VERSION ""

NS_ :

BS_:

BU_: DMC

BO_ 3221225472 VECTOR__INDEPENDENT_SIG_MSG: 0 Vector__XXX
 SG_ Reserved_4 : 0|8@0+ (1,0) [0|0] "" Vector__XXX
 SG_ AdasSignType_reserve : 0|41@0+ (1,0) [0|0] "" Vector__XXX

BO_ 1441 IHU_40: 8 DMC
 SG_ IHU_40_WSOSSwtSet : 5|2@0+ (1,0) [0|3] "" Vector__XXX
 SG_ IHU_40_IDSSwtSet : 7|2@0+ (1,0) [0|3] "" Vector__XXX

BO_ 636 EMS_CGW_1: 8 Vector__XXX
 SG_ EMS_EngineSpeed_Actual : 7|16@0+ (0.25,0) [0|16383] "rpm"  DMC

BO_ 2015 DMC_REQ1_Broadcast: 8 DMC
 SG_ DMC_REQ1_Broadcast : 7|64@0+ (1,0) [0|0] "" Vector__XXX

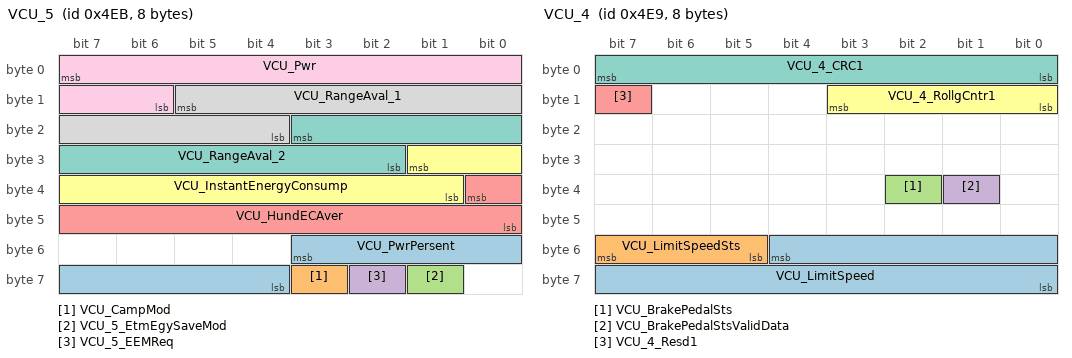
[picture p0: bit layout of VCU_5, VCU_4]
BO_ 1259 VCU_5: 8 Vector__XXX
 SG_ VCU_PwrPersent : 51|8@0+ (1,-100) [-100|100] "%"  DMC
 SG_ VCU_CampMod : 59|1@0+ (1,0) [0|1] ""  DMC
 SG_ VCU_5_EtmEgySaveMod : 57|1@0+ (1,0) [0|1] ""  DMC
 SG_ VCU_5_EEMReq : 58|1@0+ (1,0) [0|1] ""  DMC
 SG_ VCU_HundECAver : 32|9@0+ (0.1,0) [0|51] "kwh"  DMC
 SG_ VCU_InstantEnergyConsump : 25|9@0+ (0.1,0) [0|51] "kwh"  DMC
 SG_ VCU_RangeAval_2 : 19|10@0+ (1,0) [0|1022] "KM"  DMC
 SG_ VCU_RangeAval_1 : 13|10@0+ (1,0) [0|1022] "KM"  DMC
 SG_ VCU_Pwr : 7|10@0+ (1,-500) [-500|500] ""  DMC

BO_ 1257 VCU_4: 8 Vector__XXX
 SG_ VCU_LimitSpeed : 52|13@0+ (0.0625,0) [0|511.875] "km/h"  DMC
 SG_ VCU_LimitSpeedSts : 55|3@0+ (1,0) [0|7] ""  DMC
 SG_ VCU_BrakePedalSts : 34|1@0+ (1,0) [0|1] ""  DMC
 SG_ VCU_BrakePedalStsValidData : 33|1@0+ (1,0) [0|1] ""  DMC
 SG_ VCU_4_Resd1 : 15|1@0+ (1,0) [0|0] ""  DMC
 SG_ VCU_4_RollgCntr1 : 11|4@0+ (1,0) [0|15] ""  DMC
 SG_ VCU_4_CRC1 : 7|8@0+ (1,0) [0|255] ""  DMC

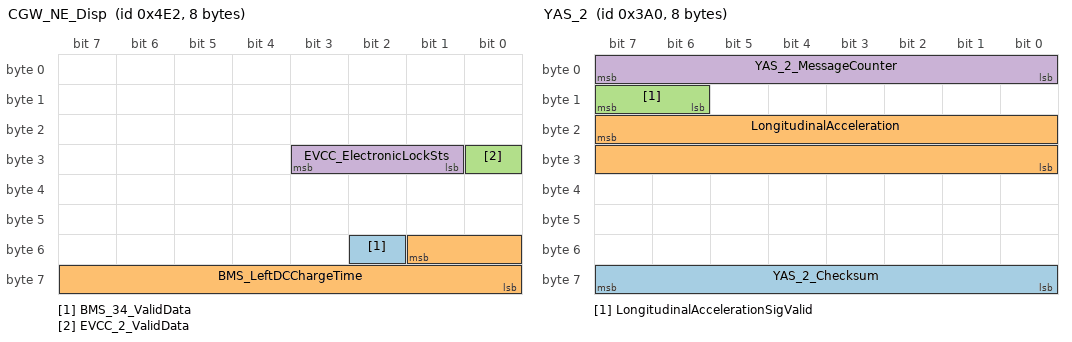
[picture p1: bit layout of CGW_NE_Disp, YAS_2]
BO_ 1250 CGW_NE_Disp: 8 Vector__XXX
 SG_ BMS_34_ValidData : 50|1@0+ (1,0) [0|1] ""  DMC
 SG_ BMS_LeftDCChargeTime : 49|10@0+ (1,0) [0|1022] "min"  DMC
 SG_ EVCC_2_ValidData : 24|1@0+ (1,0) [0|1] ""  DMC
 SG_ EVCC_ElectronicLockSts : 27|3@0+ (1,0) [0|4] ""  DMC

BO_ 928 YAS_2: 8 Vector__XXX
 SG_ YAS_2_Checksum : 63|8@0+ (1,0) [0|255] ""  DMC
 SG_ LongitudinalAcceleration : 23|16@0+ (0.001,-2) [-2|2] "g"  DMC
 SG_ LongitudinalAccelerationSigValid : 15|2@0+ (1,0) [0|3] ""  DMC
 SG_ YAS_2_MessageCounter : 7|8@0+ (1,0) [0|255] ""  DMC

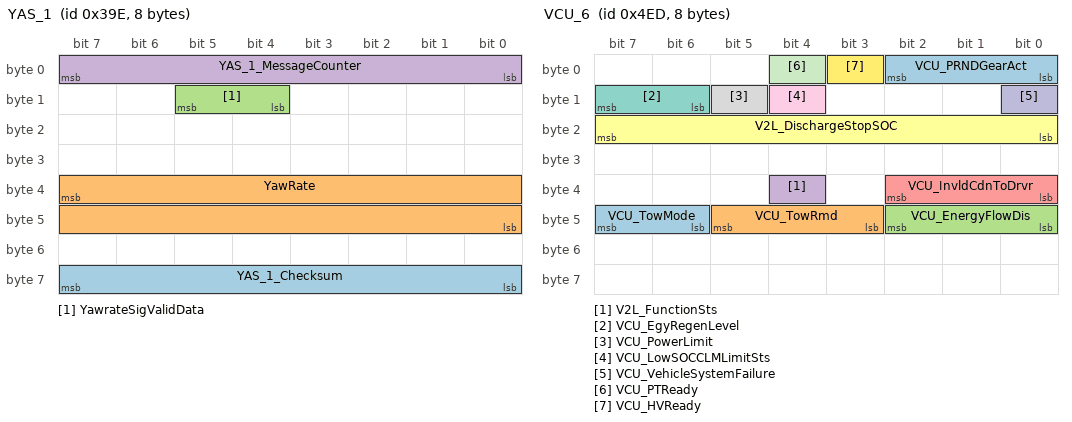
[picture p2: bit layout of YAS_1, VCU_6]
BO_ 926 YAS_1: 8 Vector__XXX
 SG_ YAS_1_Checksum : 63|8@0+ (1,0) [0|255] ""  DMC
 SG_ YawRate : 39|16@0+ (0.01,-180) [-180|180] "deg/sec"  DMC
 SG_ YawrateSigValidData : 13|2@0+ (1,0) [0|3] ""  DMC
 SG_ YAS_1_MessageCounter : 7|8@0+ (1,0) [0|255] ""  DMC

BO_ 1261 VCU_6: 8 Vector__XXX
 SG_ VCU_TowMode : 47|2@0+ (1,0) [0|3] ""  DMC
 SG_ VCU_TowRmd : 45|3@0+ (1,0) [0|7] ""  DMC
 SG_ VCU_EnergyFlowDis : 42|3@0+ (1,0) [0|7] ""  DMC
 SG_ V2L_FunctionSts : 36|1@0+ (1,0) [0|1] ""  DMC
 SG_ VCU_InvldCdnToDrvr : 34|3@0+ (1,0) [0|7] ""  DMC
 SG_ V2L_DischargeStopSOC : 23|8@0+ (1,0) [0|100] "%"  DMC
 SG_ VCU_EgyRegenLevel : 15|2@0+ (1,0) [0|3] ""  DMC
 SG_ VCU_PowerLimit : 13|1@0+ (1,0) [0|1] ""  DMC
 SG_ VCU_LowSOCCLMLimitSts : 12|1@0+ (1,0) [0|1] ""  DMC
 SG_ VCU_VehicleSystemFailure : 8|1@0+ (1,0) [0|1] ""  DMC
 SG_ VCU_PTReady : 4|1@0+ (1,0) [0|1] ""  DMC
 SG_ VCU_HVReady : 3|1@0+ (1,0) [0|1] ""  DMC
 SG_ VCU_PRNDGearAct : 2|3@0+ (1,0) [0|7] ""  DMC

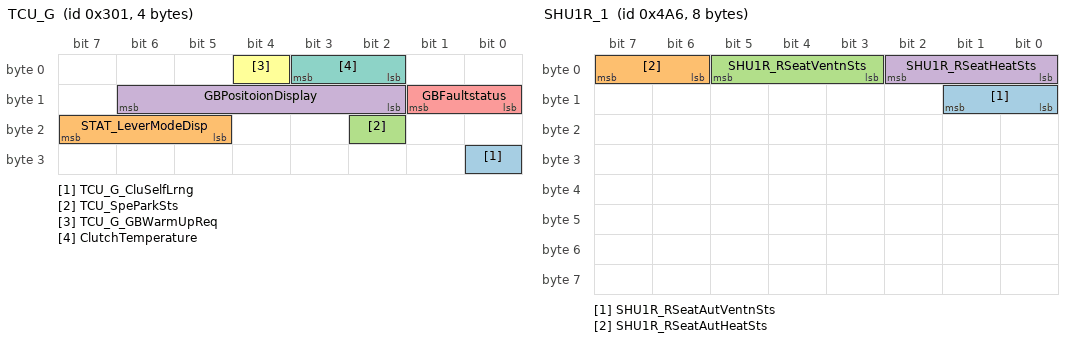
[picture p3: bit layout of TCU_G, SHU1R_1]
BO_ 769 TCU_G: 4 Vector__XXX
 SG_ TCU_G_CluSelfLrng : 24|1@0+ (1,0) [0|1] ""  DMC
 SG_ STAT_LeverModeDisp : 23|3@0+ (1,0) [0|7] ""  DMC
 SG_ TCU_SpeParkSts : 18|1@0+ (1,0) [0|1] ""  DMC
 SG_ GBPositoionDisplay : 14|5@0+ (1,0) [0|31] ""  DMC
 SG_ GBFaultstatus : 9|2@0+ (1,0) [0|3] ""  DMC
 SG_ TCU_G_GBWarmUpReq : 4|1@0+ (1,0) [0|1] ""  DMC
 SG_ ClutchTemperature : 3|2@0+ (1,0) [0|3] ""  DMC

BO_ 1206 SHU2R_1: 8 Vector__XXX
 SG_ SHU2R_RSeatVentnSts : 5|3@0+ (1,0) [0|7] ""  DMC
 SG_ SHU2R_RSeatHeatSts : 2|3@0+ (1,0) [0|7] ""  DMC

BO_ 1202 SHU2M_1: 8 Vector__XXX
 SG_ SHU2M_MSeatVentnSts : 5|3@0+ (1,0) [0|7] ""  DMC
 SG_ SHU2M_MSeatHeatSts : 2|3@0+ (1,0) [0|7] ""  DMC

BO_ 1194 SHU2L_1: 8 Vector__XXX
 SG_ SHU2L_LSeatVentnSts : 5|3@0+ (1,0) [0|7] ""  DMC
 SG_ SHU2L_LSeatHeatSts : 2|3@0+ (1,0) [0|7] ""  DMC

BO_ 1190 SHU1R_1: 8 Vector__XXX
 SG_ SHU1R_RSeatAutVentnSts : 9|2@0+ (1,0) [0|3] ""  DMC
 SG_ SHU1R_RSeatAutHeatSts : 7|2@0+ (1,0) [0|3] ""  DMC
 SG_ SHU1R_RSeatVentnSts : 5|3@0+ (1,0) [0|7] ""  DMC
 SG_ SHU1R_RSeatHeatSts : 2|3@0+ (1,0) [0|7] ""  DMC

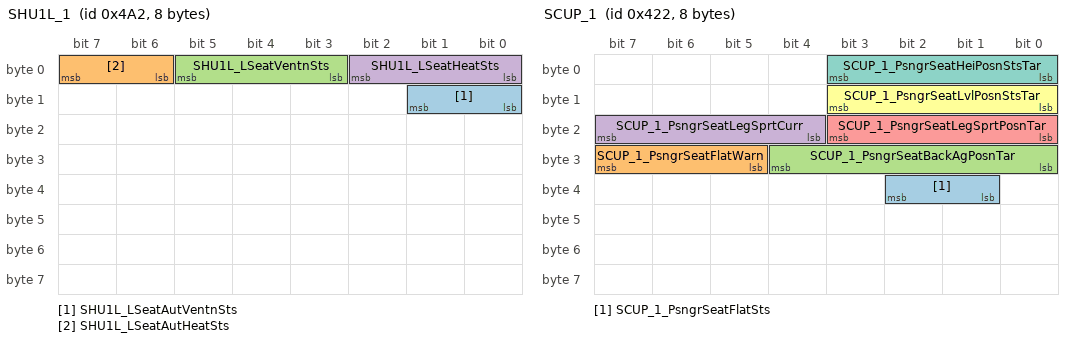
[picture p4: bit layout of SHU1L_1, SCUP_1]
BO_ 1186 SHU1L_1: 8 Vector__XXX
 SG_ SHU1L_LSeatAutVentnSts : 9|2@0+ (1,0) [0|3] ""  DMC
 SG_ SHU1L_LSeatAutHeatSts : 7|2@0+ (1,0) [0|3] ""  DMC
 SG_ SHU1L_LSeatVentnSts : 5|3@0+ (1,0) [0|7] ""  DMC
 SG_ SHU1L_LSeatHeatSts : 2|3@0+ (1,0) [0|7] ""  DMC

BO_ 1129 SCUP_2: 8 Vector__XXX
 SG_ SCUP_2_PsngrSeatMemSts : 15|2@0+ (1,0) [0|3] ""  DMC
 SG_ SCUP_2_PsngrSeatMemReq : 1|2@0+ (1,0) [0|3] ""  DMC

BO_ 1058 SCUP_1: 8 Vector__XXX
 SG_ SCUP_1_PsngrSeatFlatSts : 34|2@0+ (1,0) [0|3] ""  DMC
 SG_ SCUP_1_PsngrSeatFlatWarn : 31|3@0+ (1,0) [0|7] ""  DMC
 SG_ SCUP_1_PsngrSeatBackAgPosnTar : 28|5@0+ (1,0) [0|31] ""  DMC
 SG_ SCUP_1_PsngrSeatLegSprtCurr : 23|4@0+ (1,0) [0|15] ""  DMC
 SG_ SCUP_1_PsngrSeatLegSprtPosnTar : 19|4@0+ (1,0) [0|15] ""  DMC
 SG_ SCUP_1_PsngrSeatLvlPosnStsTar : 11|4@0+ (1,0) [0|15] ""  DMC
 SG_ SCUP_1_PsngrSeatHeiPosnStsTar : 3|4@0+ (1,0) [0|15] ""  DMC

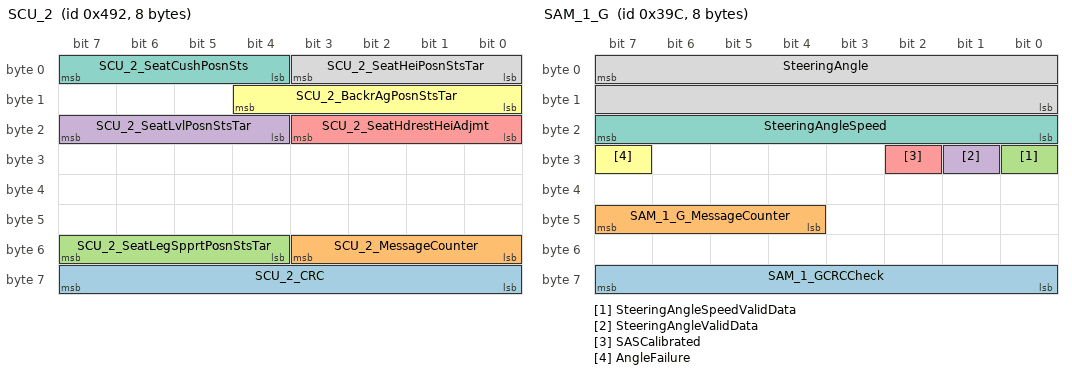
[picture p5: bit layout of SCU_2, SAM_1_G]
BO_ 1170 SCU_2: 8 Vector__XXX
 SG_ SCU_2_CRC : 63|8@0+ (1,0) [0|255] ""  DMC
 SG_ SCU_2_MessageCounter : 51|4@0+ (1,0) [0|15] ""  DMC
 SG_ SCU_2_SeatLegSpprtPosnStsTar : 55|4@0+ (1,0) [0|15] ""  DMC
 SG_ SCU_2_SeatLvlPosnStsTar : 23|4@0+ (1,0) [0|15] ""  DMC
 SG_ SCU_2_SeatHdrestHeiAdjmt : 19|4@0+ (1,0) [0|15] ""  DMC
 SG_ SCU_2_BackrAgPosnStsTar : 12|5@0+ (1,0) [0|31] ""  DMC
 SG_ SCU_2_SeatCushPosnSts : 7|4@0+ (1,0) [0|15] ""  DMC
 SG_ SCU_2_SeatHeiPosnStsTar : 3|4@0+ (1,0) [0|15] ""  DMC

BO_ 924 SAM_1_G: 8 Vector__XXX
 SG_ SAM_1_GCRCCheck : 63|8@0+ (1,0) [0|255] ""  DMC
 SG_ SAM_1_G_MessageCounter : 47|4@0+ (1,0) [0|15] ""  DMC
 SG_ SteeringAngleSpeedValidData : 24|1@0+ (1,0) [0|1] ""  DMC
 SG_ SteeringAngleValidData : 25|1@0+ (1,0) [0|1] ""  DMC
 SG_ SASCalibrated : 26|1@0+ (1,0) [0|1] ""  DMC
 SG_ AngleFailure : 31|1@0+ (1,0) [0|1] ""  DMC
 SG_ SteeringAngleSpeed : 23|8@0+ (4,0) [0|1016] "deg/Sec"  DMC
 SG_ SteeringAngle : 7|16@0+ (0.0625,-2048) [-2048|2047.875] "deg"  DMC

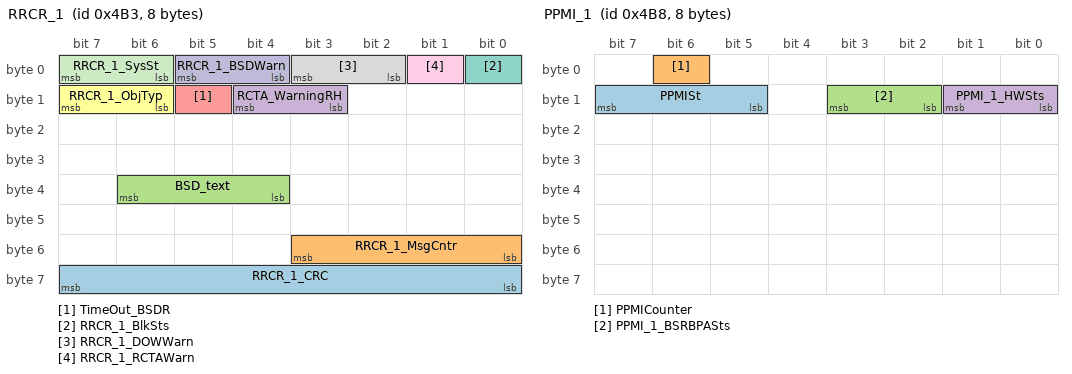
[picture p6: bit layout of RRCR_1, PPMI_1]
BO_ 1203 RRCR_1: 8 Vector__XXX
 SG_ RRCR_1_CRC : 63|8@0+ (1,0) [0|255] ""  DMC
 SG_ RRCR_1_MsgCntr : 51|4@0+ (1,0) [0|15] ""  DMC
 SG_ BSD_text : 38|3@0+ (1,0) [0|7] ""  DMC
 SG_ RCTA_WarningRH : 12|2@0+ (1,0) [0|3] ""  DMC
 SG_ TimeOut_BSDR : 13|1@0+ (1,0) [0|1] ""  DMC
 SG_ RRCR_1_ObjTyp : 15|2@0+ (1,0) [0|3] ""  DMC
 SG_ RRCR_1_BlkSts : 0|1@0+ (1,0) [0|1] ""  DMC
 SG_ RRCR_1_DOWWarn : 3|2@0+ (1,0) [0|3] ""  DMC
 SG_ RRCR_1_RCTAWarn : 1|1@0+ (1,0) [0|1] ""  DMC
 SG_ RRCR_1_BSDWarn : 5|2@0+ (1,0) [0|3] ""  DMC
 SG_ RRCR_1_SysSt : 7|2@0+ (1,0) [0|3] ""  DMC

BO_ 1075 RLCR_2_G: 8 Vector__XXX
 SG_ RLCR_2_RCTBONOFFSts : 5|2@0+ (1,0) [0|3] ""  DMC
 SG_ RLCR_2_RAEBONOFFSts : 3|2@0+ (1,0) [0|3] ""  DMC

BO_ 1201 RLCR_1: 8 Vector__XXX
 SG_ RLCR_1_CRC : 63|8@0+ (1,0) [0|255] ""  DMC
 SG_ RLCR_1_MsgCntr : 51|4@0+ (1,0) [0|15] ""  DMC
 SG_ STAT_RCTBEnable : 47|2@0+ (1,0) [0|3] ""  DMC
 SG_ DOW_Status : 45|3@0+ (1,0) [0|7] ""  DMC
 SG_ RCW_Status : 55|3@0+ (1,0) [0|7] ""  DMC
 SG_ STAT_DOWWarningMode : 35|2@0+ (1,0) [0|3] ""  DMC
 SG_ STAT_CVWWarningMode : 37|2@0+ (1,0) [0|3] ""  DMC
 SG_ RCTA_WarningLH : 39|2@0+ (1,0) [0|3] ""  DMC
 SG_ CVW_Warning : 33|2@0+ (1,0) [0|3] ""  DMC
 SG_ CVW_Status : 42|3@0+ (1,0) [0|7] ""  DMC
 SG_ BSD_Status : 31|3@0+ (1,0) [0|7] ""  DMC
 SG_ RCTA_Status : 26|3@0+ (1,0) [0|7] ""  DMC
 SG_ STAT_RCWWarningMode : 28|2@0+ (1,0) [0|3] ""  DMC
 SG_ STAT_BSDWarningMode : 17|2@0+ (1,0) [0|3] ""  DMC
 SG_ RLCR_1_ObjTyp : 9|2@0+ (1,0) [0|3] ""  DMC
 SG_ RLCR_1_RCWWarn : 11|2@0+ (1,0) [0|3] ""  DMC
 SG_ RLCR_1_DOWWarn : 13|2@0+ (1,0) [0|3] ""  DMC
 SG_ RLCR_1_RCWONOFFSts : 19|2@0+ (1,0) [0|3] ""  DMC
 SG_ RLCR_1_DOWONOFFSts : 21|2@0+ (1,0) [0|3] ""  DMC
 SG_ RLCR_1_BSDLCARCTAONOFFSts : 23|2@0+ (1,0) [0|3] ""  DMC
 SG_ RLCR_1_RCTAWarn : 0|1@0+ (1,0) [0|1] ""  DMC
 SG_ RLCR_1_BlkSts : 1|1@0+ (1,0) [0|1] ""  DMC
 SG_ RLCR_1_RAEBWarn : 4|1@0+ (1,0) [0|1] ""  DMC
 SG_ RLCR_1_RCTBWarn : 5|1@0+ (1,0) [0|1] ""  DMC
 SG_ RLCR_1_BSDWarn : 15|2@0+ (1,0) [0|3] ""  DMC
 SG_ RLCR_1_SysSt : 7|2@0+ (1,0) [0|3] ""  DMC

BO_ 1032 RCCP_1: 8 Vector__XXX
 SG_ RCCP_1_InhbSts : 7|1@0+ (1,0) [0|1] ""  DMC

BO_ 1208 PPMI_1: 8 Vector__XXX
 SG_ PPMISt : 15|3@0+ (1,0) [0|7] ""  DMC
 SG_ PPMICounter : 6|1@0+ (1,0) [0|1] ""  DMC
 SG_ PPMI_1_BSRBPASts : 11|2@0+ (1,0) [0|3] ""  DMC
 SG_ PPMI_1_HWSts : 9|2@0+ (1,0) [0|3] ""  DMC

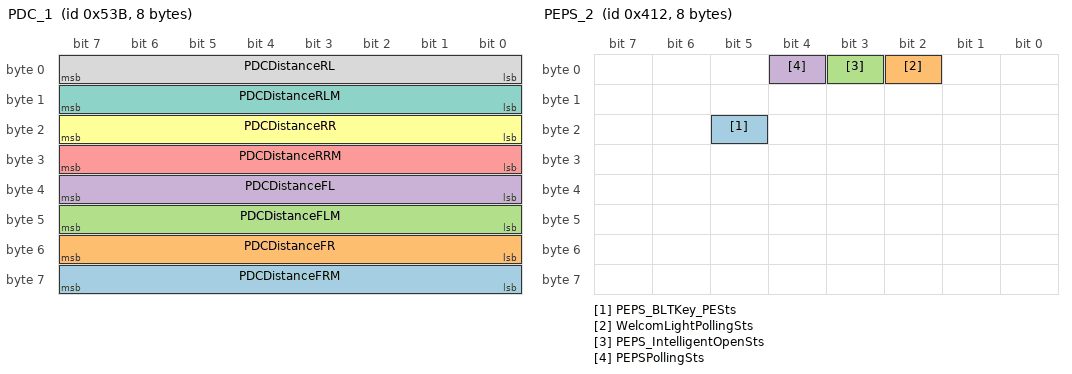
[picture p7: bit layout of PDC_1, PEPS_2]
BO_ 1339 PDC_1: 8 Vector__XXX
 SG_ PDCDistanceFRM : 63|8@0+ (1,0) [0|255] "cm"  DMC
 SG_ PDCDistanceFR : 55|8@0+ (1,0) [0|255] "cm"  DMC
 SG_ PDCDistanceFLM : 47|8@0+ (1,0) [0|255] "cm"  DMC
 SG_ PDCDistanceFL : 39|8@0+ (1,0) [0|255] "cm"  DMC
 SG_ PDCDistanceRRM : 31|8@0+ (1,0) [0|255] "cm"  DMC
 SG_ PDCDistanceRR : 23|8@0+ (1,0) [0|255] "cm"  DMC
 SG_ PDCDistanceRLM : 15|8@0+ (1,0) [0|255] "cm"  DMC
 SG_ PDCDistanceRL : 7|8@0+ (1,0) [0|255] "cm"  DMC

BO_ 1042 PEPS_2: 8 Vector__XXX
 SG_ PEPS_BLTKey_PESts : 21|1@0+ (1,0) [0|1] ""  DMC
 SG_ WelcomLightPollingSts : 2|1@0+ (1,0) [0|1] ""  DMC
 SG_ PEPS_IntelligentOpenSts : 3|1@0+ (1,0) [0|1] ""  DMC
 SG_ PEPSPollingSts : 4|1@0+ (1,0) [0|1] ""  DMC

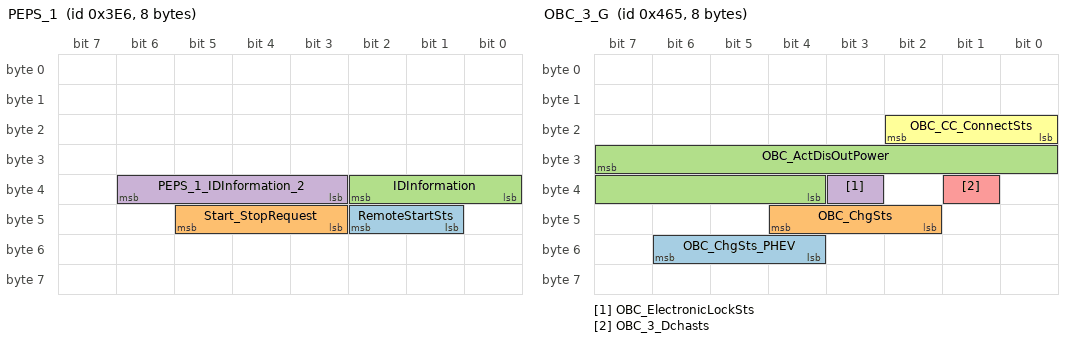
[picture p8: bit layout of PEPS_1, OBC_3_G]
BO_ 998 PEPS_1: 8 Vector__XXX
 SG_ RemoteStartSts : 42|2@0+ (1,0) [0|3] ""  DMC
 SG_ Start_StopRequest : 45|3@0+ (1,0) [0|7] ""  DMC
 SG_ IDInformation : 34|3@0+ (1,0) [0|7] ""  DMC
 SG_ PEPS_1_IDInformation_2 : 38|4@0+ (1,0) [0|10] ""  DMC

BO_ 1125 OBC_3_G: 8 Vector__XXX
 SG_ OBC_ChgSts_PHEV : 54|3@0+ (1,0) [0|7] ""  DMC
 SG_ OBC_ChgSts : 44|3@0+ (1,0) [0|7] ""  DMC
 SG_ OBC_ActDisOutPower : 31|12@0+ (0.1,0) [0|400] "KW"  DMC
 SG_ OBC_ElectronicLockSts : 35|1@0+ (1,0) [0|1] ""  DMC
 SG_ OBC_3_Dchasts : 33|1@0+ (1,0) [0|1] ""  DMC
 SG_ OBC_CC_ConnectSts : 18|3@0+ (1,0) [0|7] ""  DMC

BO_ 1124 NFC_1: 8 Vector__XXX
 SG_ NFC_1_DispCardPosn : 15|1@0+ (1,0) [0|1] ""  DMC
 SG_ NFC_1_IDList : 7|3@0+ (1,0) [0|7] ""  DMC
 SG_ NFC_1_ID : 4|3@0+ (1,0) [0|7] ""  DMC

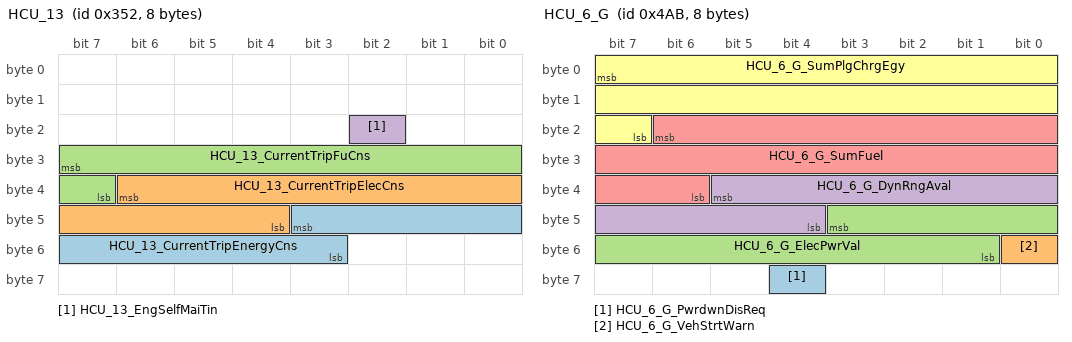
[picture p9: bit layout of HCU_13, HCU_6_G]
BO_ 850 HCU_13: 8 Vector__XXX
 SG_ HCU_13_CurrentTripEnergyCns : 43|9@0+ (0.1,-25) [-25|25] "L/100km"  DMC
 SG_ HCU_13_CurrentTripElecCns : 38|11@0+ (0.1,-100) [-100|100] "kW.h/100km"  DMC
 SG_ HCU_13_CurrentTripFuCns : 31|9@0+ (0.1,0) [0|50] "L/100km"  DMC
 SG_ HCU_13_EngSelfMaiTin : 18|1@0+ (1,0) [0|1] ""  DMC

BO_ 1195 HCU_6_G: 8 Vector__XXX
 SG_ HCU_6_G_PwrdwnDisReq : 60|1@0+ (1,0) [0|1] ""  DMC
 SG_ HCU_6_G_VehStrtWarn : 48|1@0+ (1,0) [0|1] ""  DMC
 SG_ HCU_6_G_ElecPwrVal : 43|11@0+ (1,-1000) [-1000|1000] "Kw"  DMC
 SG_ HCU_6_G_DynRngAval : 37|10@0+ (1,0) [0|1022] "KM"  DMC
 SG_ HCU_6_G_SumFuel : 22|17@0+ (0.1,0) [0|9999.9] "L"  DMC
 SG_ HCU_6_G_SumPlgChrgEgy : 7|17@0+ (0.1,0) [0|9999.9] "Kwh"  DMC

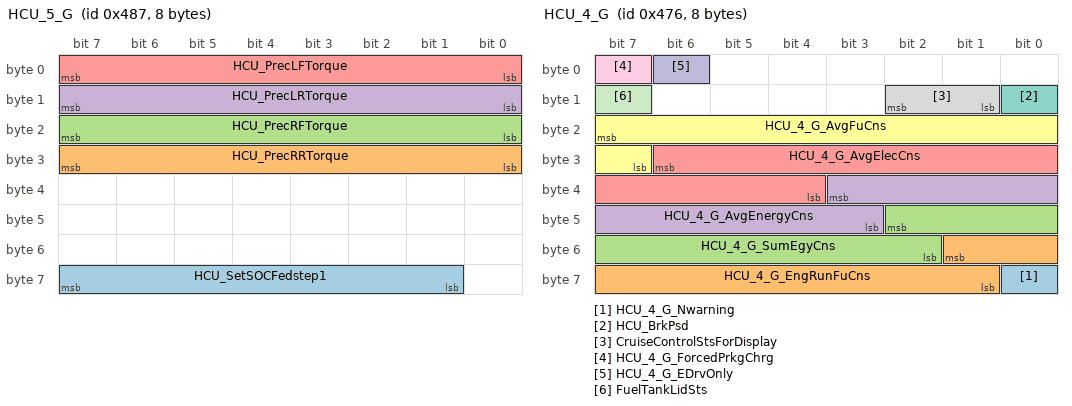
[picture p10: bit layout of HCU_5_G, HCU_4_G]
BO_ 1159 HCU_5_G: 8 Vector__XXX
 SG_ HCU_SetSOCFedstep1 : 63|7@0+ (1,0) [0|100] "%"  DMC
 SG_ HCU_PrecRRTorque : 31|8@0+ (1,-100) [-100|100] "%"  DMC
 SG_ HCU_PrecRFTorque : 23|8@0+ (1,-100) [-100|100] "%"  DMC
 SG_ HCU_PrecLRTorque : 15|8@0+ (1,-100) [-100|100] "%"  DMC
 SG_ HCU_PrecLFTorque : 7|8@0+ (1,-100) [-100|100] "%"  DMC

BO_ 1142 HCU_4_G: 8 Vector__XXX
 SG_ HCU_4_G_Nwarning : 56|1@0+ (1,0) [0|1] ""  DMC
 SG_ HCU_4_G_EngRunFuCns : 49|9@0+ (0.1,0) [0|50] "L/km"  DMC
 SG_ HCU_4_G_SumEgyCns : 42|9@0+ (0.1,-25) [-25|25] "L/km"  DMC
 SG_ HCU_4_G_AvgEnergyCns : 35|9@0+ (0.1,-25) [-25|25] "L/km"  DMC
 SG_ HCU_4_G_AvgElecCns : 30|11@0+ (0.1,-100) [-100|100] "kW.h/km"  DMC
 SG_ HCU_4_G_AvgFuCns : 23|9@0+ (0.1,0) [0|50] "L/km"  DMC
 SG_ HCU_BrkPsd : 8|1@0+ (1,0) [0|1] ""  DMC
 SG_ CruiseControlStsForDisplay : 10|2@0+ (1,0) [0|3] ""  DMC
 SG_ HCU_4_G_ForcedPrkgChrg : 7|1@0+ (1,0) [0|1] ""  DMC
 SG_ HCU_4_G_EDrvOnly : 6|1@0+ (1,0) [0|1] ""  DMC
 SG_ FuelTankLidSts : 15|1@0+ (1,0) [0|1] ""  DMC

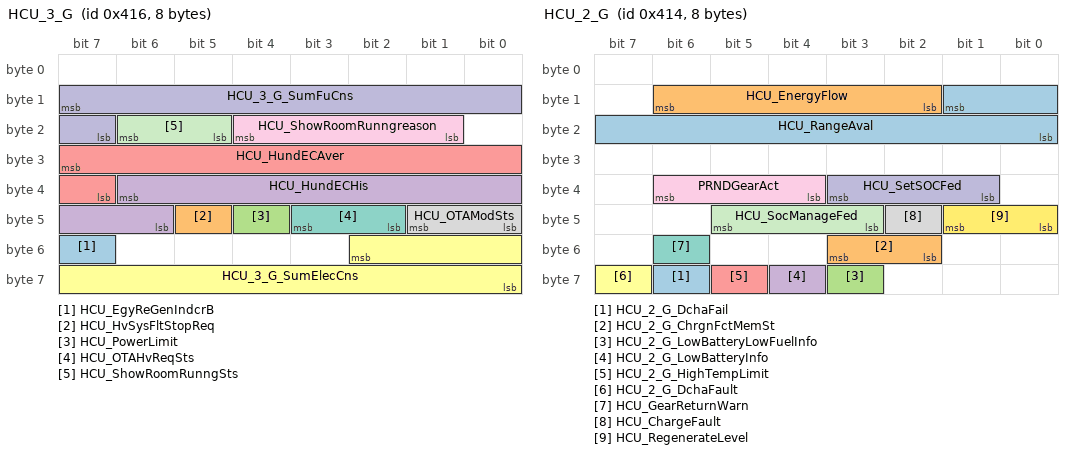
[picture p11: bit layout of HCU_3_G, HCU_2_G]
BO_ 1046 HCU_3_G: 8 Vector__XXX
 SG_ HCU_EgyReGenIndcrB : 55|1@0+ (1,0) [0|1] ""  DMC
 SG_ HCU_HvSysFltStopReq : 45|1@0+ (1,0) [0|1] ""  DMC
 SG_ HCU_PowerLimit : 44|1@0+ (1,0) [0|1] ""  DMC
 SG_ HCU_HundECHis : 38|9@0+ (0.1,0) [0|51] "kwh"  DMC
 SG_ HCU_HundECAver : 31|9@0+ (0.1,0) [0|51] "kwh"  DMC
 SG_ HCU_3_G_SumElecCns : 50|11@0+ (0.1,-100) [-100|100] "kW.h/100km"  DMC
 SG_ HCU_OTAHvReqSts : 43|2@0+ (1,0) [0|3] ""  DMC
 SG_ HCU_OTAModSts : 41|2@0+ (1,0) [0|2] ""  DMC
 SG_ HCU_ShowRoomRunngreason : 20|4@0+ (1,0) [0|2] ""  DMC
 SG_ HCU_3_G_SumFuCns : 15|9@0+ (0.1,0) [0|50] "L/100km"  DMC
 SG_ HCU_ShowRoomRunngSts : 22|2@0+ (1,0) [0|3] ""  DMC

BO_ 1044 HCU_2_G: 8 Vector__XXX
 SG_ HCU_2_G_DchaFail : 62|1@0+ (1,0) [0|1] ""  DMC
 SG_ HCU_2_G_ChrgnFctMemSt : 51|2@0+ (1,0) [0|3] ""  DMC
 SG_ HCU_2_G_LowBatteryLowFuelInfo : 59|1@0+ (1,0) [0|1] ""  DMC
 SG_ HCU_2_G_LowBatteryInfo : 60|1@0+ (1,0) [0|1] ""  DMC
 SG_ HCU_2_G_HighTempLimit : 61|1@0+ (1,0) [0|1] ""  DMC
 SG_ HCU_2_G_DchaFault : 63|1@0+ (1,0) [0|1] ""  DMC
 SG_ HCU_GearReturnWarn : 54|1@0+ (1,0) [0|1] ""  DMC
 SG_ HCU_ChargeFault : 42|1@0+ (1,0) [0|1] ""  DMC
 SG_ PRNDGearAct : 38|3@0+ (1,0) [0|7] ""  DMC
 SG_ HCU_SetSOCFed : 35|3@0+ (1,0) [0|7] ""  DMC
 SG_ HCU_SocManageFed : 45|3@0+ (1,0) [0|7] ""  DMC
 SG_ HCU_RegenerateLevel : 41|2@0+ (1,0) [0|3] ""  DMC
 SG_ HCU_RangeAval : 9|10@0+ (1,0) [0|1022] "KM"  DMC
 SG_ HCU_EnergyFlow : 14|5@0+ (1,0) [0|31] ""  DMC

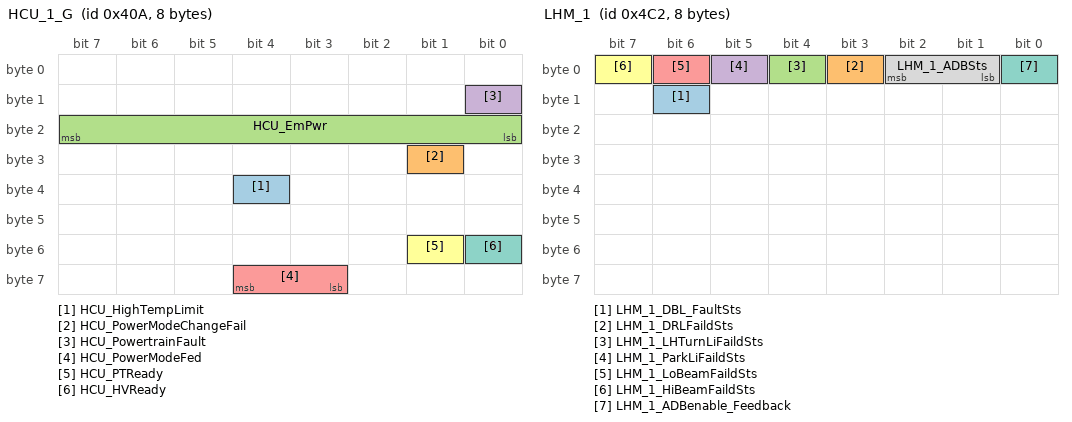
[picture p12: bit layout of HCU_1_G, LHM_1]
BO_ 1034 HCU_1_G: 8 Vector__XXX
 SG_ HCU_HighTempLimit : 36|1@0+ (1,0) [0|1] ""  DMC
 SG_ HCU_PowerModeChangeFail : 25|1@0+ (1,0) [0|1] ""  DMC
 SG_ HCU_EmPwr : 23|8@0+ (1,-128) [-100|100] "%"  DMC
 SG_ HCU_PowertrainFault : 8|1@0+ (1,0) [0|1] ""  DMC
 SG_ HCU_PowerModeFed : 60|2@0+ (1,0) [0|3] ""  DMC
 SG_ HCU_PTReady : 49|1@0+ (1,0) [0|1] ""  DMC
 SG_ HCU_HVReady : 48|1@0+ (1,0) [0|1] ""  DMC

BO_ 1218 LHM_1: 8 Vector__XXX
 SG_ LHM_1_DBL_FaultSts : 14|1@0+ (1,0) [0|1] ""  DMC
 SG_ LHM_1_DRLFaildSts : 3|1@0+ (1,0) [0|1] ""  DMC
 SG_ LHM_1_LHTurnLiFaildSts : 4|1@0+ (1,0) [0|1] ""  DMC
 SG_ LHM_1_ParkLiFaildSts : 5|1@0+ (1,0) [0|1] ""  DMC
 SG_ LHM_1_LoBeamFaildSts : 6|1@0+ (1,0) [0|1] ""  DMC
 SG_ LHM_1_HiBeamFaildSts : 7|1@0+ (1,0) [0|1] ""  DMC
 SG_ LHM_1_ADBenable_Feedback : 0|1@0+ (1,0) [0|1] ""  DMC
 SG_ LHM_1_ADBSts : 2|2@0+ (1,0) [0|3] ""  DMC

BO_ 1175 IPB_ESP_15: 8 Vector__XXX
 SG_ IPB_ESP_15_CRC : 63|8@0+ (1,0) [0|255] ""  DMC
 SG_ IPB_ESP_15_MessageCounter : 51|4@0+ (1,0) [0|15] ""  DMC
 SG_ Reserved_Fill7 : 55|4@0+ (1,0) [0|0] ""  DMC
 SG_ BrakesystemFailSts : 2|1@0+ (1,0) [0|1] ""  DMC
 SG_ TwofeetBrakeSts : 3|1@0+ (1,0) [0|1] ""  DMC
 SG_ BrakeFluidSts : 5|2@0+ (1,0) [0|3] ""  DMC
 SG_ FWAWarningSts : 7|2@0+ (1,0) [0|3] ""  DMC
 SG_ Reserved_Fill2 : 9|2@0+ (1,0) [0|0] ""  DMC
 SG_ CST_SensitivitySts : 11|2@0+ (1,0) [0|3] ""  DMC
 SG_ BrakepedalFeelSts : 13|2@0+ (1,0) [0|3] ""  DMC
 SG_ CST_Status : 15|2@0+ (1,0) [0|3] ""  DMC
 SG_ Reserved_Fill6 : 47|8@0+ (1,0) [0|0] ""  DMC
 SG_ Reserved_Fill5 : 39|8@0+ (1,0) [0|0] ""  DMC
 SG_ Reserved_Fill4 : 31|8@0+ (1,0) [0|0] ""  DMC
 SG_ Reserved_Fill3 : 23|8@0+ (1,0) [0|0] ""  DMC
 SG_ IPB_AssociWithDriverModeSts : 1|1@0+ (1,0) [0|1] ""  DMC
 SG_ Reserved_Fill1 : 0|1@0+ (1,0) [0|0] ""  DMC

BO_ 1149 IMMO_12: 8 Vector__XXX
 SG_ IMMO_Teach : 7|64@0+ (1,0) [0|0] ""  DMC

BO_ 1110 IMMO_11: 8 Vector__XXX
 SG_ IMMO_Chall : 7|64@0+ (1,0) [0|0] ""  DMC

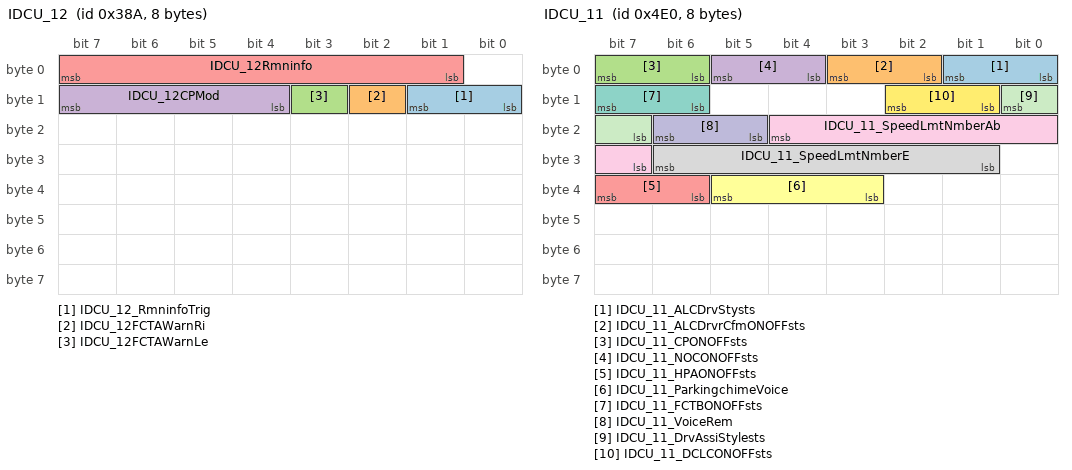
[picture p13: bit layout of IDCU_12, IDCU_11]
BO_ 906 IDCU_12: 8 Vector__XXX
 SG_ IDCU_12_RmninfoTrig : 9|2@0+ (1,0) [0|3] ""  DMC
 SG_ IDCU_12FCTAWarnRi : 10|1@0+ (1,0) [0|1] ""  DMC
 SG_ IDCU_12FCTAWarnLe : 11|1@0+ (1,0) [0|1] ""  DMC
 SG_ IDCU_12CPMod : 15|4@0+ (1,0) [0|15] ""  DMC
 SG_ IDCU_12Rmninfo : 7|7@0+ (1,0) [0|127] ""  DMC

BO_ 1248 IDCU_11: 8 Vector__XXX
 SG_ IDCU_11_ALCDrvStysts : 1|2@0+ (1,0) [0|3] ""  DMC
 SG_ IDCU_11_ALCDrvrCfmONOFFsts : 3|2@0+ (1,0) [0|3] ""  DMC
 SG_ IDCU_11_CPONOFFsts : 7|2@0+ (1,0) [0|3] ""  DMC
 SG_ IDCU_11_NOCONOFFsts : 5|2@0+ (1,0) [0|3] ""  DMC
 SG_ IDCU_11_HPAONOFFsts : 39|2@0+ (1,0) [0|3] ""  DMC
 SG_ IDCU_11_ParkingchimeVoice : 37|3@0+ (1,0) [0|7] ""  DMC
 SG_ IDCU_11_FCTBONOFFsts : 15|2@0+ (1,0) [0|3] ""  DMC
 SG_ IDCU_11_SpeedLmtNmberE : 30|6@0+ (1,0) [0|63] ""  DMC
 SG_ IDCU_11_SpeedLmtNmberAb : 20|6@0+ (1,0) [0|63] ""  DMC
 SG_ IDCU_11_VoiceRem : 22|2@0+ (1,0) [0|3] ""  DMC
 SG_ IDCU_11_DrvAssiStylests : 8|2@0+ (1,0) [0|3] ""  DMC
 SG_ IDCU_11_DCLCONOFFsts : 10|2@0+ (1,0) [0|3] ""  DMC

BO_ 903 FCM_FRM_6: 8 Vector__XXX
 SG_ FCM_FRM_6_SCF_Indicator : 33|2@0+ (1,0) [0|3] ""  DMC
 SG_ FCM_FRM_6_Textinfo_Info_2 : 15|4@0+ (1,0) [0|15] ""  DMC
 SG_ FCM_FRM_6_VSetDis : 44|9@0+ (0.5,0) [0|255.5] "KPH"  DMC
 SG_ FCM_FRM_6_AEBMode : 27|3@0+ (1,0) [0|4] ""  DMC
 SG_ FCM_FRM_6_FCWMode : 30|3@0+ (1,0) [0|4] ""  DMC
 SG_ FCM_FRM_6_HMI_Indicator : 39|2@0+ (1,0) [0|3] ""  DMC
 SG_ FCM_FRM_6_TakeOverReq : 31|1@0+ (1,0) [0|1] ""  DMC
 SG_ FCM_FRM_6_FCW_preWarning : 16|1@0+ (1,0) [0|1] ""  DMC
 SG_ FCM_FRM_6_DistanceWarning : 17|1@0+ (1,0) [0|1] ""  DMC
 SG_ FCM_FRM_6_TimeGapSetICM : 11|3@0+ (1,0) [0|7] ""  DMC
 SG_ FCM_FRM_6_DrvrCfmSCFDispFb : 18|1@0+ (1,0) [0|1] ""  DMC
 SG_ FCM_FRM_6_SCF_SpdLimUnit : 20|2@0+ (1,0) [0|3] ""  DMC
 SG_ FCM_FRM_6_SCF_SpdLimSts : 23|3@0+ (1,0) [0|7] ""  DMC
 SG_ FCM_FRM_6_SCF_PopoverReq : 8|1@0+ (1,0) [0|1] ""  DMC
 SG_ FCM_FRM_6_ACCMode : 37|4@0+ (1,0) [0|15] ""  DMC
 SG_ FCM_FRM_6_Textinfo_Info : 7|4@0+ (1,0) [0|15] ""  DMC
 SG_ FCM_FRM_6_TextinfoWarn : 3|4@0+ (1,0) [0|15] ""  DMC

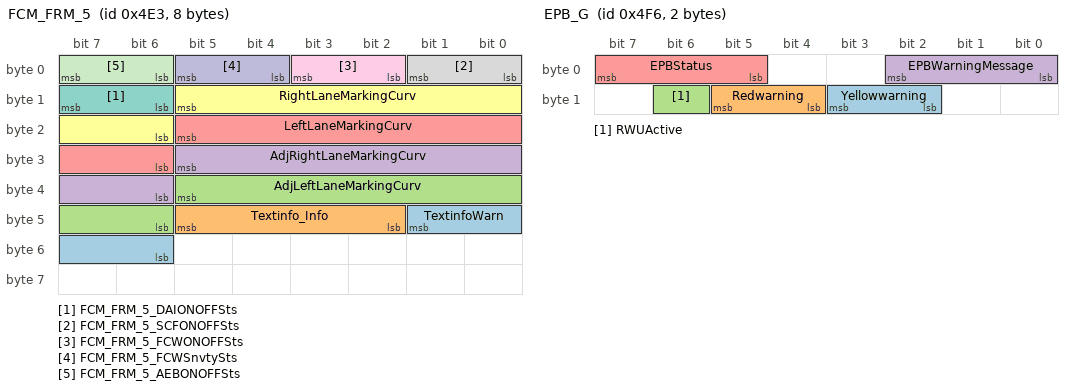
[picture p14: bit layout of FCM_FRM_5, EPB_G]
BO_ 1251 FCM_FRM_5: 8 Vector__XXX
 SG_ TextinfoWarn : 41|4@0+ (1,0) [0|15] ""  DMC
 SG_ Textinfo_Info : 45|4@0+ (1,0) [0|15] ""  DMC
 SG_ AdjLeftLaneMarkingCurv : 37|8@0+ (0.001,-0.125) [-0.125|0.125] "1/m"  DMC
 SG_ AdjRightLaneMarkingCurv : 29|8@0+ (0.001,-0.125) [-0.125|0.125] "1/m"  DMC
 SG_ LeftLaneMarkingCurv : 21|8@0+ (0.001,-0.125) [-0.125|0.125] "1/m"  DMC
 SG_ RightLaneMarkingCurv : 13|8@0+ (0.001,-0.125) [-0.125|0.125] "1/m"  DMC
 SG_ FCM_FRM_5_DAIONOFFSts : 15|2@0+ (1,0) [0|3] ""  DMC
 SG_ FCM_FRM_5_SCFONOFFSts : 1|2@0+ (1,0) [0|3] ""  DMC
 SG_ FCM_FRM_5_FCWONOFFSts : 3|2@0+ (1,0) [0|3] ""  DMC
 SG_ FCM_FRM_5_FCWSnvtySts : 5|2@0+ (1,0) [0|3] ""  DMC
 SG_ FCM_FRM_5_AEBONOFFSts : 7|2@0+ (1,0) [0|3] ""  DMC

BO_ 1020 FCM_10: 8 Vector__XXX
 SG_ FCM_10_EgoLeftLineHeatgAg : 44|9@0+ (0.004,-1.02) [-1.02|1.02] "Rad"  DMC
 SG_ FCM_10_ELKIntvMod : 47|3@0+ (1,0) [0|7] ""  DMC
 SG_ FCM_10_WarnModSts : 33|2@0+ (1,0) [0|3] ""  DMC
 SG_ FCM_10_SLAONOFFSts : 35|2@0+ (1,0) [0|3] ""  DMC
 SG_ FCM_10_TJAICAExitTextInfoSts : 37|2@0+ (1,0) [0|3] ""  DMC
 SG_ FCM_10_LDPTJAELKTakeoverReq : 39|2@0+ (1,0) [0|3] ""  DMC
 SG_ FCM_10_TSINoParkWarn : 28|1@0+ (1,0) [0|1] ""  DMC
 SG_ FCM_10_ELKSysSts : 31|3@0+ (1,0) [0|7] ""  DMC
 SG_ FCM_10_TJAICAEnaRcmend : 24|1@0+ (1,0) [0|1] ""  DMC
 SG_ FCM_10_TJAICATextinfo : 27|3@0+ (1,0) [0|7] ""  DMC
 SG_ FCM_10_LDWSysSts : 18|3@0+ (1,0) [0|7] ""  DMC
 SG_ FCM_10_LDPSysSts : 21|3@0+ (1,0) [0|7] ""  DMC
 SG_ FCM_10_TLITrfcLi : 23|2@0+ (1,0) [0|3] ""  DMC
 SG_ FCM_10_TSISgnLongStayDisp : 11|4@0+ (1,0) [0|15] ""  DMC
 SG_ FCM_10_TLISysSts : 5|2@0+ (1,0) [0|3] ""  DMC
 SG_ FCM_10_TSISysSts : 7|2@0+ (1,0) [0|3] ""  DMC
 SG_ FCM_10_TSISgnForb : 15|4@0+ (1,0) [0|15] ""  DMC
 SG_ FCM_10_TSISgnGiWay : 3|4@0+ (1,0) [0|15] ""  DMC

BO_ 1245 FCM_5: 8 Vector__XXX
 SG_ FCM_5_SLAmodeSWSet : 47|2@0+ (1,0) [0|3] ""  DMC
 SG_ FCM_5_SpeedLmtNmberE : 37|6@0+ (1,0) [0|63] ""  DMC
 SG_ FCM_5_SpeedLmtNmberAb : 27|6@0+ (1,0) [0|63] ""  DMC
 SG_ SLASpdlimitWarningAudSWSts : 31|2@0+ (1,0) [0|3] ""  DMC
 SG_ SLASpdLimChgAudSwSts : 29|2@0+ (1,0) [0|3] ""  DMC
 SG_ SLWFONOFFSts : 17|2@0+ (1,0) [0|3] ""  DMC
 SG_ FCM_5_ELKONOFFSts : 19|2@0+ (1,0) [0|3] ""  DMC
 SG_ FCM_5_LDWLDPSnvtySts : 21|2@0+ (1,0) [0|3] ""  DMC
 SG_ FCM_5_LDPONOFFSts : 23|2@0+ (1,0) [0|3] ""  DMC
 SG_ FCM_5_WarnModSts : 9|2@0+ (1,0) [0|3] ""  DMC
 SG_ FCM_5_LDWONOFFSts : 11|2@0+ (1,0) [0|3] ""  DMC
 SG_ FCM_5_TLIONOFFSts : 13|2@0+ (1,0) [0|3] ""  DMC
 SG_ FCM_5_TSIONOFFSts : 15|2@0+ (1,0) [0|3] ""  DMC
 SG_ FCM_5_HMAONOFFSts : 1|2@0+ (1,0) [0|3] ""  DMC
 SG_ FCM_5_IESONOFFSts : 3|2@0+ (1,0) [0|3] ""  DMC
 SG_ FCM_5_SLAONOFFSts : 5|2@0+ (1,0) [0|3] ""  DMC
 SG_ FCM_5_TJAICAExitTextInfoSts : 7|2@0+ (1,0) [0|3] ""  DMC

BO_ 775 FCM_2: 8 Vector__XXX
 SG_ FCM_2_TJATakeoverReq : 43|2@0+ (1,0) [0|3] ""  DMC
 SG_ SLASpdlimitWarningAud : 55|1@0+ (1,0) [0|1] ""  DMC
 SG_ SLASpdlimitWarningVis : 54|1@0+ (1,0) [0|1] ""  DMC
 SG_ SLASpdlimitUnknownWarning : 53|2@0+ (1,0) [0|3] ""  DMC
 SG_ FCM_2_SLASpdlimitUnits : 41|2@0+ (1,0) [0|3] ""  DMC
 SG_ TJA_ICA_ON_OFF_sts : 44|1@0+ (1,0) [0|1] ""  DMC
 SG_ TJA_ICA_mode : 47|3@0+ (1,0) [0|4] ""  DMC
 SG_ Camera_textinfo : 39|2@0+ (1,0) [0|3] ""  DMC
 SG_ FCM_2_SpdLimtyp : 36|2@0+ (1,0) [0|3] ""  DMC
 SG_ SLASpdlimit : 18|8@0+ (1,0) [0|255] ""  DMC
 SG_ FCM_2_SLAmodeSWSet : 26|2@0+ (1,0) [0|3] ""  DMC
 SG_ SLASpdlimitWarning : 24|1@0+ (1,0) [0|1] ""  DMC
 SG_ FCM_2_SCFSpdlimWarn : 22|1@0+ (1,0) [0|1] ""  DMC
 SG_ SLAState : 21|3@0+ (1,0) [0|7] ""  DMC
 SG_ LDW_ELK_TJA_LDPRightVisuali : 15|2@0+ (1,0) [0|3] ""  DMC
 SG_ FCM_2_ISAState : 13|3@0+ (1,0) [0|7] ""  DMC
 SG_ LDW_ELK_TJA_LDPLeftVisuali : 7|2@0+ (1,0) [0|3] ""  DMC
 SG_ HMA_HighbeamReq : 3|1@0+ (1,0) [0|1] ""  DMC
 SG_ HMA_Status : 2|3@0+ (1,0) [0|7] ""  DMC

BO_ 1270 EPB_G: 2 Vector__XXX
 SG_ Yellowwarning : 11|2@0+ (1,0) [0|3] ""  DMC
 SG_ Redwarning : 13|2@0+ (1,0) [0|3] ""  DMC
 SG_ RWUActive : 14|1@0+ (1,0) [0|1] ""  DMC
 SG_ EPBWarningMessage : 2|3@0+ (1,0) [0|7] ""  DMC
 SG_ EPBStatus : 7|3@0+ (1,0) [0|7] ""  DMC

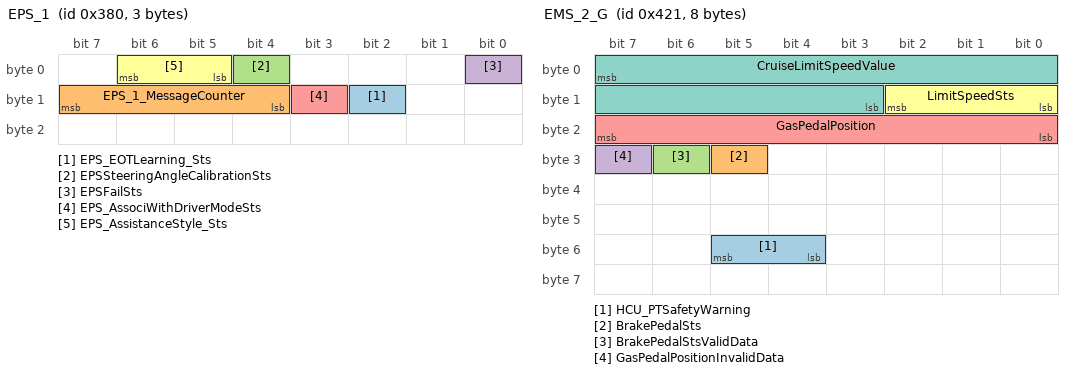
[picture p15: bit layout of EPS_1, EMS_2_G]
BO_ 896 EPS_1: 3 Vector__XXX
 SG_ EPS_EOTLearning_Sts : 10|1@0+ (1,0) [0|1] ""  DMC
 SG_ EPS_1_MessageCounter : 15|4@0+ (1,0) [0|15] ""  DMC
 SG_ EPSSteeringAngleCalibrationSts : 4|1@0+ (1,0) [0|1] ""  DMC
 SG_ EPSFailSts : 0|1@0+ (1,0) [0|1] ""  DMC
 SG_ EPS_AssociWithDriverModeSts : 11|1@0+ (1,0) [0|1] ""  DMC
 SG_ EPS_AssistanceStyle_Sts : 6|2@0+ (1,0) [0|3] ""  DMC

BO_ 1240 EMS_3_G: 8 Vector__XXX
 SG_ EMS_BoostP : 39|16@0+ (0.078125,0) [0|5119] "hPa"  DMC

BO_ 1057 EMS_2_G: 8 Vector__XXX
 SG_ HCU_PTSafetyWarning : 53|2@0+ (1,0) [0|3] ""  DMC
 SG_ BrakePedalSts : 29|1@0+ (1,0) [0|1] ""  DMC
 SG_ BrakePedalStsValidData : 30|1@0+ (1,0) [0|1] ""  DMC
 SG_ GasPedalPositionInvalidData : 31|1@0+ (1,0) [0|1] ""  DMC
 SG_ GasPedalPosition : 23|8@0+ (0.392,0) [0|99.568] "%"  DMC
 SG_ LimitSpeedSts : 10|3@0+ (1,0) [0|7] ""  DMC
 SG_ CruiseLimitSpeedValue : 7|13@0+ (0.0625,0) [0|511.875] "km/h"  DMC

BO_ 640 EMS_1_G: 8 Vector__XXX
 SG_ OilPressureWarningLamp : 60|1@0+ (1,0) [0|1] ""  DMC
 SG_ EMS_EngineSts_Actual : 59|1@0+ (1,0) [0|1] ""  DMC
 SG_ GearReduceIndication : 57|1@0+ (1,0) [0|1] ""  DMC
 SG_ GearRaiseIndication : 56|1@0+ (1,0) [0|1] ""  DMC
 SG_ TargetGearPosition : 49|3@0+ (1,0) [0|7] ""  DMC
 SG_ EPCSts : 53|1@0+ (1,0) [0|1] ""  DMC
 SG_ EngineSpeedValidData : 54|1@0+ (1,0) [0|1] ""  DMC
 SG_ FuelRollingCounterValidData : 55|1@0+ (1,0) [0|1] ""  DMC
 SG_ ISS_Sts_GS : 44|5@0+ (1,0) [0|31] ""  DMC
 SG_ FuelRollingCounter : 31|8@0+ (7.88519E-005,0) [0|0.020028382] "ltr"  DMC
 SG_ EngineCoolantTemperture : 23|8@0+ (0.75,-48) [-48|142.5] "°Ê"  DMC
 SG_ CruiseControlStsForDisplay : 9|2@0+ (1,0) [0|3] ""  DMC
 SG_ ECSControlSts : 10|1@0+ (1,0) [0|1] ""  DMC
 SG_ EngineCoolantTempertureFailSts : 11|1@0+ (1,0) [0|1] ""  DMC
 SG_ MILSts : 13|2@0+ (1,0) [0|3] ""  DMC
 SG_ IEMSts : 1|1@0+ (1,0) [0|1] ""  DMC
 SG_ GPFWarning : 3|2@0+ (1,0) [0|3] ""  DMC
 SG_ EngineSts : 58|1@0+ (1,0) [0|1] ""  DMC
 SG_ SSMStatus : 52|3@0+ (1,0) [0|7] ""  DMC
 SG_ EngineSpeed : 39|11@0+ (4,0) [0|8000] "rpm"  DMC

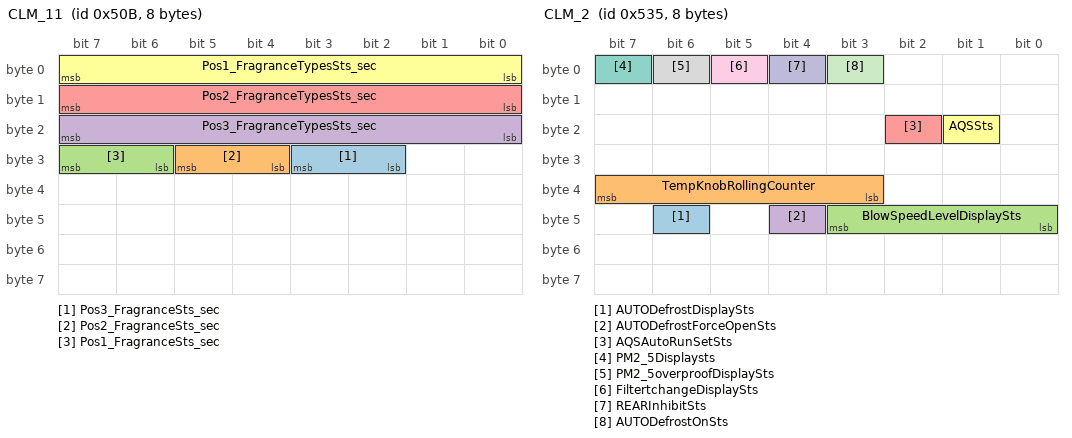
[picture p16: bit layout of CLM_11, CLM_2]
BO_ 1291 CLM_11: 8 Vector__XXX
 SG_ Pos3_FragranceSts_sec : 27|2@0+ (1,0) [0|3] ""  DMC
 SG_ Pos2_FragranceSts_sec : 29|2@0+ (1,0) [0|3] ""  DMC
 SG_ Pos1_FragranceSts_sec : 31|2@0+ (1,0) [0|3] ""  DMC
 SG_ Pos3_FragranceTypesSts_sec : 23|8@0+ (1,0) [0|255] ""  DMC
 SG_ Pos2_FragranceTypesSts_sec : 15|8@0+ (1,0) [0|255] ""  DMC
 SG_ Pos1_FragranceTypesSts_sec : 7|8@0+ (1,0) [0|255] ""  DMC

BO_ 1277 CLM_10: 8 Vector__XXX
 SG_ CLM_10_SteerWhlHeatgSwt : 61|1@0+ (1,0) [0|1] ""  DMC
 SG_ CLM_WindowCmd : 60|5@0+ (1,0) [0|31] ""  DMC
 SG_ AUTODefrostlevelSts : 55|2@0+ (1,0) [0|3] ""  DMC
 SG_ CLM_10_FRSeatVentilationCmd : 53|3@0+ (1,0) [0|7] ""  DMC
 SG_ CLM_10_FLSeatVentilationCmd : 50|3@0+ (1,0) [0|7] ""  DMC
 SG_ CLM_10_FRSeatHeatLevelCmd : 45|3@0+ (1,0) [0|7] ""  DMC
 SG_ CLM_10_FLSeatHeatLevelCmd : 42|3@0+ (1,0) [0|7] ""  DMC
 SG_ CLM_10_CLMIntlgDeodnSts : 63|1@0+ (1,0) [0|1] ""  DMC
 SG_ CLM_10_CLMSupHeatgSts : 62|1@0+ (1,0) [0|1] ""  DMC
 SG_ CLM_10_CLMSupCoolgSts : 7|1@0+ (1,0) [0|1] ""  DMC
 SG_ CLM_10_SeRowDispSts : 47|1@0+ (1,0) [0|1] ""  DMC
 SG_ CLM_10_RfgtLkDispSts : 46|1@0+ (1,0) [0|1] ""  DMC
 SG_ CLM_10_ReRowDispSts : 32|1@0+ (1,0) [0|1] ""  DMC
 SG_ CLM_10_ReRowBlowSpdLvlSts : 35|3@0+ (1,0) [0|7] ""  DMC
 SG_ CLM_10_ReRowWorkSts : 36|1@0+ (1,0) [0|1] ""  DMC
 SG_ CLM_10_RmnDispSts : 31|3@0+ (1,0) [0|7] ""  DMC
 SG_ IncarTemperature_C : 22|7@0+ (1,-40) [-40|85] "°„C"  DMC
 SG_ CLM_10_AQSDispSts : 23|1@0+ (1,0) [0|1] ""  DMC
 SG_ SelfTestResult2 : 15|8@0+ (1,0) [0|255] ""  DMC
 SG_ IntelligentCustomSts : 6|1@0+ (1,0) [0|1] ""  DMC
 SG_ CLM_10_SeRowWorkSts : 5|1@0+ (1,0) [0|1] ""  DMC
 SG_ CLM_10_SeRowBlowSpdLvlDispSts : 4|3@0+ (1,0) [0|7] ""  DMC
 SG_ PtcHeatgSts : 1|1@0+ (1,0) [0|1] ""  DMC

BO_ 1171 CLM_6: 8 Vector__XXX
 SG_ CLM_6_CbnAntiOverHeatSts : 48|2@0+ (1,0) [0|3] ""  DMC
 SG_ CLM_6_warn_sts : 51|1@0+ (1,0) [0|1] ""  DMC
 SG_ AQSAutoRunSts : 52|1@0+ (1,0) [0|1] ""  DMC

BO_ 1334 CLM_3: 8 Vector__XXX
 SG_ CLM_3_Exhaust_Sts : 32|1@0+ (1,0) [0|1] ""  DMC
 SG_ FragranCeconsistenceLevelSts : 58|3@0+ (1,0) [0|7] ""  DMC
 SG_ Pos3_FragranceTypesSts : 49|3@0+ (1,0) [0|7] ""  DMC
 SG_ Pos2_FragranceTypesSts : 62|3@0+ (1,0) [0|7] ""  DMC
 SG_ PM2_5AutoRunSetSts : 59|1@0+ (1,0) [0|1] ""  DMC
 SG_ PM2_5_Incar_Level : 52|3@0+ (1,0) [0|7] ""  DMC
 SG_ PM2_5_Outcar_Level : 55|3@0+ (1,0) [0|7] ""  DMC
 SG_ FragranceDisplaysts : 40|1@0+ (1,0) [0|1] ""  DMC
 SG_ FragrancePositionSwt : 24|2@0+ (1,0) [0|3] ""  DMC
 SG_ ACModeCustomSts : 42|2@0+ (1,0) [0|3] ""  DMC
 SG_ FragranceWelcomeModeSts : 44|1@0+ (1,0) [0|1] ""  DMC
 SG_ RefreshFunctionSts : 43|1@0+ (1,0) [0|1] ""  DMC
 SG_ Pos1_FragranceTypesSts : 47|3@0+ (1,0) [0|7] ""  DMC
 SG_ PM2_5AutoRunSts : 33|1@0+ (1,0) [0|1] ""  DMC
 SG_ FragranceSWSts : 36|2@0+ (1,0) [0|3] ""  DMC
 SG_ AutoBltCalllowBlowSpeedSts : 37|1@0+ (1,0) [0|1] ""  DMC
 SG_ AutoParkInnerCirculationSts : 38|1@0+ (1,0) [0|1] ""  DMC
 SG_ PM2_5_IncarSts : 26|1@0+ (1,0) [0|1] ""  DMC
 SG_ PM2_5_ExtSts : 27|1@0+ (1,0) [0|1] ""  DMC
 SG_ PM2_5_ext : 23|10@0+ (1,0) [0|1000] "ug/m3"  DMC
 SG_ FragranceShortageWarning : 6|3@0+ (1,0) [0|7] ""  DMC
 SG_ ION_Function_Sts : 3|2@0+ (1,0) [0|3] ""  DMC
 SG_ PM2_5_incar : 1|10@0+ (1,0) [0|1000] "ug/m3"  DMC

BO_ 1333 CLM_2: 8 Vector__XXX
 SG_ AUTODefrostDisplaySts : 46|1@0+ (1,0) [0|1] ""  DMC
 SG_ TempKnobRollingCounter : 39|5@0+ (1,0) [0|31] ""  DMC
 SG_ BlowSpeedLevelDisplaySts : 43|4@0+ (1,0) [0|15] ""  DMC
 SG_ AUTODefrostForceOpenSts : 44|1@0+ (1,0) [0|1] ""  DMC
 SG_ AQSAutoRunSetSts : 18|1@0+ (1,0) [0|1] ""  DMC
 SG_ AQSSts : 17|1@0+ (1,0) [0|1] ""  DMC
 SG_ PM2_5Displaysts : 7|1@0+ (1,0) [0|1] ""  DMC
 SG_ PM2_5overproofDisplaySts : 6|1@0+ (1,0) [0|1] ""  DMC
 SG_ FiltertchangeDisplaySts : 5|1@0+ (1,0) [0|1] ""  DMC
 SG_ REARInhibitSts : 4|1@0+ (1,0) [0|1] ""  DMC
 SG_ AUTODefrostOnSts : 3|1@0+ (1,0) [0|1] ""  DMC

BO_ 1104 CGW_1: 8 Vector__XXX
 SG_ OBDDiagnosisReqInd : 7|1@0+ (1,0) [0|1] ""  DMC

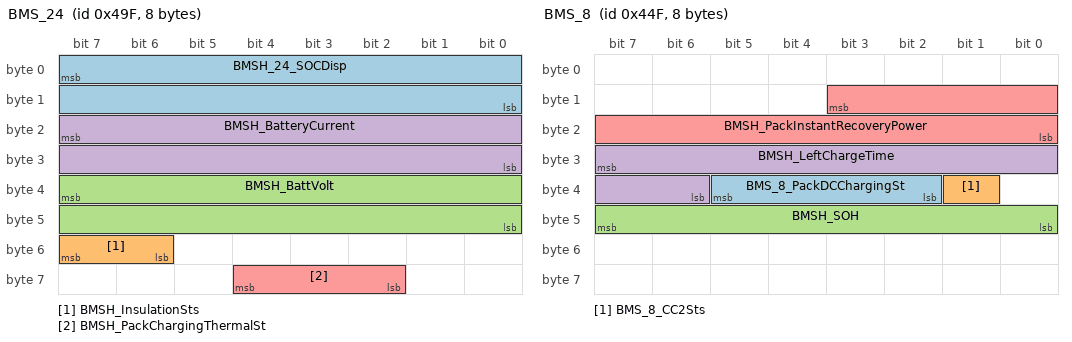
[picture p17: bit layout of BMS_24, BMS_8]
BO_ 1183 BMS_24: 8 Vector__XXX
 SG_ BMSH_24_SOCDisp : 7|16@0+ (0.01,0) [0|100] "%"  DMC
 SG_ BMSH_InsulationSts : 55|2@0+ (1,0) [0|3] ""  DMC
 SG_ BMSH_BattVolt : 39|16@0+ (0.05,0) [0|1000] "V"  DMC
 SG_ BMSH_BatteryCurrent : 23|16@0+ (0.05,-1600) [-600|600] "A"  DMC
 SG_ BMSH_PackChargingThermalSt : 60|3@0+ (1,0) [0|7] ""  DMC

BO_ 1103 BMS_8: 8 Vector__XXX
 SG_ BMS_8_PackDCChargingSt : 37|4@0+ (1,0) [0|15] ""  DMC
 SG_ BMS_8_CC2Sts : 33|1@0+ (1,0) [0|1] ""  DMC
 SG_ BMSH_SOH : 47|8@0+ (1,0) [0|100] "%"  DMC
 SG_ BMSH_LeftChargeTime : 31|10@0+ (1,0) [0|1022] "Minute"  DMC
 SG_ BMSH_PackInstantRecoveryPower : 11|12@0+ (0.1,0) [0|320] "KW"  DMC

BO_ 1083 BMS_5: 8 Vector__XXX
 SG_ BMSH_BattFaultLampSts : 27|1@0+ (1,0) [0|1] ""  DMC
 SG_ BMSH_PackThermalRunawayLight : 26|1@0+ (1,0) [0|1] ""  DMC
 SG_ BMSH_SOCDisp : 7|16@0+ (0.01,0) [0|100] "%"  DMC

BO_ 1379 BMS_37: 8 Vector__XXX
 SG_ BMSH_KeepWarmTimeSum : 55|16@0+ (1,0) [0|65535] "S"  DMC
 SG_ BMSH_KeepWarmSelfWakeupTimes : 47|8@0+ (1,0) [0|255] "Time"  DMC
 SG_ BMSH_keepWarmNextTimeRSet : 31|12@0+ (1,0) [0|4095] "S"  DMC

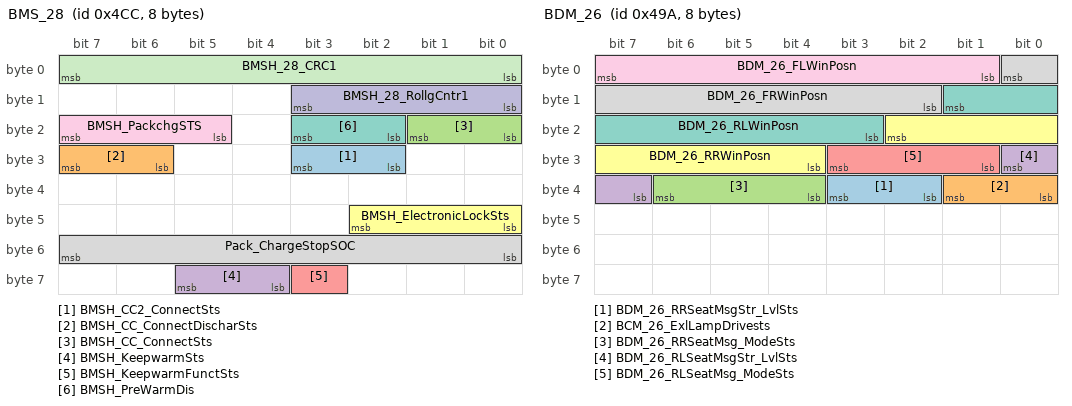
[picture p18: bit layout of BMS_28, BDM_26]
BO_ 1228 BMS_28: 8 Vector__XXX
 SG_ BMSH_CC2_ConnectSts : 27|2@0+ (1,0) [0|1] ""  DMC
 SG_ BMSH_CC_ConnectDischarSts : 31|2@0+ (1,0) [0|3] ""  DMC
 SG_ BMSH_CC_ConnectSts : 17|2@0+ (1,0) [0|3] ""  DMC
 SG_ BMSH_KeepwarmSts : 61|2@0+ (1,0) [0|3] ""  DMC
 SG_ BMSH_KeepwarmFunctSts : 59|1@0+ (1,0) [0|1] ""  DMC
 SG_ BMSH_ElectronicLockSts : 42|3@0+ (1,0) [0|7] ""  DMC
 SG_ BMSH_PreWarmDis : 19|2@0+ (1,0) [0|2] ""  DMC
 SG_ Pack_ChargeStopSOC : 55|8@0+ (1,0) [0|100] "%"  DMC
 SG_ BMSH_PackchgSTS : 23|3@0+ (1,0) [0|7] ""  DMC
 SG_ BMSH_28_RollgCntr1 : 11|4@0+ (1,0) [0|15] ""  DMC
 SG_ BMSH_28_CRC1 : 7|8@0+ (1,0) [0|255] ""  DMC

BO_ 1178 BDM_26: 8 Vector__XXX
 SG_ BDM_26_RRSeatMsgStr_LvlSts : 35|2@0+ (1,0) [0|3] ""  DMC
 SG_ BCM_26_ExlLampDrivests : 33|2@0+ (1,0) [0|1] ""  DMC
 SG_ BDM_26_RRSeatMsg_ModeSts : 38|3@0+ (1,0) [0|7] ""  DMC
 SG_ BDM_26_RLSeatMsgStr_LvlSts : 24|2@0+ (1,0) [0|3] ""  DMC
 SG_ BDM_26_RLSeatMsg_ModeSts : 27|3@0+ (1,0) [0|7] ""  DMC
 SG_ BDM_26_RRWinPosn : 18|7@0+ (1,0) [0|100] "%"  DMC
 SG_ BDM_26_RLWinPosn : 9|7@0+ (1,0) [0|100] "%"  DMC
 SG_ BDM_26_FRWinPosn : 0|7@0+ (1,0) [0|100] "%"  DMC
 SG_ BDM_26_FLWinPosn : 7|7@0+ (1,0) [0|100] "%"  DMC

BO_ 1007 BDM_25: 8 Vector__XXX
 SG_ BDM_25_AmbBrightness : 23|12@0+ (20,0) [0|81880] "Lux"  DMC
 SG_ BDM_25_FWBrightness : 1|10@0+ (6,0) [0|6126] "Lux"  DMC

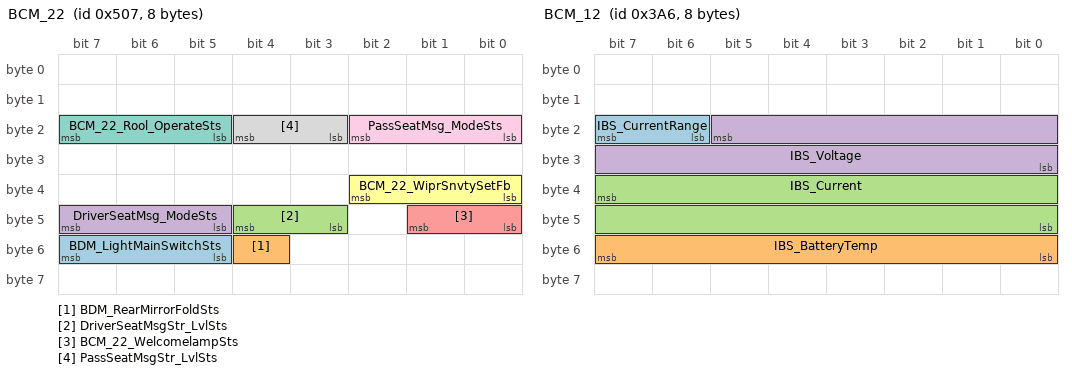
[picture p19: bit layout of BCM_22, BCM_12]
BO_ 1287 BCM_22: 8 Vector__XXX
 SG_ BDM_LightMainSwitchSts : 55|3@0+ (1,0) [0|7] ""  DMC
 SG_ BDM_RearMirrorFoldSts : 52|1@0+ (1,0) [0|1] ""  DMC
 SG_ DriverSeatMsgStr_LvlSts : 44|2@0+ (1,0) [0|3] ""  DMC
 SG_ DriverSeatMsg_ModeSts : 47|3@0+ (1,0) [0|7] ""  DMC
 SG_ BCM_22_WelcomelampSts : 41|2@0+ (1,0) [0|3] ""  DMC
 SG_ BCM_22_WiprSnvtySetFb : 34|3@0+ (1,0) [0|7] ""  DMC
 SG_ BCM_22_Rool_OperateSts : 23|3@0+ (1,0) [0|7] ""  DMC
 SG_ PassSeatMsgStr_LvlSts : 20|2@0+ (1,0) [0|3] ""  DMC
 SG_ PassSeatMsg_ModeSts : 18|3@0+ (1,0) [0|7] ""  DMC

BO_ 939 BCM_14: 8 Vector__XXX
 SG_ IBS_QuiescentCurrent : 31|8@0+ (0.00390625,0) [0|0.99609375] "A"  DMC

BO_ 936 BCM_13: 8 Vector__XXX
 SG_ IBS_SOF_V1 : 39|8@0+ (0.0625,0) [0|15.9375] "V"  DMC
 SG_ IBS_STAT_SOC : 9|2@0+ (1,0) [0|3] ""  DMC
 SG_ IBS_SOH : 55|8@0+ (1,0) [0|255] "%"  DMC
 SG_ IBS_SOC : 23|8@0+ (1,0) [0|255] "%"  DMC

BO_ 934 BCM_12: 8 Vector__XXX
 SG_ IBS_CurrentRange : 23|2@0+ (1,0) [0|3] ""  DMC
 SG_ IBS_BatteryTemp : 55|8@0+ (1,-40) [-40|215] "degC"  DMC
 SG_ IBS_Current : 39|16@0+ (1,0) [0|0] "A"  DMC
 SG_ IBS_Voltage : 21|14@0+ (0.000976563,3) [3|18] "V"  DMC

CM_ BO_ 3221225472 "This is a message for not used signals, created by Vector CANdb++ DBC OLE DB Provider.";
CM_ SG_ 3221225472 AdasSignType_reserve "????????_???";
CM_ SG_ 1259 VCU_PwrPersent "???????????";
CM_ SG_ 1259 VCU_CampMod "??????????";
CM_ SG_ 1259 VCU_5_EtmEgySaveMod "VCU??????????????";
CM_ SG_ 1259 VCU_5_EEMReq "?????????????";
CM_ SG_ 1259 VCU_HundECAver "average consumption per hundred KM";
CM_ SG_ 1259 VCU_InstantEnergyConsump "Instant Energy Consump";
CM_ SG_ 1259 VCU_RangeAval_2 "Remain available range";
CM_ SG_ 1259 VCU_RangeAval_1 "Remain available range";
CM_ SG_ 1259 VCU_Pwr "instant power";
CM_ SG_ 1257 VCU_LimitSpeed "?????????";
CM_ SG_ 1257 VCU_LimitSpeedSts "??????????£¨?????ACC???????";
CM_ SG_ 1257 VCU_4_Resd1 "Reserved";
CM_ SG_ 1257 VCU_4_RollgCntr1 "Rolling message counter(the maximum value of Alive counter is 15) Note: Details Please refer to specification??EE Standard Specification for CAN FD Network Implementation??section 2.3.1";
CM_ SG_ 1257 VCU_4_CRC1 "CRC (SAE J1850 CRC-8) Note: Details Please refer to specification??EE Standard Specification for CAN FD Network Implementation??section 2.3.2";
CM_ SG_ 1250 BMS_LeftDCChargeTime "?????????
????PHEV?????????????   BMS_34????!dou!???°§??????????";
CM_ SG_ 1250 EVCC_ElectronicLockSts "???????????£¨EVCC_2?????IF????IHU????£¨???°§?????????PHEV????";
CM_ BO_ 928 "Source network message is \"Cyclic, 20ms\".
If no messages are received on source network, no messages are sent on the destination network.";
CM_ SG_ 928 YAS_2_Checksum "0x01 XOR 0x28 XOR Byte0 XOR Byte1 XOR Byte2 XOR Byte3 XOR Byte4 XOR Byte5 XOR Byte6";
CM_ SG_ 928 LongitudinalAcceleration "???????????
??????????!mao!0.0027680342857143 g";
CM_ SG_ 928 LongitudinalAccelerationSigValid "If hasn??t been calibrated, after initialization, this signal ??s value is always10(invalid)";
CM_ BO_ 926 "Source network message is \"Cyclic, 20ms\".
If no messages are received on source network, no messages are sent on the destination network.";
CM_ SG_ 926 YAS_1_Checksum "0x01 XOR 0x27 XOR Byte0 XOR Byte1 XOR Byte2 XOR Byte3 XOR Byte4 XOR Byte5 XOR Byte6";
CM_ SG_ 926 YawRate "???????????                ??????????£∫0.122189236 deg/s";
CM_ SG_ 926 YawrateSigValidData "Signal state for yawrate";
CM_ BO_ 1261 "Source network message is \"Cyclic, 100ms\".
If no messages are received on source network, no messages are sent on the destination network.";
CM_ SG_ 1261 VCU_TowMode "???????";
CM_ SG_ 1261 V2L_FunctionSts "indication Discharging state";
CM_ SG_ 1261 V2L_DischargeStopSOC "Discharge Stop SOC";
CM_ SG_ 1261 VCU_EgyRegenLevel "power regeneration level";
CM_ SG_ 1261 VCU_PowerLimit "power limitation indication";
CM_ SG_ 1261 VCU_LowSOCCLMLimitSts "power limitation CLM";
CM_ SG_ 1261 VCU_VehicleSystemFailure "vehicle system failure";
CM_ SG_ 1261 VCU_PTReady "PT Ready indication";
CM_ SG_ 1261 VCU_HVReady "HV Ready";
CM_ SG_ 1261 VCU_PRNDGearAct "Gear indication";
CM_ BO_ 769 "Source network message is \"Cyclic, 100ms\".
If no messages are received on source network, no messages are sent on the destination network.";
CM_ SG_ 769 TCU_G_CluSelfLrng "ClutchSelfLearning
???????????
0x0 ???????!dou!0x1 ?????????????????";
CM_ SG_ 769 STAT_LeverModeDisp "Shows the physical position of the gearbox - the drive mode that is active in the MAM (TCU). This value is different from the physical lever position, if the gearbox has failures or engine is off. 
????EGS?????¶À???";
CM_ SG_ 769 TCU_SpeParkSts "?????????????????";
CM_ SG_ 769 GBPositoionDisplay "?????M1??£¨????5£¨???????????£¨??01101??????????????????
Low???CVT?ß≥?for PHEV!mao!TCU only has 0x0!dun!0x1!dun!0x2!dun!0x3!dun!0x4";
CM_ SG_ 769 GBFaultstatus "Activation gearbox error Lamp, only for ICM including LCD to light LED and LCD. This signal should be sent with ??AGErrorLamp?? simultaneously
For 6DCT,only has 00/01.
For CVT/AMT/AT, only has 00/01/10.";
CM_ BO_ 1206 "Source network message is \"Cyclic, 100ms\".
If no messages are received on source network, no messages are sent on the destination network.";
CM_ SG_ 1206 SHU2R_RSeatVentnSts "Seat Ventilation Status
????????????????";
CM_ SG_ 1206 SHU2R_RSeatHeatSts "Seat Heat Status
??????????¶Ã?????";
CM_ BO_ 1202 "Source network message is \"Cyclic, 100ms\".
If no messages are received on source network, no messages are sent on the destination network.";
CM_ SG_ 1202 SHU2M_MSeatVentnSts "Seat Ventilation Status
?????ßﬁ??????????";
CM_ SG_ 1202 SHU2M_MSeatHeatSts "Seat Heat Status
?????ßﬁ????¶Ã?????";
CM_ BO_ 1194 "Source network message is \"Cyclic, 100ms\".
If no messages are received on source network, no messages are sent on the destination network.";
CM_ SG_ 1194 SHU2L_LSeatVentnSts "Seat Ventilation Status
????????????????";
CM_ SG_ 1194 SHU2L_LSeatHeatSts "Seat Heat Status
??????????¶Ã?????";
CM_ BO_ 1190 "Source network message is \"Cyclic, 100ms\".
If no messages are received on source network, no messages are sent on the destination network.";
CM_ SG_ 1190 SHU1R_RSeatAutVentnSts "Passenger Seat Automatic Ventilation Status";
CM_ SG_ 1190 SHU1R_RSeatAutHeatSts "Passenger Seat Automatic Heat Status";
CM_ SG_ 1190 SHU1R_RSeatVentnSts "Passenger Seat Ventilation Status
???????????????";
CM_ SG_ 1190 SHU1R_RSeatHeatSts "Passenger Seat Heat Status
?????????¶Ã?????";
CM_ BO_ 1186 "Source network message is \"Cyclic, 100ms\".
If no messages are received on source network, no messages are sent on the destination network.";
CM_ SG_ 1186 SHU1L_LSeatAutVentnSts "Driver Seat Automatic Ventilation Status";
CM_ SG_ 1186 SHU1L_LSeatAutHeatSts "Driver Seat Automatic Heat Status";
CM_ SG_ 1186 SHU1L_LSeatVentnSts "Driver Seat Ventilation Status
????????????????";
CM_ SG_ 1186 SHU1L_LSeatHeatSts "Driver Seat Heat Status
??????????¶Ã?????";
CM_ SG_ 1129 SCUP_2_PsngrSeatMemSts "SCUP????¶À?®π?????";
CM_ SG_ 1129 SCUP_2_PsngrSeatMemReq "SCUP????????";
CM_ SG_ 1058 SCUP_1_PsngrSeatFlatSts "SCUP?????????";
CM_ SG_ 1058 SCUP_1_PsngrSeatFlatWarn "SCUP??????-??????/????/?????";
CM_ SG_ 1058 SCUP_1_PsngrSeatBackAgPosnTar "???????¶«???????????¶À??";
CM_ SG_ 1058 SCUP_1_PsngrSeatLegSprtCurr "????????????????";
CM_ SG_ 1058 SCUP_1_PsngrSeatLegSprtPosnTar "???????¶«????????????¶À??";
CM_ SG_ 1058 SCUP_1_PsngrSeatLvlPosnStsTar "???????¶«???????????¶À??";
CM_ SG_ 1058 SCUP_1_PsngrSeatHeiPosnStsTar "???????¶«????????¶À??";
CM_ SG_ 1170 SCU_2_CRC "CRC (SAE J1850 CRC-8)
Note: Details Please refer to specification??Standard Specification for CAN Data Link Layer_v1.1??section 2.3.2";
CM_ SG_ 1170 SCU_2_MessageCounter "Rolling message counter(the maximum value of Alive counter is 15)
Note: Details Please refer to specification??Standard Specification for CAN Data Link Layer_v1.1??section 2.3.1";
CM_ SG_ 1170 SCU_2_SeatLegSpprtPosnStsTar "Seat leg support position status";
CM_ SG_ 1170 SCU_2_SeatLvlPosnStsTar "Seat level position status";
CM_ SG_ 1170 SCU_2_SeatHdrestHeiAdjmt "Seat headrest height adjustment";
CM_ SG_ 1170 SCU_2_BackrAgPosnStsTar "Seat back angle position status";
CM_ SG_ 1170 SCU_2_SeatCushPosnSts "Seat cushion position status";
CM_ SG_ 1170 SCU_2_SeatHeiPosnStsTar "Seat height position status";
CM_ BO_ 924 "Source network message is \"Cyclic, 10ms\".
If no messages are received on source network, no messages are sent on the destination network.";
CM_ SG_ 924 SAM_1_GCRCCheck "CRC (SAE J1850 CRC-8)
Note: Details Please refer to specification??Standard Specification for CAN Data Link Layer_v1.1??section 2.3.2";
CM_ SG_ 924 SAM_1_G_MessageCounter "Rolling message counter(the maximum value of Alive counter is 15)
Note: Details Please refer to specification??Standard Specification for CAN Data Link Layer_v1.1??section 2.3.1";
CM_ SG_ 924 AngleFailure "????????????????SAS????????????
SAS¶ƒ????ß“?????????????¶∂???1-failure";
CM_ SG_ 924 SteeringAngle "The actual range is from -720 deg to +720 deg.";
CM_ BO_ 1203 "Source network message is \"Cyclic, 100ms\".
If no messages are received on source network, no messages are sent on the destination network.";
CM_ SG_ 1203 RRCR_1_CRC "CRC (SAE J1850 CRC-8)
Note: Details Please refer to specification??EE Standard Specification for CAN FD Network Implementation??section 2.3.2";
CM_ SG_ 1203 RRCR_1_MsgCntr "Rolling message counter(the maximum value of Alive counter is 15)
Note: Details Please refer to specification??EE Standard Specification for CAN FD Network Implementation??section 2.3.1";
CM_ SG_ 1203 RCTA_WarningRH "RCTA System Right Side Warning Status signal(Chime and Visual)";
CM_ SG_ 1203 TimeOut_BSDR "this signal is only used for time-out detection by IPC";
CM_ SG_ 1203 RRCR_1_ObjTyp "Objective type
-00 (Ukwn)!mao! invalid??Unused objects, such as people??";
CM_ SG_ 1203 RRCR_1_BlkSts "Blockage Status(only for VEONEER)";
CM_ SG_ 1203 RRCR_1_DOWWarn "Door open warning";
CM_ SG_ 1203 RRCR_1_RCTAWarn "RCTA Warning";
CM_ SG_ 1203 RRCR_1_BSDWarn "Blind spot detection system Warning";
CM_ SG_ 1203 RRCR_1_SysSt "System State (only for VEONEER)";
CM_ BO_ 1075 "Source network message is \"Cyclic, 10ms\".
If no messages are received on source network, no messages are sent on the destination network.";
CM_ SG_ 1075 RLCR_2_RCTBONOFFSts "RCTB Switch status
For ????PHEV!dun!EV";
CM_ SG_ 1075 RLCR_2_RAEBONOFFSts "RAEB Switch status
For ????PHEV!dun!EV";
CM_ BO_ 1201 "Source network message is \"Cyclic, 100ms\".
If no messages are received on source network, no messages are sent on the destination network.";
CM_ SG_ 1201 RLCR_1_CRC "CRC (SAE J1850 CRC-8)
Note: Details Please refer to specification??EE Standard Specification for CAN FD Network Implementation??section 2.3.2";
CM_ SG_ 1201 RLCR_1_MsgCntr "Rolling message counter(the maximum value of Alive counter is 15)
Note: Details Please refer to specification??EE Standard Specification for CAN FD Network Implementation??section 2.3.1";
CM_ SG_ 1201 STAT_RCTBEnable "RCTB turn on off status from BSD";
CM_ SG_ 1201 DOW_Status "DOW status signal(include DOW status)";
CM_ SG_ 1201 RCW_Status "RCW status signal(include RCW status)";
CM_ SG_ 1201 STAT_DOWWarningMode "DOW warning mode feedback status";
CM_ SG_ 1201 STAT_CVWWarningMode "CVW warning mode feedback status";
CM_ SG_ 1201 RCTA_WarningLH "RCTA System Left Side Warning Status signal(Chime and Visual)";
CM_ SG_ 1201 CVW_Warning "CVW warning request signal when move forward";
CM_ SG_ 1201 CVW_Status "CVW status signal(include CVW status)";
CM_ SG_ 1201 BSD_Status "BSD radars status signal(include BSD/LCA and RCTA status)";
CM_ SG_ 1201 RCTA_Status "RCTA function status signal";
CM_ SG_ 1201 STAT_RCWWarningMode "RCW warning mode feedback status";
CM_ SG_ 1201 STAT_BSDWarningMode "BSDL warning mode feedback status";
CM_ SG_ 1201 RLCR_1_ObjTyp "Objective type
-00 (Ukwn)!mao! invalid??Unused objects, such as people??";
CM_ SG_ 1201 RLCR_1_RCWWarn "Rear Collision Warning Warning";
CM_ SG_ 1201 RLCR_1_DOWWarn "Door open warning Warning";
CM_ SG_ 1201 RLCR_1_RCWONOFFSts "Rear Collision Warning Switch Status";
CM_ SG_ 1201 RLCR_1_DOWONOFFSts "Door open warning Switch status";
CM_ SG_ 1201 RLCR_1_BSDLCARCTAONOFFSts "Blind spot detection system/LCA/RCTA Switch status";
CM_ SG_ 1201 RLCR_1_RCTAWarn "RCTA Warning";
CM_ SG_ 1201 RLCR_1_BlkSts "Blockage Status(only for VEONEER)";
CM_ SG_ 1201 RLCR_1_RAEBWarn "RAEB Warning";
CM_ SG_ 1201 RLCR_1_RCTBWarn "RCTA Warning";
CM_ SG_ 1201 RLCR_1_BSDWarn "Blind spot detection system Warning";
CM_ SG_ 1201 RLCR_1_SysSt "System self-test State(only for VEONEER)";
CM_ SG_ 1208 PPMICounter "????¶ƒ??
????????";
CM_ SG_ 1208 PPMI_1_BSRBPASts "Belt slack reduction(BSR) / ??????????
Belt parking assist(BPA) / ???????????";
CM_ SG_ 1208 PPMI_1_HWSts "Haptic Warning(HWA) /  ??????????";
CM_ SG_ 1339 PDCDistanceFRM "Object distance by front middle right PDC sensor. Typically maximum 120cm. 0xFF:no obstacle detected/invalid";
CM_ SG_ 1339 PDCDistanceFR "Object distance by front right PDC sensor. Typically maximum 60cm. 0xFF:no obstacle detected/invalid";
CM_ SG_ 1339 PDCDistanceFLM "Object distance by front middle left PDC sensor. Typically maximum 120cm. 0xFF:no obstacle detected/invalid";
CM_ SG_ 1339 PDCDistanceFL "Object distance by front left PDC sensor. Typically maximum 60cm. 0xFF:no obstacle detected/invalid";
CM_ SG_ 1339 PDCDistanceRRM "Object distance by rear middle right PDC sensor. Typically maximum 150cm. 0xFF:no obstacle detected/invalid";
CM_ SG_ 1339 PDCDistanceRR "Object distance by rear right PDC sensor. Typically maximum 60cm. 0xFF:no obstacle detected/invalid";
CM_ SG_ 1339 PDCDistanceRLM "Object distance by rear middle left PDC sensor. Typically maximum 150cm. 0xFF:no obstacle detected/invalid";
CM_ SG_ 1339 PDCDistanceRL "Object distance by rear left PDC sensor. Typically maximum 60cm. 0xFF:no obstacle detected/invalid";
CM_ BO_ 1042 "Source network message is \"Cyclic, 100ms\".
If no messages are received on source network, no messages are sent on the destination network.";
CM_ SG_ 1042 PEPS_BLTKey_PESts "????????PE??????????????";
CM_ BO_ 998 "Source network message is \"Cyclic, 50ms\".
If no messages are received on source network, no messages are sent on the destination network.";
CM_ SG_ 998 RemoteStartSts "????????";
CM_ SG_ 998 Start_StopRequest "???,???????";
CM_ SG_ 998 IDInformation "To show which ID is sending the signal.";
CM_ SG_ 1125 OBC_ChgSts_PHEV "OBC charge stated";
CM_ SG_ 1125 OBC_ChgSts "OBC_ChgSts_EV(only for EV)
OBC charge stated";
CM_ SG_ 1125 OBC_ActDisOutPower "Discharge Actual max Power";
CM_ SG_ 1125 OBC_ElectronicLockSts "Electronic Lock Sts                                                                ???????????????PHEV                                            Added soft switch of charging gun for PHEV";
CM_ SG_ 1125 OBC_3_Dchasts "OBC??¿H???? ???PHEV                                                                      Discharge function status for PHEV";
CM_ SG_ 1125 OBC_CC_ConnectSts "CC connect states";
CM_ BO_ 1124 "Source network message is \"Cyclic, 100ms\".
If no messages are received on source network, no messages are sent on the destination network.";
CM_ SG_ 1124 NFC_1_DispCardPosn "Display card position";
CM_ SG_ 850 HCU_13_CurrentTripEnergyCns "Sum Energy Consumption
????????????????? L/100km";
CM_ SG_ 850 HCU_13_CurrentTripElecCns "SumElectricConsumption
???????????????? kW.h/100km";
CM_ SG_ 850 HCU_13_CurrentTripFuCns "SumFuelConsumption
????????????????? L/100km";
CM_ SG_ 850 HCU_13_EngSelfMaiTin "EngineSelfMaintain??????????????????";
CM_ SG_ 1195 HCU_6_G_PwrdwnDisReq "????IHU???¶Ã??????????";
CM_ SG_ 1195 HCU_6_G_VehStrtWarn "VehicleStartWarning??????????";
CM_ SG_ 1195 HCU_6_G_ElecPwrVal "Electric power value
?????????????";
CM_ SG_ 1195 HCU_6_G_DynRngAval "DynamicRangeAval
????????????";
CM_ SG_ 1195 HCU_6_G_SumFuel "SumFuel
?????????";
CM_ SG_ 1195 HCU_6_G_SumPlgChrgEgy "SumPluginChargedEnergy
????????";
CM_ SG_ 1159 HCU_SetSOCFedstep1 "??????????";
CM_ SG_ 1159 HCU_PrecRRTorque "???????????";
CM_ SG_ 1159 HCU_PrecRFTorque "???????????";
CM_ SG_ 1159 HCU_PrecLRTorque "???????????";
CM_ SG_ 1159 HCU_PrecLFTorque "???????????";
CM_ BO_ 1142 "Source network message is \"Cyclic, 100ms\".
If no messages are received on source network, no messages are sent on the destination network.";
CM_ SG_ 1142 HCU_4_G_EngRunFuCns "Eng Run Fuel Consumption
??100km???????????? L/100km";
CM_ SG_ 1142 HCU_4_G_SumEgyCns "Sum Energy Consumption
????????????????? L/100km";
CM_ SG_ 1142 HCU_4_G_AvgEnergyCns "Avg Energy Consumption
??50km??????????? L/100km";
CM_ SG_ 1142 HCU_4_G_AvgElecCns "Avg Electric Consumption
??50km?????????? kW.h/100km";
CM_ SG_ 1142 HCU_4_G_AvgFuCns "Avg Fuel Consumption
??50km??????????? L/100km";
CM_ SG_ 1142 HCU_BrkPsd "brake Pressed(??????????????????????)";
CM_ SG_ 1142 HCU_4_G_ForcedPrkgChrg "Forced Parking Charge";
CM_ SG_ 1142 HCU_4_G_EDrvOnly "EDriveOnly";
CM_ SG_ 1142 FuelTankLidSts "????ß≥???????";
CM_ BO_ 1046 "Source network message is \"Cyclic, 100ms\".
If no messages are received on source network, no messages are sent on the destination network.";
CM_ SG_ 1046 HCU_EgyReGenIndcrB "Energy Regenerate indicator B";
CM_ SG_ 1046 HCU_HvSysFltStopReq "High voltage system fault stop request";
CM_ SG_ 1046 HCU_PowerLimit "Power Limit";
CM_ SG_ 1046 HCU_HundECHis "Hundred  kilometres Electric Consume Average history";
CM_ SG_ 1046 HCU_HundECAver "Hundred  kilometres Electric Consume Average";
CM_ SG_ 1046 HCU_3_G_SumElecCns "SumElectricConsumption
???????????????? kW.h/100km";
CM_ SG_ 1046 HCU_OTAHvReqSts "OTA high voltage request status feedback";
CM_ SG_ 1046 HCU_OTAModSts "OTA mode status";
CM_ SG_ 1046 HCU_ShowRoomRunngreason "?????£∫??????£¨HCU????IHU??";
CM_ SG_ 1046 HCU_3_G_SumFuCns "SumFuelConsumption
????????????????? L/100km";
CM_ SG_ 1046 HCU_ShowRoomRunngSts "?????£∫??????ßﬂ??HCU?????:BCM/IHU??";
CM_ SG_ 1044 HCU_2_G_DchaFail "0x0:???????????
0x1:?????????????";
CM_ SG_ 1044 HCU_2_G_LowBatteryLowFuelInfo "0x0: No Request         ???????
0x1: Request            ???????????????????????!dou!????????????≥ê";
CM_ SG_ 1044 HCU_2_G_LowBatteryInfo "0x0: No Request         ???????
0x1: Request            ???????????????????????!dou!??????????????ß›???Ready??≥ê";
CM_ SG_ 1044 HCU_2_G_HighTempLimit "0x0:¶ƒ????
0x1!mao!????????";
CM_ SG_ 1044 HCU_2_G_DchaFault "0x1£∫???????????¿H??????£¨??????????
???????????????????????????";
CM_ SG_ 1044 HCU_GearReturnWarn "Gear Return Warn";
CM_ SG_ 1044 HCU_ChargeFault "Charge Fault";
CM_ SG_ 1044 PRNDGearAct "Actual PRND gear as evaluated by HCU.";
CM_ SG_ 1044 HCU_SetSOCFed "Set SOC Feedback";
CM_ SG_ 1044 HCU_SocManageFed "Soc Manage Feedback";
CM_ SG_ 1044 HCU_RegenerateLevel "Regenerate Level";
CM_ SG_ 1044 HCU_RangeAval "Range Available";
CM_ SG_ 1044 HCU_EnergyFlow "Energy Flow";
CM_ BO_ 1034 "Source network message is \"Cyclic, 100ms\".
If no messages are received on source network, no messages are sent on the destination network.";
CM_ SG_ 1034 HCU_HighTempLimit "0x0:¶ƒ????
0x1:????????";
CM_ SG_ 1034 HCU_PowerModeChangeFail "Power Mode Change Fail
(Once triggered,send 5 frames 'Active 'immediately, then send 'No active')";
CM_ SG_ 1034 HCU_EmPwr "E-Motor power indication";
CM_ SG_ 1034 HCU_PowertrainFault "Powertrain fault";
CM_ SG_ 1034 HCU_PowerModeFed "Power mode Feedback";
CM_ SG_ 1034 HCU_PTReady "Drive Ready indication";
CM_ SG_ 1034 HCU_HVReady "HV Ready indication";
CM_ BO_ 1218 "Source network message is \"Cyclic, 100ms\".
If no messages are received on source network, no messages are sent on the destination network.";
CM_ SG_ 1218 LHM_1_DBL_FaultSts "DBL ??????";
CM_ SG_ 1218 LHM_1_DRLFaildSts "LHM  DRL Faild Status";
CM_ SG_ 1218 LHM_1_LHTurnLiFaildSts "LHM Left Hand Turn Light Faild Status";
CM_ SG_ 1218 LHM_1_ParkLiFaildSts "LHM Park Light Faild Status";
CM_ SG_ 1218 LHM_1_LoBeamFaildSts "LHM low Beam Faild Status";
CM_ SG_ 1218 LHM_1_HiBeamFaildSts "LHM High Beam Faild Status";
CM_ BO_ 1175 "Source network message is \"Cyclic, 100ms\".
If no messages are received on source network, no messages are sent on the destination network.";
CM_ SG_ 1175 IPB_ESP_15_CRC "CRC (SAE J1850 CRC-8)
Note: Details Please refer to specification??Standard Specification for CAN Data Link Layer_v1.1??section 2.3.2";
CM_ SG_ 1175 IPB_ESP_15_MessageCounter "Rolling message counter(the maximum value of Alive counter is 15)
Note: Details Please refer to specification??Standard Specification for CAN Data Link Layer_v1.1??section 2.3.1";
CM_ SG_ 1175 CST_Status "CST:Comfortable stop";
CM_ BO_ 1149 "Source network message is \"NoMsgSendType, /\".
If no messages are received on source network, no messages are sent on the destination network.";
CM_ BO_ 1110 "Source network message is \"NoMsgSendType, /\".
If no messages are received on source network, no messages are sent on the destination network.";
CM_ SG_ 906 IDCU_12_RmninfoTrig "HMI reminder information trigger";
CM_ SG_ 906 IDCU_12FCTAWarnRi "FCTA Warning Right";
CM_ SG_ 906 IDCU_12FCTAWarnLe "FCTA Warning Left";
CM_ SG_ 906 IDCU_12CPMod "Chery Pilot Mode
???????!dou!?????
???????????????
??????CP???????????????
??????CP??????????????
???????????????
??????NOC???????????????
??????NOC??????????????
CP??????????????????????!dou!?????????????????
NOC??????????????????????!dou!?????????????????
?????????????!dou!??????????????
???????????
???";
CM_ SG_ 906 IDCU_12Rmninfo "HMI reminder information";
CM_ SG_ 1248 IDCU_11_ALCDrvStysts "ALC Driver style status
?????????????DVD??????
???
????
????
???";
CM_ SG_ 1248 IDCU_11_ALCDrvrCfmONOFFsts "ALC Driver Confirmation ON/OFF key sts
?????????????????????????????????!dou!????????????????????????????????!dou!???????????
(ALC??????????)";
CM_ SG_ 1248 IDCU_11_CPONOFFsts "CheryPilot ON/OFF key status
??????????????????(CheryPilot)???????????";
CM_ SG_ 1248 IDCU_11_NOCONOFFsts "Navigation On CheryPilot ON/OFF key status
??????????????????????(Navigation On CheryPilot)???????????";
CM_ SG_ 1248 IDCU_11_HPAONOFFsts "???????????????????";
CM_ SG_ 1248 IDCU_11_ParkingchimeVoice "Chime?????";
CM_ SG_ 1248 IDCU_11_FCTBONOFFsts "FCTB ON/OFF key status
????????????";
CM_ SG_ 1248 IDCU_11_SpeedLmtNmberE "The speed limit threshold is adjusted relative to the signal, from -20% to 20%
?????????????????!dou!??-20%??20%";
CM_ SG_ 1248 IDCU_11_SpeedLmtNmberAb "Speed limit threshold adjustment signal, from -10 to 10
??????????????!dou!??-10??10";
CM_ SG_ 1248 IDCU_11_VoiceRem "IDCU_11_VoiceReminder
Sound style switch (unique to advanced ADAS)
???????ß›??????ADAS???ßµ?";
CM_ SG_ 1248 IDCU_11_DrvAssiStylests "Assist driver's default style selection Settings
???????????????????????!dou!IDCU??????";
CM_ SG_ 1248 IDCU_11_DCLCONOFFsts "Dial lever control lane change setting item switch state
???????????????????!dou!IDCU??????";
CM_ BO_ 903 "Source network message is \"Cyclic, 50ms\".
If no messages are received on source network, no messages are sent on the destination network.";
CM_ SG_ 903 FCM_FRM_6_VSetDis "setted target speed";
CM_ SG_ 903 FCM_FRM_6_AEBMode "AEB Mode";
CM_ SG_ 903 FCM_FRM_6_FCWMode "FCW Mode";
CM_ SG_ 903 FCM_FRM_6_HMI_Indicator "R152????????";
CM_ SG_ 903 FCM_FRM_6_TakeOverReq "Take Over Request";
CM_ SG_ 903 FCM_FRM_6_FCW_preWarning "FCW_preWarning";
CM_ SG_ 903 FCM_FRM_6_DistanceWarning "Distance Warning";
CM_ SG_ 903 FCM_FRM_6_TimeGapSetICM "Time Gap Set on the ICM";
CM_ SG_ 903 FCM_FRM_6_DrvrCfmSCFDispFb "Driver confirmation SCF interface displays request feedback";
CM_ SG_ 903 FCM_FRM_6_SCF_SpdLimUnit "SCF Speed limit unit";
CM_ SG_ 903 FCM_FRM_6_SCF_SpdLimSts "SCF Speed limit Status";
CM_ SG_ 903 FCM_FRM_6_SCF_PopoverReq "SCF popover request";
CM_ SG_ 903 FCM_FRM_6_ACCMode "ACC Mode
M32TFL2?????0x8??OFF mode?";
CM_ SG_ 903 FCM_FRM_6_Textinfo_Info "Text Information";
CM_ SG_ 903 FCM_FRM_6_TextinfoWarn "Text Information warning";
CM_ BO_ 1251 "Source network message is \"Cyclic, 100ms\".
If no messages are received on source network, no messages are sent on the destination network.";
CM_ SG_ 1251 TextinfoWarn "Text Information warning
M32TFL";
CM_ SG_ 1251 Textinfo_Info "Textinfo
M32TFL";
CM_ SG_ 1251 FCM_FRM_5_DAIONOFFSts "DAI status";
CM_ SG_ 1251 FCM_FRM_5_SCFONOFFSts "SCF status";
CM_ SG_ 1251 FCM_FRM_5_FCWONOFFSts "FCW status";
CM_ SG_ 1251 FCM_FRM_5_FCWSnvtySts "FCW Sensitivity status";
CM_ SG_ 1251 FCM_FRM_5_AEBONOFFSts "AEB status";
CM_ BO_ 1020 "Source network message is \"Cyclic, 50ms\".
If no messages are received on source network, no messages are sent on the destination network.";
CM_ SG_ 1020 FCM_10_EgoLeftLineHeatgAg "ICM display the Angle between vehicle and lane line";
CM_ SG_ 1020 FCM_10_ELKIntvMod "ELK Intervention Mode";
CM_ SG_ 1020 FCM_10_WarnModSts "Warning Mode status";
CM_ SG_ 1020 FCM_10_SLAONOFFSts "SLA ON/OFF status";
CM_ SG_ 1020 FCM_10_TJAICAExitTextInfoSts "TJAICA Exit Text Information status";
CM_ SG_ 1020 FCM_10_LDPTJAELKTakeoverReq "Take over request to driver";
CM_ SG_ 1020 FCM_10_TSINoParkWarn "TSI No Park Warning";
CM_ SG_ 1020 FCM_10_ELKSysSts "ELK System Status";
CM_ SG_ 1020 FCM_10_TJAICAEnaRcmend "Enable TJA/ICA is recommended";
CM_ SG_ 1020 FCM_10_TJAICATextinfo "TJA_ICA_Text information";
CM_ SG_ 1020 FCM_10_LDWSysSts "LDW System Status";
CM_ SG_ 1020 FCM_10_LDPSysSts "LDP System Status";
CM_ SG_ 1020 FCM_10_TLITrfcLi "TLI Traffic Light";
CM_ SG_ 1020 FCM_10_TSISgnLongStayDisp "TSI Sign Long Stay Display";
CM_ SG_ 1020 FCM_10_TLISysSts "TLI system Status";
CM_ SG_ 1020 FCM_10_TSISysSts "TSI System Status";
CM_ SG_ 1020 FCM_10_TSISgnForb "TSI Sign for forbid";
CM_ SG_ 1020 FCM_10_TSISgnGiWay "TSI Sign for give way";
CM_ BO_ 1245 "Source network message is \"Cyclic, 100ms\".
If no messages are received on source network, no messages are sent on the destination network.";
CM_ SG_ 1245 FCM_5_SLAmodeSWSet "Speed limit warning switch signal
?????????ß›????";
CM_ SG_ 1245 FCM_5_SpeedLmtNmberE "The speed limit threshold is adjusted relative to the signal, from -20% to 20%
?????????????????!dou!??-20%??20%";
CM_ SG_ 1245 FCM_5_SpeedLmtNmberAb "Speed limit threshold adjustment signal, from -10 to 10
??????????????!dou!??-10??10";
CM_ SG_ 1245 SLASpdLimChgAudSwSts "????ß›????????????????";
CM_ SG_ 1245 FCM_5_ELKONOFFSts "ELK status";
CM_ SG_ 1245 FCM_5_LDWLDPSnvtySts "LDW LDP Senstitivity status";
CM_ SG_ 1245 FCM_5_LDPONOFFSts "LDP status";
CM_ SG_ 1245 FCM_5_WarnModSts "Warning Mode status";
CM_ SG_ 1245 FCM_5_LDWONOFFSts "LDW status";
CM_ SG_ 1245 FCM_5_TLIONOFFSts "TLI status";
CM_ SG_ 1245 FCM_5_TSIONOFFSts "TSI status";
CM_ SG_ 1245 FCM_5_HMAONOFFSts "HMA status";
CM_ SG_ 1245 FCM_5_IESONOFFSts "IES status";
CM_ SG_ 1245 FCM_5_SLAONOFFSts "SLA ON/OFF status";
CM_ SG_ 1245 FCM_5_TJAICAExitTextInfoSts "TJAICA Exit Text Information status";
CM_ BO_ 775 "Source network message is \"Cyclic, 20ms\".
If no messages are received on source network, no messages are sent on the destination network.";
CM_ SG_ 775 FCM_2_SLASpdlimitUnits "SLA Speed limit Units";
CM_ SG_ 775 FCM_2_SpdLimtyp "speed limit type";
CM_ SG_ 775 SLASpdlimit "SLA Speed limit
Add 135-180 for European region";
CM_ SG_ 775 FCM_2_SLAmodeSWSet "Speed limit warning switch signal
?????????ß›????";
CM_ SG_ 775 FCM_2_SCFSpdlimWarn "SCF Speed limit Warning";
CM_ SG_ 775 LDW_ELK_TJA_LDPRightVisuali "LDW_ELK_TJA_LDP Right Visualization";
CM_ SG_ 775 LDW_ELK_TJA_LDPLeftVisuali "LDW_ELK_TJA_LDP Left Visualization";
CM_ SG_ 1270 Yellowwarning "??P??";
CM_ SG_ 1270 Redwarning "??P??";
CM_ SG_ 1270 RWUActive "???????£∫??????CDPActive=1_active??RWUActive=1_active£¨???????????";
CM_ SG_ 1270 EPBWarningMessage "??????????????????????°¢????????°¢??????
001!mao!????????????¶ƒ?????????
010!mao!????????¶ƒ???????????
011!mao!????????????";
CM_ SG_ 1270 EPBStatus "Current state of APB actuator connected to ECU
EPB????????";
CM_ BO_ 896 "Source network message is \"Cyclic, 100ms\".
If no messages are received on source network, no messages are sent on the destination network.";
CM_ SG_ 896 EPS_EOTLearning_Sts "Indicates the status of EPS EOT(end of travel) learning, displayed on the DMC(ICM)";
CM_ SG_ 896 EPS_1_MessageCounter "Rolling message counter(the maximum value of Alive counter is 15)
Note: Details Please refer to specification??Standard Specification for CAN Data Link Layer_v1.1??section 2.3.1";
CM_ SG_ 896 EPS_AssistanceStyle_Sts "0x0: sport
0x1: comfort
0x3: normal (reserved)
0x4: Reserved";
CM_ BO_ 1240 "Source network message is \"Cyclic, 100ms\".
If no messages are received on source network, no messages are sent on the destination network.";
CM_ SG_ 1240 EMS_BoostP "boost pressure";
CM_ BO_ 1057 "Source network message is \"Cyclic, 100ms\".
If no messages are received on source network, no messages are sent on the destination network.";
CM_ SG_ 1057 GasPedalPosition "Driver/Cruise control
This signal including compositive informations which are actual gas pedal position and dummy Cruise control gas pedal position";
CM_ SG_ 1057 LimitSpeedSts "Off£∫??????????????
Standby!mao!??????????????¶ƒ????
Overspeed!mao!????????????????????????
Limit!mao!??????????
Cancel!mao!????????????????
Kickdown!mao!????????";
CM_ SG_ 1057 CruiseLimitSpeedValue "????⁄Ö?/?????";
CM_ BO_ 640 "Source network message is \"Cyclic, 100ms\".
If no messages are received on source network, no messages are sent on the destination network.";
CM_ SG_ 640 OilPressureWarningLamp "Oil Pressure Warning Lamp
?????????????";
CM_ SG_ 640 EMS_EngineSts_Actual "PHEV??£¨????????????????????";
CM_ SG_ 640 TargetGearPosition "??????MT?£¨?????????";
CM_ SG_ 640 FuelRollingCounter "????????????";
CM_ SG_ 640 GPFWarning "This signal indicates the status of GPF warning which need ICM to  inform driver. 
0x1: Green light, may display \"GPF is full. Need  highspeed road drive to clean GPF??
0x2: Yellow light, may display\"GPF is overlimited. Need to contact 4s to check and repair GPF\"";
CM_ SG_ 640 EngineSts "PHEV??£¨???????????????????";
CM_ SG_ 640 SSMStatus "??????????????????
0-Reset Start/Stop not active(any engine condition possible)
??????
1-StandbyS/S active, engine off(waiting for initial keybutton start)
?????!dou!?????????¬C??
2- StoppedS/S active, engine standstill
3- Starter RestartSS/ active starter engine is turning 
??????????????????
4 - Engine RestartS/S active, engine runs up
?????????????????????????!dou!??????????????????!dou!??????ß÷?0!dou!???????????!dou!??????????????????????????!dou!????????????!dou!???????????????????
5 - OperationS/S active, engine is running
6 - Auto StoppingS/S active, engine is turning but no fuel injection anymore
????ISS????!dou!??????000";
CM_ SG_ 1291 Pos3_FragranceTypesSts_sec "¶À??3???????????????:
Type1~Type255?????????????????
0x0: Not active
0x1~0xFF:Type1~Type255";
CM_ SG_ 1291 Pos2_FragranceTypesSts_sec "¶À??2???????????????:
Type1~Type255?????????????????
0x0: Not active
0x1~0xFF:Type1~Type255";
CM_ SG_ 1291 Pos1_FragranceTypesSts_sec "¶À??1???????????????:
Type1~Type255?????????????????
0x0: Not active
0x1~0xFF:Type1~Type255";
CM_ SG_ 1277 CLM_10_SteerWhlHeatgSwt "Steering Wheel heating?????????";
CM_ SG_ 1277 CLM_WindowCmd "??????????£∫
1!dun!?????????????!dun!???????!dun!?????!dun!?????!dun!??????!dun!???????!dun!????????????????
2!dun!???open??????!dun!close??????!dun!comfort????¥Ñ??????????!dou!?????????????????????comfort??˛ü
3!dun!??ß’????!dou!?????????????????????!dou!????????Not active????";
CM_ SG_ 1277 AUTODefrostlevelSts "???????????????";
CM_ SG_ 1277 CLM_10_FRSeatVentilationCmd "????????????????";
CM_ SG_ 1277 CLM_10_FLSeatVentilationCmd "????????????????";
CM_ SG_ 1277 CLM_10_FRSeatHeatLevelCmd "?????????¶Ã??????";
CM_ SG_ 1277 CLM_10_FLSeatHeatLevelCmd "?????????¶Ã??????";
CM_ SG_ 1277 CLM_10_CLMIntlgDeodnSts "CLMIntelligentDeodorizationSts
????????¶∆????????";
CM_ SG_ 1277 CLM_10_CLMSupHeatgSts "CLMSuperHeatingSts
?????????????????";
CM_ SG_ 1277 CLM_10_CLMSupCoolgSts "CLMSuperCoolingSts
?????????°„???????";
CM_ SG_ 1277 CLM_10_SeRowDispSts "Second Row display Status";
CM_ SG_ 1277 CLM_10_RfgtLkDispSts "Refrigerant Leakage Display Status";
CM_ SG_ 1277 CLM_10_ReRowDispSts "Rear Row display  Status";
CM_ SG_ 1277 CLM_10_ReRowBlowSpdLvlSts "Rear Row Blow speed level Status";
CM_ SG_ 1277 CLM_10_ReRowWorkSts "Rear Row Work  Status";
CM_ SG_ 1277 CLM_10_RmnDispSts "Reminder Display Status";
CM_ SG_ 1277 IncarTemperature_C "???????";
CM_ SG_ 1277 CLM_10_AQSDispSts "AQS Display Status";
CM_ SG_ 1277 SelfTestResult2 "fault display on DVD with SelfTestActive
????????????????DVD????????!dou!DVD?????????????????SelfTestActive?????";
CM_ SG_ 1277 IntelligentCustomSts "ON:?????????????
OFF!mao!????????????";
CM_ SG_ 1277 CLM_10_SeRowWorkSts "Second Row Working status
??????????";
CM_ SG_ 1277 CLM_10_SeRowBlowSpdLvlDispSts "Second Row Blow speed level display status
??????????¶À";
CM_ SG_ 1277 PtcHeatgSts "Ptc Heating Status
ON:??????????????
OFF!mao!?????????????";
CM_ SG_ 1171 CLM_6_CbnAntiOverHeatSts "???????????????£∫??°¢??A/C°¢??";
CM_ SG_ 1171 CLM_6_warn_sts "CLM_warn_statues
T19CEV ????????????????????????";
CM_ SG_ 1171 AQSAutoRunSts "AQS??????????";
CM_ BO_ 1334 "Source network message is \"Cyclic, 500ms\".
If no messages are received on source network, no messages are sent on the destination network.";
CM_ SG_ 1334 FragranCeconsistenceLevelSts "??????????????";
CM_ SG_ 1334 Pos3_FragranceTypesSts "¶À??3???????????????:
Type1,Type2 ??Type3?????????????????
Unfilled ???¶À??¶ƒ??¶ ?????";
CM_ SG_ 1334 Pos2_FragranceTypesSts "¶À??2???????????????:
Type1,Type2 ??Type3?????????????????
Unfilled ???¶À??¶ƒ??¶ ?????";
CM_ SG_ 1334 PM2_5AutoRunSetSts "?????????????????????";
CM_ SG_ 1334 PM2_5_Incar_Level "???????PM2.5???????????????????????";
CM_ SG_ 1334 PM2_5_Outcar_Level "???????PM2.5???????????????????????";
CM_ SG_ 1334 FragranceDisplaysts "???????????????";
CM_ SG_ 1334 ACModeCustomSts "????????????????";
CM_ SG_ 1334 FragranceWelcomeModeSts "???????????";
CM_ SG_ 1334 RefreshFunctionSts "?????????????????";
CM_ SG_ 1334 Pos1_FragranceTypesSts "¶À??1???????????????:
Type1,Type2 ??Type3?????????????????
Unfilled ???¶À??¶ƒ??¶ ?????";
CM_ SG_ 1334 PM2_5AutoRunSts "?????????????£¨????????????????????????????????
???????????????????????!dou!????????";
CM_ SG_ 1334 FragranceSWSts "????????????
??????????0x0!mao!On";
CM_ SG_ 1334 AutoBltCalllowBlowSpeedSts "???????????????????????";
CM_ SG_ 1334 AutoParkInnerCirculationSts "???????????????????";
CM_ SG_ 1334 PM2_5_IncarSts "PM2.5_IncarSts????PM2.5?????????????£¨??0X1????????°§?????°§????";
CM_ SG_ 1334 PM2_5_ExtSts "PM2.5_ExtSts????PM2.5?????????????£¨??0X1????????°§?????°§????";
CM_ SG_ 1334 PM2_5_ext "????PM2.5?";
CM_ SG_ 1334 FragranceShortageWarning "?????????????
??????bit¶À???????¶À???
????!mao!111!dou!??¶À??1!dou!???¶À??3?????????ßﬁ?¶À??1!dou!???¶À??2??????????¶À??1!dou!???¶À??1??????????????1!dou!??????????!dou!??????";
CM_ SG_ 1334 ION_Function_Sts "???????????????,???????????????£∫
0x0 ??????????????
0x1 ?????????
0x2 ????????";
CM_ SG_ 1334 PM2_5_incar "????PM2.5?";
CM_ BO_ 1333 "Source network message is \"Cyclic, 100ms\".
If no messages are received on source network, no messages are sent on the destination network.";
CM_ SG_ 1333 AUTODefrostDisplaySts "????????????????£¨??????????????????(???????????????£¨??????????????£¨????????)";
CM_ SG_ 1333 TempKnobRollingCounter "?????/??????????
???!mao!????????????????16!dou!?????????????10000??

?æT????!dou!IPM????RRM???????????";
CM_ SG_ 1333 AUTODefrostForceOpenSts "???????????????????£¨??????????????????(?????????????£¨?????????????????????£¨????????)";
CM_ SG_ 1333 AQSAutoRunSetSts "CLM???????AQS????????";
CM_ SG_ 1333 PM2_5Displaysts "?????????DVD£¨?????????????????????";
CM_ SG_ 1333 PM2_5overproofDisplaySts "????????¶ƒ??????????£¨????PM2.5????????£¨DVD?????????????????????????";
CM_ SG_ 1333 FiltertchangeDisplaySts "?????ß‡????????DVD?????????????????";
CM_ SG_ 1333 REARInhibitSts "???????????????ßÿ????????";
CM_ SG_ 1333 AUTODefrostOnSts "???????????????";
CM_ SG_ 1104 OBDDiagnosisReqInd "?????????
1!mao!CGW???Diag CAN????????????1(??????CAN???Diag CAN????????????????)
0!mao!CGW 10s??????Diag CAN????????????0(??????CAN???Diag CAN????????????????)
TBOX!mao!???1???????????????????????";
CM_ SG_ 1183 BMSH_InsulationSts "HV  Insulation Status
For EV :use 0x0:Level 0;
0x1:Level 1;
0x2:Level 2;
0x3:Level 3
For PHEV:use 0x0:Insulation OK ??default??;
0x1: Insulation Warning;
0x2: Insulation Error;
0x3: Minor leakage repair request??????????????????????2???????????????!dou!3?????????????";
CM_ SG_ 1183 BMSH_BattVolt "Battery Voltage";
CM_ SG_ 1183 BMSH_BatteryCurrent "Battery Current";
CM_ SG_ 1183 BMSH_PackChargingThermalSt "Pack Charging Thermal Status";
CM_ SG_ 1103 BMS_8_PackDCChargingSt "?????";
CM_ SG_ 1103 BMS_8_CC2Sts "??????????????????";
CM_ SG_ 1103 BMSH_SOH "Battery SOH";
CM_ SG_ 1103 BMSH_LeftChargeTime "Left Charge Time
0x1:charging maintain";
CM_ SG_ 1103 BMSH_PackInstantRecoveryPower "Pack instantaneous Recovery Power";
CM_ SG_ 1083 BMSH_BattFaultLampSts "Battery system Fault Lamp Status";
CM_ SG_ 1083 BMSH_PackThermalRunawayLight "Pack Thermal Runaway Light";
CM_ SG_ 1083 BMSH_SOCDisp "SOC display";
CM_ SG_ 1379 BMSH_KeepWarmTimeSum "??????????";
CM_ SG_ 1379 BMSH_KeepWarmSelfWakeupTimes "????????????";
CM_ SG_ 1379 BMSH_keepWarmNextTimeRSet "?°‰¶À???????⁄Ö";
CM_ SG_ 1228 BMSH_CC2_ConnectSts "CC2 connect state";
CM_ SG_ 1228 BMSH_CC_ConnectDischarSts "V2L connect states";
CM_ SG_ 1228 BMSH_CC_ConnectSts "CC connect states";
CM_ SG_ 1228 BMSH_KeepwarmSts "??????";
CM_ SG_ 1228 BMSH_KeepwarmFunctSts "???1????????
?????";
CM_ SG_ 1228 BMSH_ElectronicLockSts "Electronic Lock Sts";
CM_ SG_ 1228 BMSH_PreWarmDis "preheat and keepwarm indication";
CM_ SG_ 1228 Pack_ChargeStopSOC "Pack Charge Stop SOC";
CM_ SG_ 1228 BMSH_PackchgSTS "?????????????";
CM_ SG_ 1228 BMSH_28_RollgCntr1 "Rolling message counter(the maximum value of Alive counter is 15) Note: Details Please refer to specification??EE Standard Specification for CAN FD Network Implementation??section 2.3.1";
CM_ SG_ 1228 BMSH_28_CRC1 "CRC (SAE J1850 CRC-8) Note: Details Please refer to specification??EE Standard Specification for CAN FD Network Implementation??section 2.3.2";
CM_ BO_ 1178 "Source network message is \"Cyclic, 100ms\".
If no messages are received on source network, no messages are sent on the destination network.";
CM_ SG_ 1178 BDM_26_RRWinPosn "Rear Right Window Position";
CM_ SG_ 1178 BDM_26_RLWinPosn "Rear Left Window Position";
CM_ SG_ 1178 BDM_26_FRWinPosn "Front Right Window Position";
CM_ SG_ 1178 BDM_26_FLWinPosn "Front Left Window Position";
CM_ SG_ 1007 BDM_25_AmbBrightness "?????";
CM_ SG_ 1007 BDM_25_FWBrightness "????";
CM_ BO_ 1287 "Source network message is \"Cyclic, 100ms\".
If no messages are received on source network, no messages are sent on the destination network.";
CM_ SG_ 1287 BDM_LightMainSwitchSts "ß≥??°¢????°¢Auto????¶À??";
CM_ SG_ 1287 BDM_RearMirrorFoldSts "??????????";
CM_ SG_ 1287 DriverSeatMsgStr_LvlSts "??????";
CM_ SG_ 1287 DriverSeatMsg_ModeSts "0x0:????
0x1:??????
0x2:®®????
0x3:??????
0x4:?ùH??
0x5:?????";
CM_ SG_ 1287 BCM_22_WelcomelampSts "???????";
CM_ SG_ 1287 BCM_22_WiprSnvtySetFb "Wiper Sensitivity Set feedback";
CM_ SG_ 1287 BCM_22_Rool_OperateSts "StartUp£∫??????";
CM_ SG_ 1287 PassSeatMsg_ModeSts "0x0:????
0x1:??????
0x2:®®????
0x3:??????
0x4:?ùH??
0x5:?????";
CM_ SG_ 939 IBS_QuiescentCurrent "vehicle quiescent current during parking mode measured by IBS.
raw value 253  Overflow
raw value 254 Out of bounds
raw value 255  Invalid";
CM_ BO_ 936 "Source network message is \"Cyclic, 100ms\".
If no messages are received on source network, no messages are sent on the destination network.";
CM_ SG_ 936 IBS_SOF_V1 "Forecast of minimal voltage during cranking.Invalid Raw Value:255.";
CM_ SG_ 936 IBS_STAT_SOC "Current reliability of signal IBS_SOC";
CM_ SG_ 936 IBS_SOH "The maximum possible amount of a fully charged battery (aged), relative to the nominal battery capacity; 101-254 reserved.Invalid Raw Value:255.";
CM_ SG_ 936 IBS_SOC "Battery state of charge calculated from IBS; 101-254 reserved;Invalid Raw Value:255.";
CM_ BO_ 934 "Source network message is \"Cyclic, 100ms\".
If no messages are received on source network, no messages are sent on the destination network.";
CM_ SG_ 934 IBS_CurrentRange "Current used range of IBS_Current measurement";
CM_ SG_ 934 IBS_BatteryTemp "Battery temperature from IBS.Invalid Raw Value:255.";
CM_ SG_ 934 IBS_Current "Current measured battery current.
Initial value:
65535/1024-32,
65535/128-256,
65535/16-2048.
Factor:
1/1024,
1/128,
1/16.
Offset:
-32,
-256,
-2048.
Minimum:
-1,
-200,
-1500.
Maximum:
1,
200,
1500.";
CM_ SG_ 934 IBS_Voltage "Current measured battery voltage, max value is 18V.Invalid Raw Value:16383.";
BA_DEF_  "NmAsrCanMsgCycleTime" INT 1000 1000;
BA_DEF_  "NmAsrRepeatMessageTime" INT 3000 3000;
BA_DEF_  "NmAsrWaitBusSleepTime" INT 1500 1500;
BA_DEF_  "NmAsrTimeoutTime" INT 2500 2500;
BA_DEF_  "NmAsrBaseAddress" HEX 0 2047;
BA_DEF_  "NmAsrMessageCount" INT 128 128;
BA_DEF_  "NmType" STRING ;
BA_DEF_  "ILTxTimeout" INT 0 65535;
BA_DEF_  "Manufacturer" STRING ;
BA_DEF_ SG_  "GenSigTimeoutValue" INT 0 2147483647;
BA_DEF_ SG_  "GenSigStartValue" INT 0 2147483647;
BA_DEF_ SG_  "GenSigInactiveValue" INT 0 2147483647;
BA_DEF_ BO_  "TpTxIndex" INT 0 255;
BA_DEF_ BO_  "DiagUudtResponse" ENUM  "False","True";
BA_DEF_ BO_  "DiagResponse" ENUM  "No","Yes";
BA_DEF_ BO_  "DiagRequest" ENUM  "No","Yes";
BA_DEF_ BO_  "DiagState" ENUM  "No","Yes";
BA_DEF_ BO_  "NmAsrMessage" ENUM  "No","Yes";
BA_DEF_ BO_  "GenMsgFastOnStart" INT 0 65535;
BA_DEF_ BO_  "GenMsgCycleTimeFast" INT 0 65535;
BA_DEF_ BO_  "GenMsgNrOfRepetition" INT 0 65535;
BA_DEF_ BO_  "GenMsgStartDelayTime" INT 0 65535;
BA_DEF_ BO_  "GenMsgCycleTime" INT 0 65535;
BA_DEF_ BO_  "GenMsgDelayTime" INT 0 65535;
BA_DEF_ SG_  "GenSigSendType" ENUM  "Cyclic","OnWrite","OnWriteWithRepetition","OnChange","OnChangeWithRepetition","IfActive","IfActiveWithRepetition","NoSigSendType","OnChangeAndIfActive","OnChangeAndIfActiveWithRepetition";
BA_DEF_ BO_  "GenMsgSendType" ENUM  "Cyclic","NotUsed","NotUsed","NotUsed","NotUsed","NotUsed","NotUsed","IfActive","NoMsgSendType";
BA_DEF_ BO_  "GenMsgILSupport" ENUM  "No","Yes";
BA_DEF_ BU_  "NmStationAddress" HEX 0 255;
BA_DEF_ BU_  "NmAsrCanMsgReducedTime" INT 500 818;
BA_DEF_ BU_  "NmAsrCanMsgCycleOffset" INT 0 635;
BA_DEF_ BU_  "NmAsrNodeIdentifier" HEX 0 255;
BA_DEF_ BU_  "NmAsrNode" ENUM  "No","Yes";
BA_DEF_ BU_  "ILUsed" ENUM  "No","Yes";
BA_DEF_REL_ BU_SG_REL_  "GenSigTimeoutTime" INT 0 65535;
BA_DEF_DEF_  "NmAsrCanMsgCycleTime" 1000;
BA_DEF_DEF_  "NmAsrRepeatMessageTime" 3000;
BA_DEF_DEF_  "NmAsrWaitBusSleepTime" 1500;
BA_DEF_DEF_  "NmAsrTimeoutTime" 2500;
BA_DEF_DEF_  "NmAsrBaseAddress" 1536;
BA_DEF_DEF_  "NmAsrMessageCount" 128;
BA_DEF_DEF_  "NmType" "NmAsr";
BA_DEF_DEF_  "ILTxTimeout" 0;
BA_DEF_DEF_  "Manufacturer" "Vector";
BA_DEF_DEF_  "GenSigTimeoutValue" 0;
BA_DEF_DEF_  "GenSigStartValue" 0;
BA_DEF_DEF_  "GenSigInactiveValue" 0;
BA_DEF_DEF_  "TpTxIndex" 0;
BA_DEF_DEF_  "DiagUudtResponse" "False";
BA_DEF_DEF_  "DiagResponse" "No";
BA_DEF_DEF_  "DiagRequest" "No";
BA_DEF_DEF_  "DiagState" "No";
BA_DEF_DEF_  "NmAsrMessage" "No";
BA_DEF_DEF_  "GenMsgFastOnStart" 0;
BA_DEF_DEF_  "GenMsgCycleTimeFast" 0;
BA_DEF_DEF_  "GenMsgNrOfRepetition" 3;
BA_DEF_DEF_  "GenMsgStartDelayTime" 0;
BA_DEF_DEF_  "GenMsgCycleTime" 0;
BA_DEF_DEF_  "GenMsgDelayTime" 0;
BA_DEF_DEF_  "GenSigSendType" "NoSigSendType";
BA_DEF_DEF_  "GenMsgSendType" "NoMsgSendType";
BA_DEF_DEF_  "GenMsgILSupport" "No";
BA_DEF_DEF_  "NmStationAddress" 255;
BA_DEF_DEF_  "NmAsrCanMsgReducedTime" 575;
BA_DEF_DEF_  "NmAsrCanMsgCycleOffset" 0;
BA_DEF_DEF_  "NmAsrNodeIdentifier" 255;
BA_DEF_DEF_  "NmAsrNode" "No";
BA_DEF_DEF_  "ILUsed" "No";
BA_DEF_DEF_REL_ "GenSigTimeoutTime" 0;
BA_ "ILUsed" BU_ DMC 1;
BA_ "NmAsrNode" BU_ DMC 1;
BA_ "NmAsrNodeIdentifier" BU_ DMC 24;
BA_ "NmStationAddress" BU_ DMC 24;
BA_ "GenMsgILSupport" BO_ 1441 1;
BA_ "GenMsgDelayTime" BO_ 1441 5;
BA_ "GenMsgNrOfRepetition" BO_ 1441 2;
BA_ "GenMsgCycleTimeFast" BO_ 1441 100;
BA_ "GenMsgCycleTime" BO_ 636 20;
BA_ "GenMsgSendType" BO_ 636 0;
BA_ "GenMsgILSupport" BO_ 636 1;
BA_ "GenMsgNrOfRepetition" BO_ 636 0;
BA_ "DiagState" BO_ 2015 1;
BA_ "GenMsgNrOfRepetition" BO_ 2015 0;
BA_ "GenMsgCycleTime" BO_ 1259 100;
BA_ "GenMsgNrOfRepetition" BO_ 1259 0;
BA_ "GenMsgSendType" BO_ 1259 0;
BA_ "GenMsgILSupport" BO_ 1259 1;
BA_ "GenMsgCycleTime" BO_ 1257 100;
BA_ "GenMsgNrOfRepetition" BO_ 1257 0;
BA_ "GenMsgSendType" BO_ 1257 0;
BA_ "GenMsgILSupport" BO_ 1257 1;
BA_ "GenMsgCycleTime" BO_ 1250 100;
BA_ "GenMsgNrOfRepetition" BO_ 1250 0;
BA_ "GenMsgSendType" BO_ 1250 0;
BA_ "GenMsgILSupport" BO_ 1250 1;
BA_ "GenMsgCycleTime" BO_ 928 20;
BA_ "GenMsgNrOfRepetition" BO_ 928 0;
BA_ "GenMsgSendType" BO_ 928 0;
BA_ "GenMsgILSupport" BO_ 928 1;
BA_ "GenMsgCycleTime" BO_ 926 20;
BA_ "GenMsgNrOfRepetition" BO_ 926 0;
BA_ "GenMsgSendType" BO_ 926 0;
BA_ "GenMsgILSupport" BO_ 926 1;
BA_ "GenMsgCycleTime" BO_ 1261 100;
BA_ "GenMsgNrOfRepetition" BO_ 1261 0;
BA_ "GenMsgSendType" BO_ 1261 0;
BA_ "GenMsgILSupport" BO_ 1261 1;
BA_ "GenMsgCycleTime" BO_ 769 100;
BA_ "GenMsgNrOfRepetition" BO_ 769 0;
BA_ "GenMsgSendType" BO_ 769 0;
BA_ "GenMsgILSupport" BO_ 769 1;
BA_ "GenMsgCycleTime" BO_ 1206 100;
BA_ "GenMsgNrOfRepetition" BO_ 1206 0;
BA_ "GenMsgSendType" BO_ 1206 0;
BA_ "GenMsgILSupport" BO_ 1206 1;
BA_ "GenMsgCycleTime" BO_ 1202 100;
BA_ "GenMsgNrOfRepetition" BO_ 1202 0;
BA_ "GenMsgSendType" BO_ 1202 0;
BA_ "GenMsgILSupport" BO_ 1202 1;
BA_ "GenMsgCycleTime" BO_ 1194 100;
BA_ "GenMsgNrOfRepetition" BO_ 1194 0;
BA_ "GenMsgSendType" BO_ 1194 0;
BA_ "GenMsgILSupport" BO_ 1194 1;
BA_ "GenMsgCycleTime" BO_ 1190 100;
BA_ "GenMsgNrOfRepetition" BO_ 1190 0;
BA_ "GenMsgSendType" BO_ 1190 0;
BA_ "GenMsgILSupport" BO_ 1190 1;
BA_ "GenMsgCycleTime" BO_ 1186 100;
BA_ "GenMsgNrOfRepetition" BO_ 1186 0;
BA_ "GenMsgSendType" BO_ 1186 0;
BA_ "GenMsgILSupport" BO_ 1186 1;
BA_ "GenMsgCycleTimeFast" BO_ 1129 100;
BA_ "GenMsgDelayTime" BO_ 1129 5;
BA_ "GenMsgILSupport" BO_ 1129 1;
BA_ "GenMsgCycleTime" BO_ 1058 100;
BA_ "GenMsgNrOfRepetition" BO_ 1058 0;
BA_ "GenMsgSendType" BO_ 1058 0;
BA_ "GenMsgILSupport" BO_ 1058 1;
BA_ "GenMsgCycleTime" BO_ 1170 100;
BA_ "GenMsgNrOfRepetition" BO_ 1170 0;
BA_ "GenMsgSendType" BO_ 1170 0;
BA_ "GenMsgILSupport" BO_ 1170 1;
BA_ "GenMsgCycleTime" BO_ 924 10;
BA_ "GenMsgNrOfRepetition" BO_ 924 0;
BA_ "GenMsgSendType" BO_ 924 0;
BA_ "GenMsgILSupport" BO_ 924 1;
BA_ "GenMsgCycleTime" BO_ 1203 100;
BA_ "GenMsgNrOfRepetition" BO_ 1203 0;
BA_ "GenMsgSendType" BO_ 1203 0;
BA_ "GenMsgILSupport" BO_ 1203 1;
BA_ "GenMsgCycleTime" BO_ 1075 100;
BA_ "GenMsgNrOfRepetition" BO_ 1075 0;
BA_ "GenMsgSendType" BO_ 1075 0;
BA_ "GenMsgILSupport" BO_ 1075 1;
BA_ "GenMsgCycleTime" BO_ 1201 100;
BA_ "GenMsgNrOfRepetition" BO_ 1201 0;
BA_ "GenMsgSendType" BO_ 1201 0;
BA_ "GenMsgILSupport" BO_ 1201 1;
BA_ "GenMsgCycleTime" BO_ 1032 100;
BA_ "GenMsgDelayTime" BO_ 1032 5;
BA_ "GenMsgNrOfRepetition" BO_ 1032 0;
BA_ "GenMsgSendType" BO_ 1032 0;
BA_ "GenMsgILSupport" BO_ 1032 1;
BA_ "GenMsgCycleTime" BO_ 1208 100;
BA_ "GenMsgNrOfRepetition" BO_ 1208 0;
BA_ "GenMsgSendType" BO_ 1208 0;
BA_ "GenMsgILSupport" BO_ 1208 1;
BA_ "GenMsgCycleTime" BO_ 1339 100;
BA_ "GenMsgNrOfRepetition" BO_ 1339 0;
BA_ "GenMsgSendType" BO_ 1339 0;
BA_ "GenMsgILSupport" BO_ 1339 1;
BA_ "GenMsgCycleTime" BO_ 1042 100;
BA_ "GenMsgNrOfRepetition" BO_ 1042 0;
BA_ "GenMsgSendType" BO_ 1042 0;
BA_ "GenMsgILSupport" BO_ 1042 1;
BA_ "GenMsgCycleTime" BO_ 998 50;
BA_ "GenMsgNrOfRepetition" BO_ 998 0;
BA_ "GenMsgSendType" BO_ 998 0;
BA_ "GenMsgILSupport" BO_ 998 1;
BA_ "GenMsgCycleTime" BO_ 1125 100;
BA_ "GenMsgNrOfRepetition" BO_ 1125 0;
BA_ "GenMsgSendType" BO_ 1125 0;
BA_ "GenMsgILSupport" BO_ 1125 1;
BA_ "GenMsgCycleTime" BO_ 1124 100;
BA_ "GenMsgNrOfRepetition" BO_ 1124 0;
BA_ "GenMsgSendType" BO_ 1124 0;
BA_ "GenMsgILSupport" BO_ 1124 1;
BA_ "GenMsgCycleTime" BO_ 850 50;
BA_ "GenMsgNrOfRepetition" BO_ 850 0;
BA_ "GenMsgSendType" BO_ 850 0;
BA_ "GenMsgILSupport" BO_ 850 1;
BA_ "GenMsgCycleTime" BO_ 1195 100;
BA_ "GenMsgNrOfRepetition" BO_ 1195 0;
BA_ "GenMsgSendType" BO_ 1195 0;
BA_ "GenMsgILSupport" BO_ 1195 1;
BA_ "GenMsgCycleTime" BO_ 1159 100;
BA_ "GenMsgNrOfRepetition" BO_ 1159 0;
BA_ "GenMsgSendType" BO_ 1159 0;
BA_ "GenMsgILSupport" BO_ 1159 1;
BA_ "GenMsgCycleTime" BO_ 1142 100;
BA_ "GenMsgNrOfRepetition" BO_ 1142 0;
BA_ "GenMsgSendType" BO_ 1142 0;
BA_ "GenMsgILSupport" BO_ 1142 1;
BA_ "GenMsgCycleTime" BO_ 1046 100;
BA_ "GenMsgNrOfRepetition" BO_ 1046 0;
BA_ "GenMsgSendType" BO_ 1046 0;
BA_ "GenMsgILSupport" BO_ 1046 1;
BA_ "GenMsgCycleTime" BO_ 1044 100;
BA_ "GenMsgNrOfRepetition" BO_ 1044 0;
BA_ "GenMsgSendType" BO_ 1044 0;
BA_ "GenMsgILSupport" BO_ 1044 1;
BA_ "GenMsgCycleTime" BO_ 1034 100;
BA_ "GenMsgNrOfRepetition" BO_ 1034 0;
BA_ "GenMsgSendType" BO_ 1034 0;
BA_ "GenMsgILSupport" BO_ 1034 1;
BA_ "GenMsgCycleTime" BO_ 1218 100;
BA_ "GenMsgNrOfRepetition" BO_ 1218 0;
BA_ "GenMsgSendType" BO_ 1218 0;
BA_ "GenMsgILSupport" BO_ 1218 1;
BA_ "GenMsgCycleTime" BO_ 1175 100;
BA_ "GenMsgNrOfRepetition" BO_ 1175 0;
BA_ "GenMsgSendType" BO_ 1175 0;
BA_ "GenMsgILSupport" BO_ 1175 1;
BA_ "GenMsgCycleTimeFast" BO_ 1149 100;
BA_ "GenMsgDelayTime" BO_ 1149 5;
BA_ "GenMsgILSupport" BO_ 1149 1;
BA_ "GenMsgCycleTimeFast" BO_ 1110 100;
BA_ "GenMsgDelayTime" BO_ 1110 5;
BA_ "GenMsgILSupport" BO_ 1110 1;
BA_ "GenMsgCycleTime" BO_ 906 100;
BA_ "GenMsgNrOfRepetition" BO_ 906 0;
BA_ "GenMsgSendType" BO_ 906 0;
BA_ "GenMsgILSupport" BO_ 906 1;
BA_ "GenMsgCycleTime" BO_ 1248 100;
BA_ "GenMsgNrOfRepetition" BO_ 1248 0;
BA_ "GenMsgSendType" BO_ 1248 0;
BA_ "GenMsgILSupport" BO_ 1248 1;
BA_ "GenMsgCycleTime" BO_ 903 50;
BA_ "GenMsgNrOfRepetition" BO_ 903 0;
BA_ "GenMsgSendType" BO_ 903 0;
BA_ "GenMsgILSupport" BO_ 903 1;
BA_ "GenMsgCycleTime" BO_ 1251 100;
BA_ "GenMsgNrOfRepetition" BO_ 1251 0;
BA_ "GenMsgSendType" BO_ 1251 0;
BA_ "GenMsgILSupport" BO_ 1251 1;
BA_ "GenMsgCycleTime" BO_ 1020 50;
BA_ "GenMsgNrOfRepetition" BO_ 1020 0;
BA_ "GenMsgSendType" BO_ 1020 0;
BA_ "GenMsgILSupport" BO_ 1020 1;
BA_ "GenMsgCycleTime" BO_ 1245 100;
BA_ "GenMsgNrOfRepetition" BO_ 1245 0;
BA_ "GenMsgSendType" BO_ 1245 0;
BA_ "GenMsgILSupport" BO_ 1245 1;
BA_ "GenMsgCycleTime" BO_ 775 50;
BA_ "GenMsgNrOfRepetition" BO_ 775 0;
BA_ "GenMsgSendType" BO_ 775 0;
BA_ "GenMsgILSupport" BO_ 775 1;
BA_ "GenMsgCycleTime" BO_ 1270 100;
BA_ "GenMsgNrOfRepetition" BO_ 1270 0;
BA_ "GenMsgSendType" BO_ 1270 0;
BA_ "GenMsgILSupport" BO_ 1270 1;
BA_ "GenMsgCycleTime" BO_ 896 100;
BA_ "GenMsgNrOfRepetition" BO_ 896 0;
BA_ "GenMsgSendType" BO_ 896 0;
BA_ "GenMsgILSupport" BO_ 896 1;
BA_ "GenMsgCycleTime" BO_ 1240 100;
BA_ "GenMsgNrOfRepetition" BO_ 1240 0;
BA_ "GenMsgSendType" BO_ 1240 0;
BA_ "GenMsgILSupport" BO_ 1240 1;
BA_ "GenMsgCycleTime" BO_ 1057 100;
BA_ "GenMsgNrOfRepetition" BO_ 1057 0;
BA_ "GenMsgSendType" BO_ 1057 0;
BA_ "GenMsgILSupport" BO_ 1057 1;
BA_ "GenMsgCycleTime" BO_ 640 100;
BA_ "GenMsgNrOfRepetition" BO_ 640 0;
BA_ "GenMsgSendType" BO_ 640 0;
BA_ "GenMsgILSupport" BO_ 640 1;
BA_ "GenMsgCycleTime" BO_ 1291 500;
BA_ "GenMsgNrOfRepetition" BO_ 1291 0;
BA_ "GenMsgSendType" BO_ 1291 0;
BA_ "GenMsgILSupport" BO_ 1291 1;
BA_ "GenMsgCycleTime" BO_ 1277 100;
BA_ "GenMsgDelayTime" BO_ 1277 5;
BA_ "GenMsgNrOfRepetition" BO_ 1277 0;
BA_ "GenMsgSendType" BO_ 1277 0;
BA_ "GenMsgILSupport" BO_ 1277 1;
BA_ "GenMsgCycleTime" BO_ 1171 100;
BA_ "GenMsgNrOfRepetition" BO_ 1171 0;
BA_ "GenMsgSendType" BO_ 1171 0;
BA_ "GenMsgILSupport" BO_ 1171 1;
BA_ "GenMsgCycleTime" BO_ 1334 500;
BA_ "GenMsgNrOfRepetition" BO_ 1334 0;
BA_ "GenMsgSendType" BO_ 1334 0;
BA_ "GenMsgILSupport" BO_ 1334 1;
BA_ "GenMsgCycleTime" BO_ 1333 100;
BA_ "GenMsgNrOfRepetition" BO_ 1333 0;
BA_ "GenMsgSendType" BO_ 1333 0;
BA_ "GenMsgILSupport" BO_ 1333 1;
BA_ "GenMsgCycleTime" BO_ 1104 100;
BA_ "GenMsgNrOfRepetition" BO_ 1104 0;
BA_ "GenMsgSendType" BO_ 1104 0;
BA_ "GenMsgILSupport" BO_ 1104 1;
BA_ "GenMsgCycleTime" BO_ 1183 100;
BA_ "GenMsgNrOfRepetition" BO_ 1183 0;
BA_ "GenMsgSendType" BO_ 1183 0;
BA_ "GenMsgILSupport" BO_ 1183 1;
BA_ "GenMsgCycleTime" BO_ 1103 100;
BA_ "GenMsgNrOfRepetition" BO_ 1103 0;
BA_ "GenMsgSendType" BO_ 1103 0;
BA_ "GenMsgILSupport" BO_ 1103 1;
BA_ "GenMsgCycleTime" BO_ 1083 100;
BA_ "GenMsgNrOfRepetition" BO_ 1083 0;
BA_ "GenMsgSendType" BO_ 1083 0;
BA_ "GenMsgILSupport" BO_ 1083 1;
BA_ "GenMsgCycleTime" BO_ 1379 1000;
BA_ "GenMsgNrOfRepetition" BO_ 1379 0;
BA_ "GenMsgSendType" BO_ 1379 0;
BA_ "GenMsgILSupport" BO_ 1379 1;
BA_ "GenMsgCycleTime" BO_ 1228 100;
BA_ "GenMsgNrOfRepetition" BO_ 1228 0;
BA_ "GenMsgSendType" BO_ 1228 0;
BA_ "GenMsgILSupport" BO_ 1228 1;
BA_ "GenMsgCycleTime" BO_ 1178 100;
BA_ "GenMsgNrOfRepetition" BO_ 1178 0;
BA_ "GenMsgSendType" BO_ 1178 0;
BA_ "GenMsgILSupport" BO_ 1178 1;
BA_ "GenMsgCycleTime" BO_ 1007 100;
BA_ "GenMsgNrOfRepetition" BO_ 1007 0;
BA_ "GenMsgSendType" BO_ 1007 0;
BA_ "GenMsgILSupport" BO_ 1007 1;
BA_ "GenMsgCycleTime" BO_ 1287 100;
BA_ "GenMsgNrOfRepetition" BO_ 1287 0;
BA_ "GenMsgSendType" BO_ 1287 0;
BA_ "GenMsgILSupport" BO_ 1287 1;
BA_ "GenMsgCycleTime" BO_ 939 100;
BA_ "GenMsgNrOfRepetition" BO_ 939 0;
BA_ "GenMsgSendType" BO_ 939 0;
BA_ "GenMsgILSupport" BO_ 939 1;
BA_ "GenMsgCycleTime" BO_ 936 100;
BA_ "GenMsgNrOfRepetition" BO_ 936 0;
BA_ "GenMsgSendType" BO_ 936 0;
BA_ "GenMsgILSupport" BO_ 936 1;
BA_ "GenMsgCycleTime" BO_ 934 100;
BA_ "GenMsgNrOfRepetition" BO_ 934 0;
BA_ "GenMsgSendType" BO_ 934 0;
BA_ "GenMsgILSupport" BO_ 934 1;
BA_ "GenSigSendType" SG_ 3221225472 Reserved_4 2;
BA_ "GenSigSendType" SG_ 3221225472 AdasSignType_reserve 0;
BA_ "GenSigSendType" SG_ 1441 IHU_40_WSOSSwtSet 2;
BA_ "GenSigSendType" SG_ 1441 IHU_40_IDSSwtSet 2;
BA_ "GenSigSendType" SG_ 636 EMS_EngineSpeed_Actual 0;
BA_ "GenSigSendType" SG_ 2015 DMC_REQ1_Broadcast 1;
BA_ "GenSigSendType" SG_ 1259 VCU_PwrPersent 0;
BA_ "GenSigSendType" SG_ 1259 VCU_CampMod 0;
BA_ "GenSigSendType" SG_ 1259 VCU_5_EtmEgySaveMod 0;
BA_ "GenSigSendType" SG_ 1259 VCU_5_EEMReq 0;
BA_ "GenSigSendType" SG_ 1259 VCU_HundECAver 0;
BA_ "GenSigSendType" SG_ 1259 VCU_InstantEnergyConsump 0;
BA_ "GenSigSendType" SG_ 1259 VCU_RangeAval_2 0;
BA_ "GenSigSendType" SG_ 1259 VCU_RangeAval_1 0;
BA_ "GenSigStartValue" SG_ 1259 VCU_Pwr 500;
BA_ "GenSigSendType" SG_ 1259 VCU_Pwr 0;
BA_ "GenSigSendType" SG_ 1257 VCU_LimitSpeed 0;
BA_ "GenSigSendType" SG_ 1257 VCU_LimitSpeedSts 0;
BA_ "GenSigSendType" SG_ 1257 VCU_BrakePedalSts 0;
BA_ "GenSigSendType" SG_ 1257 VCU_BrakePedalStsValidData 0;
BA_ "GenSigSendType" SG_ 1257 VCU_4_Resd1 0;
BA_ "GenSigSendType" SG_ 1257 VCU_4_RollgCntr1 0;
BA_ "GenSigSendType" SG_ 1257 VCU_4_CRC1 0;
BA_ "GenSigSendType" SG_ 1250 BMS_34_ValidData 0;
BA_ "GenSigStartValue" SG_ 1250 BMS_LeftDCChargeTime 1022;
BA_ "GenSigSendType" SG_ 1250 BMS_LeftDCChargeTime 0;
BA_ "GenSigSendType" SG_ 1250 EVCC_2_ValidData 0;
BA_ "GenSigSendType" SG_ 1250 EVCC_ElectronicLockSts 0;
BA_ "GenSigSendType" SG_ 928 YAS_2_Checksum 0;
BA_ "GenSigSendType" SG_ 928 LongitudinalAcceleration 0;
BA_ "GenSigStartValue" SG_ 928 LongitudinalAccelerationSigValid 3;
BA_ "GenSigSendType" SG_ 928 LongitudinalAccelerationSigValid 0;
BA_ "GenSigSendType" SG_ 928 YAS_2_MessageCounter 0;
BA_ "GenSigSendType" SG_ 926 YAS_1_Checksum 0;
BA_ "GenSigSendType" SG_ 926 YawRate 0;
BA_ "GenSigStartValue" SG_ 926 YawrateSigValidData 3;
BA_ "GenSigSendType" SG_ 926 YawrateSigValidData 0;
BA_ "GenSigSendType" SG_ 926 YAS_1_MessageCounter 0;
BA_ "GenSigSendType" SG_ 1261 VCU_TowMode 0;
BA_ "GenSigSendType" SG_ 1261 VCU_TowRmd 0;
BA_ "GenSigSendType" SG_ 1261 VCU_EnergyFlowDis 0;
BA_ "GenSigSendType" SG_ 1261 V2L_FunctionSts 0;
BA_ "GenSigSendType" SG_ 1261 VCU_InvldCdnToDrvr 0;
BA_ "GenSigSendType" SG_ 1261 V2L_DischargeStopSOC 0;
BA_ "GenSigSendType" SG_ 1261 VCU_EgyRegenLevel 0;
BA_ "GenSigSendType" SG_ 1261 VCU_PowerLimit 0;
BA_ "GenSigSendType" SG_ 1261 VCU_LowSOCCLMLimitSts 0;
BA_ "GenSigSendType" SG_ 1261 VCU_VehicleSystemFailure 0;
BA_ "GenSigSendType" SG_ 1261 VCU_PTReady 0;
BA_ "GenSigSendType" SG_ 1261 VCU_HVReady 0;
BA_ "GenSigSendType" SG_ 1261 VCU_PRNDGearAct 0;
BA_ "GenSigSendType" SG_ 769 TCU_G_CluSelfLrng 0;
BA_ "GenSigSendType" SG_ 769 STAT_LeverModeDisp 0;
BA_ "GenSigSendType" SG_ 769 TCU_SpeParkSts 0;
BA_ "GenSigSendType" SG_ 769 GBPositoionDisplay 0;
BA_ "GenSigSendType" SG_ 769 GBFaultstatus 0;
BA_ "GenSigSendType" SG_ 769 TCU_G_GBWarmUpReq 0;
BA_ "GenSigSendType" SG_ 769 ClutchTemperature 0;
BA_ "GenSigSendType" SG_ 1206 SHU2R_RSeatVentnSts 0;
BA_ "GenSigSendType" SG_ 1206 SHU2R_RSeatHeatSts 0;
BA_ "GenSigSendType" SG_ 1202 SHU2M_MSeatVentnSts 0;
BA_ "GenSigSendType" SG_ 1202 SHU2M_MSeatHeatSts 0;
BA_ "GenSigSendType" SG_ 1194 SHU2L_LSeatVentnSts 0;
BA_ "GenSigSendType" SG_ 1194 SHU2L_LSeatHeatSts 0;
BA_ "GenSigSendType" SG_ 1190 SHU1R_RSeatAutVentnSts 0;
BA_ "GenSigSendType" SG_ 1190 SHU1R_RSeatAutHeatSts 0;
BA_ "GenSigSendType" SG_ 1190 SHU1R_RSeatVentnSts 0;
BA_ "GenSigSendType" SG_ 1190 SHU1R_RSeatHeatSts 0;
BA_ "GenSigSendType" SG_ 1186 SHU1L_LSeatAutVentnSts 0;
BA_ "GenSigSendType" SG_ 1186 SHU1L_LSeatAutHeatSts 0;
BA_ "GenSigSendType" SG_ 1186 SHU1L_LSeatVentnSts 0;
BA_ "GenSigSendType" SG_ 1186 SHU1L_LSeatHeatSts 0;
BA_ "GenSigSendType" SG_ 1129 SCUP_2_PsngrSeatMemSts 2;
BA_ "GenSigSendType" SG_ 1129 SCUP_2_PsngrSeatMemReq 2;
BA_ "GenSigSendType" SG_ 1058 SCUP_1_PsngrSeatFlatSts 0;
BA_ "GenSigSendType" SG_ 1058 SCUP_1_PsngrSeatFlatWarn 0;
BA_ "GenSigSendType" SG_ 1058 SCUP_1_PsngrSeatBackAgPosnTar 0;
BA_ "GenSigSendType" SG_ 1058 SCUP_1_PsngrSeatLegSprtCurr 0;
BA_ "GenSigSendType" SG_ 1058 SCUP_1_PsngrSeatLegSprtPosnTar 0;
BA_ "GenSigSendType" SG_ 1058 SCUP_1_PsngrSeatLvlPosnStsTar 0;
BA_ "GenSigSendType" SG_ 1058 SCUP_1_PsngrSeatHeiPosnStsTar 0;
BA_ "GenSigSendType" SG_ 1170 SCU_2_CRC 0;
BA_ "GenSigSendType" SG_ 1170 SCU_2_MessageCounter 0;
BA_ "GenSigSendType" SG_ 1170 SCU_2_SeatLegSpprtPosnStsTar 0;
BA_ "GenSigSendType" SG_ 1170 SCU_2_SeatLvlPosnStsTar 0;
BA_ "GenSigSendType" SG_ 1170 SCU_2_SeatHdrestHeiAdjmt 0;
BA_ "GenSigSendType" SG_ 1170 SCU_2_BackrAgPosnStsTar 0;
BA_ "GenSigSendType" SG_ 1170 SCU_2_SeatCushPosnSts 0;
BA_ "GenSigSendType" SG_ 1170 SCU_2_SeatHeiPosnStsTar 0;
BA_ "GenSigSendType" SG_ 924 SAM_1_GCRCCheck 0;
BA_ "GenSigSendType" SG_ 924 SAM_1_G_MessageCounter 0;
BA_ "GenSigStartValue" SG_ 924 SteeringAngleSpeedValidData 1;
BA_ "GenSigSendType" SG_ 924 SteeringAngleSpeedValidData 0;
BA_ "GenSigStartValue" SG_ 924 SteeringAngleValidData 1;
BA_ "GenSigSendType" SG_ 924 SteeringAngleValidData 0;
BA_ "GenSigSendType" SG_ 924 SASCalibrated 0;
BA_ "GenSigSendType" SG_ 924 AngleFailure 0;
BA_ "GenSigStartValue" SG_ 924 SteeringAngleSpeed 255;
BA_ "GenSigSendType" SG_ 924 SteeringAngleSpeed 0;
BA_ "GenSigStartValue" SG_ 924 SteeringAngle 65535;
BA_ "GenSigSendType" SG_ 924 SteeringAngle 0;
BA_ "GenSigSendType" SG_ 1203 RRCR_1_CRC 0;
BA_ "GenSigSendType" SG_ 1203 RRCR_1_MsgCntr 0;
BA_ "GenSigSendType" SG_ 1203 BSD_text 0;
BA_ "GenSigSendType" SG_ 1203 RCTA_WarningRH 0;
BA_ "GenSigSendType" SG_ 1203 TimeOut_BSDR 0;
BA_ "GenSigSendType" SG_ 1203 RRCR_1_ObjTyp 0;
BA_ "GenSigSendType" SG_ 1203 RRCR_1_BlkSts 0;
BA_ "GenSigSendType" SG_ 1203 RRCR_1_DOWWarn 0;
BA_ "GenSigSendType" SG_ 1203 RRCR_1_RCTAWarn 0;
BA_ "GenSigSendType" SG_ 1203 RRCR_1_BSDWarn 0;
BA_ "GenSigSendType" SG_ 1203 RRCR_1_SysSt 0;
BA_ "GenSigSendType" SG_ 1075 RLCR_2_RCTBONOFFSts 0;
BA_ "GenSigSendType" SG_ 1075 RLCR_2_RAEBONOFFSts 0;
BA_ "GenSigSendType" SG_ 1201 RLCR_1_CRC 0;
BA_ "GenSigSendType" SG_ 1201 RLCR_1_MsgCntr 0;
BA_ "GenSigSendType" SG_ 1201 STAT_RCTBEnable 0;
BA_ "GenSigStartValue" SG_ 1201 DOW_Status 1;
BA_ "GenSigSendType" SG_ 1201 DOW_Status 0;
BA_ "GenSigStartValue" SG_ 1201 RCW_Status 1;
BA_ "GenSigSendType" SG_ 1201 RCW_Status 0;
BA_ "GenSigSendType" SG_ 1201 STAT_DOWWarningMode 0;
BA_ "GenSigSendType" SG_ 1201 STAT_CVWWarningMode 0;
BA_ "GenSigSendType" SG_ 1201 RCTA_WarningLH 0;
BA_ "GenSigSendType" SG_ 1201 CVW_Warning 0;
BA_ "GenSigStartValue" SG_ 1201 CVW_Status 1;
BA_ "GenSigSendType" SG_ 1201 CVW_Status 0;
BA_ "GenSigStartValue" SG_ 1201 BSD_Status 1;
BA_ "GenSigSendType" SG_ 1201 BSD_Status 0;
BA_ "GenSigStartValue" SG_ 1201 RCTA_Status 1;
BA_ "GenSigSendType" SG_ 1201 RCTA_Status 0;
BA_ "GenSigSendType" SG_ 1201 STAT_RCWWarningMode 0;
BA_ "GenSigSendType" SG_ 1201 STAT_BSDWarningMode 0;
BA_ "GenSigSendType" SG_ 1201 RLCR_1_ObjTyp 0;
BA_ "GenSigSendType" SG_ 1201 RLCR_1_RCWWarn 0;
BA_ "GenSigSendType" SG_ 1201 RLCR_1_DOWWarn 0;
BA_ "GenSigSendType" SG_ 1201 RLCR_1_RCWONOFFSts 0;
BA_ "GenSigSendType" SG_ 1201 RLCR_1_DOWONOFFSts 0;
BA_ "GenSigSendType" SG_ 1201 RLCR_1_BSDLCARCTAONOFFSts 0;
BA_ "GenSigSendType" SG_ 1201 RLCR_1_RCTAWarn 0;
BA_ "GenSigSendType" SG_ 1201 RLCR_1_BlkSts 0;
BA_ "GenSigSendType" SG_ 1201 RLCR_1_RAEBWarn 0;
BA_ "GenSigSendType" SG_ 1201 RLCR_1_RCTBWarn 0;
BA_ "GenSigSendType" SG_ 1201 RLCR_1_BSDWarn 0;
BA_ "GenSigSendType" SG_ 1201 RLCR_1_SysSt 0;
BA_ "GenSigSendType" SG_ 1032 RCCP_1_InhbSts 0;
BA_ "GenSigStartValue" SG_ 1208 PPMISt 1;
BA_ "GenSigSendType" SG_ 1208 PPMISt 0;
BA_ "GenSigSendType" SG_ 1208 PPMICounter 0;
BA_ "GenSigStartValue" SG_ 1208 PPMI_1_BSRBPASts 1;
BA_ "GenSigSendType" SG_ 1208 PPMI_1_BSRBPASts 0;
BA_ "GenSigStartValue" SG_ 1208 PPMI_1_HWSts 1;
BA_ "GenSigSendType" SG_ 1208 PPMI_1_HWSts 0;
BA_ "GenSigSendType" SG_ 1339 PDCDistanceFRM 0;
BA_ "GenSigSendType" SG_ 1339 PDCDistanceFR 0;
BA_ "GenSigSendType" SG_ 1339 PDCDistanceFLM 0;
BA_ "GenSigSendType" SG_ 1339 PDCDistanceFL 0;
BA_ "GenSigSendType" SG_ 1339 PDCDistanceRRM 0;
BA_ "GenSigSendType" SG_ 1339 PDCDistanceRR 0;
BA_ "GenSigSendType" SG_ 1339 PDCDistanceRLM 0;
BA_ "GenSigSendType" SG_ 1339 PDCDistanceRL 0;
BA_ "GenSigSendType" SG_ 1042 PEPS_BLTKey_PESts 0;
BA_ "GenSigSendType" SG_ 1042 WelcomLightPollingSts 0;
BA_ "GenSigSendType" SG_ 1042 PEPS_IntelligentOpenSts 0;
BA_ "GenSigSendType" SG_ 1042 PEPSPollingSts 0;
BA_ "GenSigSendType" SG_ 998 RemoteStartSts 0;
BA_ "GenSigSendType" SG_ 998 Start_StopRequest 0;
BA_ "GenSigStartValue" SG_ 998 IDInformation 1;
BA_ "GenSigSendType" SG_ 998 IDInformation 0;
BA_ "GenSigStartValue" SG_ 998 PEPS_1_IDInformation_2 1;
BA_ "GenSigSendType" SG_ 998 PEPS_1_IDInformation_2 0;
BA_ "GenSigSendType" SG_ 1125 OBC_ChgSts_PHEV 0;
BA_ "GenSigSendType" SG_ 1125 OBC_ChgSts 0;
BA_ "GenSigSendType" SG_ 1125 OBC_ActDisOutPower 0;
BA_ "GenSigSendType" SG_ 1125 OBC_ElectronicLockSts 0;
BA_ "GenSigSendType" SG_ 1125 OBC_3_Dchasts 0;
BA_ "GenSigSendType" SG_ 1125 OBC_CC_ConnectSts 0;
BA_ "GenSigSendType" SG_ 1124 NFC_1_DispCardPosn 0;
BA_ "GenSigSendType" SG_ 1124 NFC_1_IDList 0;
BA_ "GenSigSendType" SG_ 1124 NFC_1_ID 0;
BA_ "GenSigStartValue" SG_ 850 HCU_13_CurrentTripEnergyCns 250;
BA_ "GenSigSendType" SG_ 850 HCU_13_CurrentTripEnergyCns 0;
BA_ "GenSigStartValue" SG_ 850 HCU_13_CurrentTripElecCns 1000;
BA_ "GenSigSendType" SG_ 850 HCU_13_CurrentTripElecCns 0;
BA_ "GenSigSendType" SG_ 850 HCU_13_CurrentTripFuCns 0;
BA_ "GenSigSendType" SG_ 850 HCU_13_EngSelfMaiTin 0;
BA_ "GenSigSendType" SG_ 1195 HCU_6_G_PwrdwnDisReq 2;
BA_ "GenSigSendType" SG_ 1195 HCU_6_G_VehStrtWarn 0;
BA_ "GenSigStartValue" SG_ 1195 HCU_6_G_ElecPwrVal 1000;
BA_ "GenSigSendType" SG_ 1195 HCU_6_G_ElecPwrVal 0;
BA_ "GenSigSendType" SG_ 1195 HCU_6_G_DynRngAval 0;
BA_ "GenSigSendType" SG_ 1195 HCU_6_G_SumFuel 0;
BA_ "GenSigSendType" SG_ 1195 HCU_6_G_SumPlgChrgEgy 0;
BA_ "GenSigSendType" SG_ 1159 HCU_SetSOCFedstep1 0;
BA_ "GenSigStartValue" SG_ 1159 HCU_PrecRRTorque 100;
BA_ "GenSigSendType" SG_ 1159 HCU_PrecRRTorque 0;
BA_ "GenSigStartValue" SG_ 1159 HCU_PrecRFTorque 100;
BA_ "GenSigSendType" SG_ 1159 HCU_PrecRFTorque 0;
BA_ "GenSigStartValue" SG_ 1159 HCU_PrecLRTorque 100;
BA_ "GenSigSendType" SG_ 1159 HCU_PrecLRTorque 0;
BA_ "GenSigStartValue" SG_ 1159 HCU_PrecLFTorque 100;
BA_ "GenSigSendType" SG_ 1159 HCU_PrecLFTorque 0;
BA_ "GenSigSendType" SG_ 1142 HCU_4_G_Nwarning 0;
BA_ "GenSigSendType" SG_ 1142 HCU_4_G_EngRunFuCns 0;
BA_ "GenSigStartValue" SG_ 1142 HCU_4_G_SumEgyCns 250;
BA_ "GenSigSendType" SG_ 1142 HCU_4_G_SumEgyCns 0;
BA_ "GenSigStartValue" SG_ 1142 HCU_4_G_AvgEnergyCns 250;
BA_ "GenSigSendType" SG_ 1142 HCU_4_G_AvgEnergyCns 0;
BA_ "GenSigStartValue" SG_ 1142 HCU_4_G_AvgElecCns 1000;
BA_ "GenSigSendType" SG_ 1142 HCU_4_G_AvgElecCns 0;
BA_ "GenSigSendType" SG_ 1142 HCU_4_G_AvgFuCns 0;
BA_ "GenSigSendType" SG_ 1142 HCU_BrkPsd 0;
BA_ "GenSigSendType" SG_ 1142 CruiseControlStsForDisplay 0;
BA_ "GenSigSendType" SG_ 1142 HCU_4_G_ForcedPrkgChrg 0;
BA_ "GenSigSendType" SG_ 1142 HCU_4_G_EDrvOnly 0;
BA_ "GenSigSendType" SG_ 1142 FuelTankLidSts 0;
BA_ "GenSigSendType" SG_ 1046 HCU_EgyReGenIndcrB 0;
BA_ "GenSigSendType" SG_ 1046 HCU_HvSysFltStopReq 0;
BA_ "GenSigSendType" SG_ 1046 HCU_PowerLimit 0;
BA_ "GenSigSendType" SG_ 1046 HCU_HundECHis 0;
BA_ "GenSigSendType" SG_ 1046 HCU_HundECAver 0;
BA_ "GenSigStartValue" SG_ 1046 HCU_3_G_SumElecCns 1000;
BA_ "GenSigSendType" SG_ 1046 HCU_3_G_SumElecCns 0;
BA_ "GenSigSendType" SG_ 1046 HCU_OTAHvReqSts 0;
BA_ "GenSigSendType" SG_ 1046 HCU_OTAModSts 0;
BA_ "GenSigSendType" SG_ 1046 HCU_ShowRoomRunngreason 0;
BA_ "GenSigSendType" SG_ 1046 HCU_3_G_SumFuCns 0;
BA_ "GenSigSendType" SG_ 1046 HCU_ShowRoomRunngSts 0;
BA_ "GenSigSendType" SG_ 1044 HCU_2_G_DchaFail 0;
BA_ "GenSigSendType" SG_ 1044 HCU_2_G_ChrgnFctMemSt 0;
BA_ "GenSigSendType" SG_ 1044 HCU_2_G_LowBatteryLowFuelInfo 0;
BA_ "GenSigSendType" SG_ 1044 HCU_2_G_LowBatteryInfo 0;
BA_ "GenSigSendType" SG_ 1044 HCU_2_G_HighTempLimit 0;
BA_ "GenSigSendType" SG_ 1044 HCU_2_G_DchaFault 0;
BA_ "GenSigSendType" SG_ 1044 HCU_GearReturnWarn 0;
BA_ "GenSigSendType" SG_ 1044 HCU_ChargeFault 0;
BA_ "GenSigSendType" SG_ 1044 PRNDGearAct 0;
BA_ "GenSigSendType" SG_ 1044 HCU_SetSOCFed 0;
BA_ "GenSigSendType" SG_ 1044 HCU_SocManageFed 0;
BA_ "GenSigSendType" SG_ 1044 HCU_RegenerateLevel 0;
BA_ "GenSigSendType" SG_ 1044 HCU_RangeAval 0;
BA_ "GenSigSendType" SG_ 1044 HCU_EnergyFlow 0;
BA_ "GenSigSendType" SG_ 1034 HCU_PowerModeChangeFail 0;
BA_ "GenSigStartValue" SG_ 1034 HCU_EmPwr 128;
BA_ "GenSigSendType" SG_ 1034 HCU_EmPwr 0;
BA_ "GenSigSendType" SG_ 1034 HCU_PowertrainFault 0;
BA_ "GenSigSendType" SG_ 1034 HCU_PowerModeFed 0;
BA_ "GenSigSendType" SG_ 1034 HCU_PTReady 0;
BA_ "GenSigSendType" SG_ 1034 HCU_HVReady 0;
BA_ "GenSigSendType" SG_ 1218 LHM_1_DBL_FaultSts 0;
BA_ "GenSigSendType" SG_ 1218 LHM_1_DRLFaildSts 0;
BA_ "GenSigSendType" SG_ 1218 LHM_1_LHTurnLiFaildSts 0;
BA_ "GenSigSendType" SG_ 1218 LHM_1_ParkLiFaildSts 0;
BA_ "GenSigSendType" SG_ 1218 LHM_1_LoBeamFaildSts 0;
BA_ "GenSigSendType" SG_ 1218 LHM_1_HiBeamFaildSts 0;
BA_ "GenSigSendType" SG_ 1218 LHM_1_ADBenable_Feedback 0;
BA_ "GenSigSendType" SG_ 1218 LHM_1_ADBSts 0;
BA_ "GenSigSendType" SG_ 1175 IPB_ESP_15_CRC 0;
BA_ "GenSigSendType" SG_ 1175 IPB_ESP_15_MessageCounter 0;
BA_ "GenSigSendType" SG_ 1175 Reserved_Fill7 0;
BA_ "GenSigSendType" SG_ 1175 BrakesystemFailSts 0;
BA_ "GenSigSendType" SG_ 1175 TwofeetBrakeSts 0;
BA_ "GenSigSendType" SG_ 1175 BrakeFluidSts 0;
BA_ "GenSigSendType" SG_ 1175 FWAWarningSts 0;
BA_ "GenSigSendType" SG_ 1175 Reserved_Fill2 0;
BA_ "GenSigStartValue" SG_ 1175 CST_SensitivitySts 2;
BA_ "GenSigSendType" SG_ 1175 CST_SensitivitySts 0;
BA_ "GenSigSendType" SG_ 1175 BrakepedalFeelSts 0;
BA_ "GenSigStartValue" SG_ 1175 CST_Status 1;
BA_ "GenSigSendType" SG_ 1175 CST_Status 0;
BA_ "GenSigSendType" SG_ 1175 Reserved_Fill6 0;
BA_ "GenSigSendType" SG_ 1175 Reserved_Fill5 0;
BA_ "GenSigSendType" SG_ 1175 Reserved_Fill4 0;
BA_ "GenSigSendType" SG_ 1175 Reserved_Fill3 0;
BA_ "GenSigSendType" SG_ 1175 IPB_AssociWithDriverModeSts 0;
BA_ "GenSigSendType" SG_ 1175 Reserved_Fill1 0;
BA_ "GenSigSendType" SG_ 1149 IMMO_Teach 2;
BA_ "GenSigSendType" SG_ 1110 IMMO_Chall 1;
BA_ "GenSigSendType" SG_ 906 IDCU_12_RmninfoTrig 0;
BA_ "GenSigSendType" SG_ 906 IDCU_12FCTAWarnRi 0;
BA_ "GenSigSendType" SG_ 906 IDCU_12FCTAWarnLe 0;
BA_ "GenSigSendType" SG_ 906 IDCU_12CPMod 0;
BA_ "GenSigSendType" SG_ 906 IDCU_12Rmninfo 0;
BA_ "GenSigSendType" SG_ 1248 IDCU_11_ALCDrvStysts 0;
BA_ "GenSigSendType" SG_ 1248 IDCU_11_ALCDrvrCfmONOFFsts 0;
BA_ "GenSigSendType" SG_ 1248 IDCU_11_CPONOFFsts 0;
BA_ "GenSigSendType" SG_ 1248 IDCU_11_NOCONOFFsts 0;
BA_ "GenSigSendType" SG_ 1248 IDCU_11_HPAONOFFsts 0;
BA_ "GenSigSendType" SG_ 1248 IDCU_11_ParkingchimeVoice 0;
BA_ "GenSigSendType" SG_ 1248 IDCU_11_FCTBONOFFsts 0;
BA_ "GenSigSendType" SG_ 1248 IDCU_11_SpeedLmtNmberE 0;
BA_ "GenSigSendType" SG_ 1248 IDCU_11_SpeedLmtNmberAb 0;
BA_ "GenSigSendType" SG_ 1248 IDCU_11_DrvAssiStylests 0;
BA_ "GenSigSendType" SG_ 1248 IDCU_11_DCLCONOFFsts 0;
BA_ "GenSigSendType" SG_ 903 FCM_FRM_6_SCF_Indicator 0;
BA_ "GenSigSendType" SG_ 903 FCM_FRM_6_Textinfo_Info_2 0;
BA_ "GenSigSendType" SG_ 903 FCM_FRM_6_VSetDis 0;
BA_ "GenSigStartValue" SG_ 903 FCM_FRM_6_AEBMode 1;
BA_ "GenSigSendType" SG_ 903 FCM_FRM_6_AEBMode 0;
BA_ "GenSigStartValue" SG_ 903 FCM_FRM_6_FCWMode 1;
BA_ "GenSigSendType" SG_ 903 FCM_FRM_6_FCWMode 0;
BA_ "GenSigSendType" SG_ 903 FCM_FRM_6_HMI_Indicator 0;
BA_ "GenSigSendType" SG_ 903 FCM_FRM_6_TakeOverReq 0;
BA_ "GenSigSendType" SG_ 903 FCM_FRM_6_FCW_preWarning 0;
BA_ "GenSigSendType" SG_ 903 FCM_FRM_6_DistanceWarning 0;
BA_ "GenSigSendType" SG_ 903 FCM_FRM_6_TimeGapSetICM 0;
BA_ "GenSigSendType" SG_ 903 FCM_FRM_6_DrvrCfmSCFDispFb 0;
BA_ "GenSigSendType" SG_ 903 FCM_FRM_6_SCF_SpdLimUnit 0;
BA_ "GenSigSendType" SG_ 903 FCM_FRM_6_SCF_SpdLimSts 0;
BA_ "GenSigSendType" SG_ 903 FCM_FRM_6_SCF_PopoverReq 0;
BA_ "GenSigSendType" SG_ 903 FCM_FRM_6_ACCMode 0;
BA_ "GenSigSendType" SG_ 903 FCM_FRM_6_Textinfo_Info 0;
BA_ "GenSigSendType" SG_ 903 FCM_FRM_6_TextinfoWarn 0;
BA_ "GenSigSendType" SG_ 1251 TextinfoWarn 0;
BA_ "GenSigSendType" SG_ 1251 Textinfo_Info 0;
BA_ "GenSigSendType" SG_ 1251 AdjLeftLaneMarkingCurv 0;
BA_ "GenSigSendType" SG_ 1251 AdjRightLaneMarkingCurv 0;
BA_ "GenSigSendType" SG_ 1251 LeftLaneMarkingCurv 0;
BA_ "GenSigSendType" SG_ 1251 RightLaneMarkingCurv 0;
BA_ "GenSigStartValue" SG_ 1251 FCM_FRM_5_DAIONOFFSts 1;
BA_ "GenSigSendType" SG_ 1251 FCM_FRM_5_DAIONOFFSts 0;
BA_ "GenSigStartValue" SG_ 1251 FCM_FRM_5_SCFONOFFSts 1;
BA_ "GenSigSendType" SG_ 1251 FCM_FRM_5_SCFONOFFSts 0;
BA_ "GenSigStartValue" SG_ 1251 FCM_FRM_5_FCWONOFFSts 1;
BA_ "GenSigSendType" SG_ 1251 FCM_FRM_5_FCWONOFFSts 0;
BA_ "GenSigStartValue" SG_ 1251 FCM_FRM_5_FCWSnvtySts 1;
BA_ "GenSigSendType" SG_ 1251 FCM_FRM_5_FCWSnvtySts 0;
BA_ "GenSigStartValue" SG_ 1251 FCM_FRM_5_AEBONOFFSts 1;
BA_ "GenSigSendType" SG_ 1251 FCM_FRM_5_AEBONOFFSts 0;
BA_ "GenSigStartValue" SG_ 1020 FCM_10_EgoLeftLineHeatgAg 255;
BA_ "GenSigSendType" SG_ 1020 FCM_10_EgoLeftLineHeatgAg 0;
BA_ "GenSigSendType" SG_ 1020 FCM_10_ELKIntvMod 0;
BA_ "GenSigStartValue" SG_ 1020 FCM_10_WarnModSts 3;
BA_ "GenSigSendType" SG_ 1020 FCM_10_WarnModSts 0;
BA_ "GenSigStartValue" SG_ 1020 FCM_10_SLAONOFFSts 1;
BA_ "GenSigSendType" SG_ 1020 FCM_10_SLAONOFFSts 0;
BA_ "GenSigStartValue" SG_ 1020 FCM_10_TJAICAExitTextInfoSts 1;
BA_ "GenSigSendType" SG_ 1020 FCM_10_TJAICAExitTextInfoSts 0;
BA_ "GenSigSendType" SG_ 1020 FCM_10_LDPTJAELKTakeoverReq 0;
BA_ "GenSigSendType" SG_ 1020 FCM_10_TSINoParkWarn 0;
BA_ "GenSigSendType" SG_ 1020 FCM_10_ELKSysSts 0;
BA_ "GenSigSendType" SG_ 1020 FCM_10_TJAICAEnaRcmend 0;
BA_ "GenSigSendType" SG_ 1020 FCM_10_TJAICATextinfo 0;
BA_ "GenSigSendType" SG_ 1020 FCM_10_LDWSysSts 0;
BA_ "GenSigSendType" SG_ 1020 FCM_10_LDPSysSts 0;
BA_ "GenSigSendType" SG_ 1020 FCM_10_TLITrfcLi 0;
BA_ "GenSigSendType" SG_ 1020 FCM_10_TSISgnLongStayDisp 0;
BA_ "GenSigSendType" SG_ 1020 FCM_10_TLISysSts 0;
BA_ "GenSigSendType" SG_ 1020 FCM_10_TSISysSts 0;
BA_ "GenSigSendType" SG_ 1020 FCM_10_TSISgnForb 0;
BA_ "GenSigSendType" SG_ 1020 FCM_10_TSISgnGiWay 0;
BA_ "GenSigSendType" SG_ 1245 FCM_5_SLAmodeSWSet 0;
BA_ "GenSigSendType" SG_ 1245 FCM_5_SpeedLmtNmberE 0;
BA_ "GenSigSendType" SG_ 1245 FCM_5_SpeedLmtNmberAb 0;
BA_ "GenSigStartValue" SG_ 1245 SLASpdlimitWarningAudSWSts 1;
BA_ "GenSigSendType" SG_ 1245 SLASpdlimitWarningAudSWSts 0;
BA_ "GenSigStartValue" SG_ 1245 SLASpdLimChgAudSwSts 1;
BA_ "GenSigSendType" SG_ 1245 SLASpdLimChgAudSwSts 0;
BA_ "GenSigStartValue" SG_ 1245 SLWFONOFFSts 1;
BA_ "GenSigSendType" SG_ 1245 SLWFONOFFSts 0;
BA_ "GenSigStartValue" SG_ 1245 FCM_5_ELKONOFFSts 1;
BA_ "GenSigSendType" SG_ 1245 FCM_5_ELKONOFFSts 0;
BA_ "GenSigStartValue" SG_ 1245 FCM_5_LDWLDPSnvtySts 1;
BA_ "GenSigSendType" SG_ 1245 FCM_5_LDWLDPSnvtySts 0;
BA_ "GenSigStartValue" SG_ 1245 FCM_5_LDPONOFFSts 2;
BA_ "GenSigSendType" SG_ 1245 FCM_5_LDPONOFFSts 0;
BA_ "GenSigStartValue" SG_ 1245 FCM_5_WarnModSts 3;
BA_ "GenSigSendType" SG_ 1245 FCM_5_WarnModSts 0;
BA_ "GenSigStartValue" SG_ 1245 FCM_5_LDWONOFFSts 1;
BA_ "GenSigSendType" SG_ 1245 FCM_5_LDWONOFFSts 0;
BA_ "GenSigStartValue" SG_ 1245 FCM_5_TLIONOFFSts 1;
BA_ "GenSigSendType" SG_ 1245 FCM_5_TLIONOFFSts 0;
BA_ "GenSigStartValue" SG_ 1245 FCM_5_TSIONOFFSts 1;
BA_ "GenSigSendType" SG_ 1245 FCM_5_TSIONOFFSts 0;
BA_ "GenSigStartValue" SG_ 1245 FCM_5_HMAONOFFSts 1;
BA_ "GenSigSendType" SG_ 1245 FCM_5_HMAONOFFSts 0;
BA_ "GenSigStartValue" SG_ 1245 FCM_5_IESONOFFSts 1;
BA_ "GenSigSendType" SG_ 1245 FCM_5_IESONOFFSts 0;
BA_ "GenSigStartValue" SG_ 1245 FCM_5_SLAONOFFSts 1;
BA_ "GenSigSendType" SG_ 1245 FCM_5_SLAONOFFSts 0;
BA_ "GenSigStartValue" SG_ 1245 FCM_5_TJAICAExitTextInfoSts 1;
BA_ "GenSigSendType" SG_ 1245 FCM_5_TJAICAExitTextInfoSts 0;
BA_ "GenSigSendType" SG_ 775 FCM_2_TJATakeoverReq 0;
BA_ "GenSigSendType" SG_ 775 SLASpdlimitWarningAud 0;
BA_ "GenSigSendType" SG_ 775 SLASpdlimitWarningVis 0;
BA_ "GenSigSendType" SG_ 775 SLASpdlimitUnknownWarning 0;
BA_ "GenSigSendType" SG_ 775 FCM_2_SLASpdlimitUnits 0;
BA_ "GenSigSendType" SG_ 775 TJA_ICA_ON_OFF_sts 0;
BA_ "GenSigSendType" SG_ 775 TJA_ICA_mode 0;
BA_ "GenSigSendType" SG_ 775 Camera_textinfo 0;
BA_ "GenSigSendType" SG_ 775 FCM_2_SpdLimtyp 0;
BA_ "GenSigSendType" SG_ 775 SLASpdlimit 0;
BA_ "GenSigSendType" SG_ 775 FCM_2_SLAmodeSWSet 0;
BA_ "GenSigSendType" SG_ 775 SLASpdlimitWarning 0;
BA_ "GenSigSendType" SG_ 775 FCM_2_SCFSpdlimWarn 0;
BA_ "GenSigStartValue" SG_ 775 SLAState 1;
BA_ "GenSigSendType" SG_ 775 SLAState 0;
BA_ "GenSigSendType" SG_ 775 LDW_ELK_TJA_LDPRightVisuali 0;
BA_ "GenSigSendType" SG_ 775 FCM_2_ISAState 0;
BA_ "GenSigSendType" SG_ 775 LDW_ELK_TJA_LDPLeftVisuali 0;
BA_ "GenSigSendType" SG_ 775 HMA_HighbeamReq 0;
BA_ "GenSigStartValue" SG_ 775 HMA_Status 1;
BA_ "GenSigSendType" SG_ 775 HMA_Status 0;
BA_ "GenSigSendType" SG_ 1270 Yellowwarning 0;
BA_ "GenSigSendType" SG_ 1270 Redwarning 0;
BA_ "GenSigSendType" SG_ 1270 RWUActive 0;
BA_ "GenSigSendType" SG_ 1270 EPBWarningMessage 0;
BA_ "GenSigStartValue" SG_ 1270 EPBStatus 4;
BA_ "GenSigSendType" SG_ 1270 EPBStatus 0;
BA_ "GenSigSendType" SG_ 896 EPS_EOTLearning_Sts 0;
BA_ "GenSigSendType" SG_ 896 EPS_1_MessageCounter 0;
BA_ "GenSigSendType" SG_ 896 EPSSteeringAngleCalibrationSts 0;
BA_ "GenSigSendType" SG_ 896 EPSFailSts 0;
BA_ "GenSigSendType" SG_ 896 EPS_AssociWithDriverModeSts 0;
BA_ "GenSigSendType" SG_ 896 EPS_AssistanceStyle_Sts 0;
BA_ "GenSigSendType" SG_ 1240 EMS_BoostP 0;
BA_ "GenSigSendType" SG_ 1057 HCU_PTSafetyWarning 0;
BA_ "GenSigSendType" SG_ 1057 BrakePedalSts 0;
BA_ "GenSigSendType" SG_ 1057 BrakePedalStsValidData 0;
BA_ "GenSigSendType" SG_ 1057 GasPedalPositionInvalidData 0;
BA_ "GenSigSendType" SG_ 1057 GasPedalPosition 0;
BA_ "GenSigSendType" SG_ 1057 LimitSpeedSts 0;
BA_ "GenSigSendType" SG_ 1057 CruiseLimitSpeedValue 0;
BA_ "GenSigSendType" SG_ 640 OilPressureWarningLamp 0;
BA_ "GenSigSendType" SG_ 640 EMS_EngineSts_Actual 0;
BA_ "GenSigSendType" SG_ 640 GearReduceIndication 0;
BA_ "GenSigSendType" SG_ 640 GearRaiseIndication 0;
BA_ "GenSigSendType" SG_ 640 TargetGearPosition 0;
BA_ "GenSigStartValue" SG_ 640 EPCSts 1;
BA_ "GenSigSendType" SG_ 640 EPCSts 0;
BA_ "GenSigSendType" SG_ 640 EngineSpeedValidData 0;
BA_ "GenSigSendType" SG_ 640 FuelRollingCounterValidData 0;
BA_ "GenSigSendType" SG_ 640 ISS_Sts_GS 0;
BA_ "GenSigStartValue" SG_ 640 FuelRollingCounter 255;
BA_ "GenSigSendType" SG_ 640 FuelRollingCounter 0;
BA_ "GenSigStartValue" SG_ 640 EngineCoolantTemperture 91;
BA_ "GenSigSendType" SG_ 640 EngineCoolantTemperture 0;
BA_ "GenSigSendType" SG_ 640 CruiseControlStsForDisplay 0;
BA_ "GenSigSendType" SG_ 640 ECSControlSts 0;
BA_ "GenSigSendType" SG_ 640 EngineCoolantTempertureFailSts 0;
BA_ "GenSigStartValue" SG_ 640 MILSts 2;
BA_ "GenSigSendType" SG_ 640 MILSts 0;
BA_ "GenSigStartValue" SG_ 640 IEMSts 1;
BA_ "GenSigSendType" SG_ 640 IEMSts 0;
BA_ "GenSigSendType" SG_ 640 GPFWarning 0;
BA_ "GenSigSendType" SG_ 640 EngineSts 0;
BA_ "GenSigSendType" SG_ 640 SSMStatus 0;
BA_ "GenSigSendType" SG_ 640 EngineSpeed 0;
BA_ "GenSigSendType" SG_ 1291 Pos3_FragranceSts_sec 0;
BA_ "GenSigSendType" SG_ 1291 Pos2_FragranceSts_sec 0;
BA_ "GenSigSendType" SG_ 1291 Pos1_FragranceSts_sec 0;
BA_ "GenSigSendType" SG_ 1291 Pos3_FragranceTypesSts_sec 0;
BA_ "GenSigSendType" SG_ 1291 Pos2_FragranceTypesSts_sec 0;
BA_ "GenSigSendType" SG_ 1291 Pos1_FragranceTypesSts_sec 0;
BA_ "GenSigSendType" SG_ 1277 CLM_10_SteerWhlHeatgSwt 2;
BA_ "GenSigSendType" SG_ 1277 CLM_WindowCmd 2;
BA_ "GenSigSendType" SG_ 1277 AUTODefrostlevelSts 0;
BA_ "GenSigSendType" SG_ 1277 CLM_10_FRSeatVentilationCmd 2;
BA_ "GenSigSendType" SG_ 1277 CLM_10_FLSeatVentilationCmd 2;
BA_ "GenSigSendType" SG_ 1277 CLM_10_FRSeatHeatLevelCmd 2;
BA_ "GenSigSendType" SG_ 1277 CLM_10_FLSeatHeatLevelCmd 2;
BA_ "GenSigSendType" SG_ 1277 CLM_10_CLMIntlgDeodnSts 0;
BA_ "GenSigSendType" SG_ 1277 CLM_10_CLMSupHeatgSts 0;
BA_ "GenSigSendType" SG_ 1277 CLM_10_CLMSupCoolgSts 0;
BA_ "GenSigSendType" SG_ 1277 CLM_10_SeRowDispSts 0;
BA_ "GenSigSendType" SG_ 1277 CLM_10_RfgtLkDispSts 0;
BA_ "GenSigSendType" SG_ 1277 CLM_10_ReRowDispSts 0;
BA_ "GenSigSendType" SG_ 1277 CLM_10_ReRowBlowSpdLvlSts 0;
BA_ "GenSigSendType" SG_ 1277 CLM_10_ReRowWorkSts 0;
BA_ "GenSigSendType" SG_ 1277 CLM_10_RmnDispSts 0;
BA_ "GenSigStartValue" SG_ 1277 IncarTemperature_C 127;
BA_ "GenSigSendType" SG_ 1277 IncarTemperature_C 0;
BA_ "GenSigSendType" SG_ 1277 CLM_10_AQSDispSts 0;
BA_ "GenSigSendType" SG_ 1277 SelfTestResult2 1;
BA_ "GenSigSendType" SG_ 1277 IntelligentCustomSts 0;
BA_ "GenSigSendType" SG_ 1277 CLM_10_SeRowWorkSts 0;
BA_ "GenSigSendType" SG_ 1277 CLM_10_SeRowBlowSpdLvlDispSts 0;
BA_ "GenSigSendType" SG_ 1277 PtcHeatgSts 0;
BA_ "GenSigSendType" SG_ 1171 CLM_6_CbnAntiOverHeatSts 0;
BA_ "GenSigStartValue" SG_ 1171 CLM_6_warn_sts 1;
BA_ "GenSigSendType" SG_ 1171 CLM_6_warn_sts 0;
BA_ "GenSigSendType" SG_ 1171 AQSAutoRunSts 0;
BA_ "GenSigSendType" SG_ 1334 CLM_3_Exhaust_Sts 0;
BA_ "GenSigStartValue" SG_ 1334 FragranCeconsistenceLevelSts 1;
BA_ "GenSigSendType" SG_ 1334 FragranCeconsistenceLevelSts 0;
BA_ "GenSigSendType" SG_ 1334 Pos3_FragranceTypesSts 0;
BA_ "GenSigSendType" SG_ 1334 Pos2_FragranceTypesSts 0;
BA_ "GenSigSendType" SG_ 1334 PM2_5AutoRunSetSts 0;
BA_ "GenSigSendType" SG_ 1334 PM2_5_Incar_Level 0;
BA_ "GenSigSendType" SG_ 1334 PM2_5_Outcar_Level 0;
BA_ "GenSigSendType" SG_ 1334 FragranceDisplaysts 0;
BA_ "GenSigSendType" SG_ 1334 FragrancePositionSwt 0;
BA_ "GenSigSendType" SG_ 1334 ACModeCustomSts 0;
BA_ "GenSigSendType" SG_ 1334 FragranceWelcomeModeSts 0;
BA_ "GenSigStartValue" SG_ 1334 RefreshFunctionSts 1;
BA_ "GenSigSendType" SG_ 1334 RefreshFunctionSts 0;
BA_ "GenSigSendType" SG_ 1334 Pos1_FragranceTypesSts 0;
BA_ "GenSigStartValue" SG_ 1334 PM2_5AutoRunSts 1;
BA_ "GenSigSendType" SG_ 1334 PM2_5AutoRunSts 0;
BA_ "GenSigStartValue" SG_ 1334 FragranceSWSts 1;
BA_ "GenSigSendType" SG_ 1334 FragranceSWSts 0;
BA_ "GenSigSendType" SG_ 1334 AutoBltCalllowBlowSpeedSts 0;
BA_ "GenSigSendType" SG_ 1334 AutoParkInnerCirculationSts 0;
BA_ "GenSigSendType" SG_ 1334 PM2_5_IncarSts 0;
BA_ "GenSigSendType" SG_ 1334 PM2_5_ExtSts 0;
BA_ "GenSigSendType" SG_ 1334 PM2_5_ext 0;
BA_ "GenSigSendType" SG_ 1334 FragranceShortageWarning 0;
BA_ "GenSigSendType" SG_ 1334 ION_Function_Sts 0;
BA_ "GenSigSendType" SG_ 1334 PM2_5_incar 0;
BA_ "GenSigSendType" SG_ 1333 AUTODefrostDisplaySts 1;
BA_ "GenSigSendType" SG_ 1333 TempKnobRollingCounter 3;
BA_ "GenSigSendType" SG_ 1333 BlowSpeedLevelDisplaySts 3;
BA_ "GenSigSendType" SG_ 1333 AUTODefrostForceOpenSts 1;
BA_ "GenSigSendType" SG_ 1333 AQSAutoRunSetSts 0;
BA_ "GenSigSendType" SG_ 1333 AQSSts 0;
BA_ "GenSigSendType" SG_ 1333 PM2_5Displaysts 1;
BA_ "GenSigSendType" SG_ 1333 PM2_5overproofDisplaySts 1;
BA_ "GenSigSendType" SG_ 1333 FiltertchangeDisplaySts 1;
BA_ "GenSigSendType" SG_ 1333 REARInhibitSts 1;
BA_ "GenSigSendType" SG_ 1333 AUTODefrostOnSts 0;
BA_ "GenSigSendType" SG_ 1104 OBDDiagnosisReqInd 0;
BA_ "GenSigSendType" SG_ 1183 BMSH_24_SOCDisp 0;
BA_ "GenSigSendType" SG_ 1183 BMSH_InsulationSts 0;
BA_ "GenSigSendType" SG_ 1183 BMSH_BattVolt 0;
BA_ "GenSigStartValue" SG_ 1183 BMSH_BatteryCurrent 32000;
BA_ "GenSigSendType" SG_ 1183 BMSH_BatteryCurrent 0;
BA_ "GenSigSendType" SG_ 1183 BMSH_PackChargingThermalSt 0;
BA_ "GenSigSendType" SG_ 1103 BMS_8_PackDCChargingSt 0;
BA_ "GenSigSendType" SG_ 1103 BMS_8_CC2Sts 0;
BA_ "GenSigSendType" SG_ 1103 BMSH_SOH 0;
BA_ "GenSigStartValue" SG_ 1103 BMSH_LeftChargeTime 1022;
BA_ "GenSigSendType" SG_ 1103 BMSH_LeftChargeTime 0;
BA_ "GenSigSendType" SG_ 1103 BMSH_PackInstantRecoveryPower 0;
BA_ "GenSigSendType" SG_ 1083 BMSH_BattFaultLampSts 0;
BA_ "GenSigSendType" SG_ 1083 BMSH_PackThermalRunawayLight 0;
BA_ "GenSigSendType" SG_ 1083 BMSH_SOCDisp 0;
BA_ "GenSigSendType" SG_ 1379 BMSH_KeepWarmTimeSum 0;
BA_ "GenSigSendType" SG_ 1379 BMSH_KeepWarmSelfWakeupTimes 0;
BA_ "GenSigSendType" SG_ 1379 BMSH_keepWarmNextTimeRSet 0;
BA_ "GenSigSendType" SG_ 1228 BMSH_CC2_ConnectSts 0;
BA_ "GenSigSendType" SG_ 1228 BMSH_CC_ConnectDischarSts 0;
BA_ "GenSigSendType" SG_ 1228 BMSH_CC_ConnectSts 0;
BA_ "GenSigSendType" SG_ 1228 BMSH_KeepwarmSts 0;
BA_ "GenSigSendType" SG_ 1228 BMSH_KeepwarmFunctSts 0;
BA_ "GenSigSendType" SG_ 1228 BMSH_ElectronicLockSts 0;
BA_ "GenSigSendType" SG_ 1228 BMSH_PreWarmDis 0;
BA_ "GenSigSendType" SG_ 1228 Pack_ChargeStopSOC 0;
BA_ "GenSigSendType" SG_ 1228 BMSH_PackchgSTS 0;
BA_ "GenSigSendType" SG_ 1228 BMSH_28_RollgCntr1 0;
BA_ "GenSigSendType" SG_ 1228 BMSH_28_CRC1 0;
BA_ "GenSigSendType" SG_ 1178 BDM_26_RRSeatMsgStr_LvlSts 0;
BA_ "GenSigSendType" SG_ 1178 BCM_26_ExlLampDrivests 0;
BA_ "GenSigSendType" SG_ 1178 BDM_26_RRSeatMsg_ModeSts 0;
BA_ "GenSigSendType" SG_ 1178 BDM_26_RLSeatMsgStr_LvlSts 0;
BA_ "GenSigSendType" SG_ 1178 BDM_26_RLSeatMsg_ModeSts 0;
BA_ "GenSigStartValue" SG_ 1178 BDM_26_RRWinPosn 127;
BA_ "GenSigSendType" SG_ 1178 BDM_26_RRWinPosn 0;
BA_ "GenSigStartValue" SG_ 1178 BDM_26_RLWinPosn 127;
BA_ "GenSigSendType" SG_ 1178 BDM_26_RLWinPosn 0;
BA_ "GenSigStartValue" SG_ 1178 BDM_26_FRWinPosn 127;
BA_ "GenSigSendType" SG_ 1178 BDM_26_FRWinPosn 0;
BA_ "GenSigStartValue" SG_ 1178 BDM_26_FLWinPosn 127;
BA_ "GenSigSendType" SG_ 1178 BDM_26_FLWinPosn 0;
BA_ "GenSigSendType" SG_ 1007 BDM_25_AmbBrightness 0;
BA_ "GenSigSendType" SG_ 1007 BDM_25_FWBrightness 0;
BA_ "GenSigSendType" SG_ 1287 BDM_LightMainSwitchSts 0;
BA_ "GenSigSendType" SG_ 1287 BDM_RearMirrorFoldSts 0;
BA_ "GenSigSendType" SG_ 1287 DriverSeatMsgStr_LvlSts 0;
BA_ "GenSigSendType" SG_ 1287 DriverSeatMsg_ModeSts 0;
BA_ "GenSigSendType" SG_ 1287 BCM_22_WelcomelampSts 0;
BA_ "GenSigSendType" SG_ 1287 BCM_22_WiprSnvtySetFb 0;
BA_ "GenSigSendType" SG_ 1287 BCM_22_Rool_OperateSts 0;
BA_ "GenSigSendType" SG_ 1287 PassSeatMsgStr_LvlSts 0;
BA_ "GenSigSendType" SG_ 1287 PassSeatMsg_ModeSts 0;
BA_ "GenSigStartValue" SG_ 939 IBS_QuiescentCurrent 255;
BA_ "GenSigSendType" SG_ 939 IBS_QuiescentCurrent 0;
BA_ "GenSigStartValue" SG_ 936 IBS_SOF_V1 255;
BA_ "GenSigSendType" SG_ 936 IBS_SOF_V1 0;
BA_ "GenSigStartValue" SG_ 936 IBS_STAT_SOC 3;
BA_ "GenSigSendType" SG_ 936 IBS_STAT_SOC 0;
BA_ "GenSigStartValue" SG_ 936 IBS_SOH 255;
BA_ "GenSigSendType" SG_ 936 IBS_SOH 0;
BA_ "GenSigStartValue" SG_ 936 IBS_SOC 255;
BA_ "GenSigSendType" SG_ 936 IBS_SOC 0;
BA_ "GenSigStartValue" SG_ 934 IBS_CurrentRange 3;
BA_ "GenSigSendType" SG_ 934 IBS_CurrentRange 0;
BA_ "GenSigStartValue" SG_ 934 IBS_BatteryTemp 255;
BA_ "GenSigSendType" SG_ 934 IBS_BatteryTemp 0;
BA_ "GenSigSendType" SG_ 934 IBS_Current 0;
BA_ "GenSigStartValue" SG_ 934 IBS_Voltage 16383;
BA_ "GenSigSendType" SG_ 934 IBS_Voltage 0;
BA_REL_ "GenSigTimeoutTime" BU_SG_REL_ DMC SG_ 1203 RCTA_WarningRH 1000;
BA_REL_ "GenSigTimeoutTime" BU_SG_REL_ DMC SG_ 1203 TimeOut_BSDR 1000;
BA_REL_ "GenSigTimeoutTime" BU_SG_REL_ DMC SG_ 1201 STAT_RCTBEnable 1000;
BA_REL_ "GenSigTimeoutTime" BU_SG_REL_ DMC SG_ 1201 DOW_Status 1000;
BA_REL_ "GenSigTimeoutTime" BU_SG_REL_ DMC SG_ 1201 RCW_Status 1000;
BA_REL_ "GenSigTimeoutTime" BU_SG_REL_ DMC SG_ 1201 STAT_DOWWarningMode 1000;
BA_REL_ "GenSigTimeoutTime" BU_SG_REL_ DMC SG_ 1201 STAT_CVWWarningMode 1000;
BA_REL_ "GenSigTimeoutTime" BU_SG_REL_ DMC SG_ 1201 RCTA_WarningLH 1000;
BA_REL_ "GenSigTimeoutTime" BU_SG_REL_ DMC SG_ 1201 CVW_Warning 1000;
BA_REL_ "GenSigTimeoutTime" BU_SG_REL_ DMC SG_ 1201 CVW_Status 1000;
BA_REL_ "GenSigTimeoutTime" BU_SG_REL_ DMC SG_ 1201 BSD_Status 1000;
BA_REL_ "GenSigTimeoutTime" BU_SG_REL_ DMC SG_ 1201 RCTA_Status 1000;
BA_REL_ "GenSigTimeoutTime" BU_SG_REL_ DMC SG_ 1201 STAT_RCWWarningMode 1000;
BA_REL_ "GenSigTimeoutTime" BU_SG_REL_ DMC SG_ 1201 STAT_BSDWarningMode 1000;
VAL_ 1259 VCU_PwrPersent 255 "Invalid" 254 "Abnormal
(254)" 0 "Not Active(0)" ;
VAL_ 1259 VCU_CampMod 1 " ON" 0 " OFF                   " ;
VAL_ 1259 VCU_5_EtmEgySaveMod 1 " ON" 0 " OFF                   " ;
VAL_ 1259 VCU_5_EEMReq 1 " ON" 0 " OFF                   " ;
VAL_ 1257 VCU_LimitSpeedSts 7 "Reserved" 6 "Reserved" 5 " Kickdown" 4 " Cancel" 3 " Limit" 2 " Overspeed" 1 " Standby" 0 " Off" ;
VAL_ 1257 VCU_BrakePedalSts 0 " Not applied" 1 " Applied" ;
VAL_ 1257 VCU_BrakePedalStsValidData 0 " Valid" 1 " Not Valid" ;
VAL_ 1250 BMS_34_ValidData 1 " Not valid" 0 " Valid" ;
VAL_ 1250 EVCC_2_ValidData 1 " Not valid" 0 " Valid" ;
VAL_ 1250 EVCC_ElectronicLockSts 4 "Elock error" 3 "Unlock error" 2 "Lock error" 1 "Lock" 0 "Unlock" ;
VAL_ 928 LongitudinalAccelerationSigValid 3 " Initialize" 2 " Invalid" 1 " Reserved" 0 " Valid" ;
VAL_ 926 YawrateSigValidData 3 " Initialize" 2 " Invalid" 1 " Reserved" 0 " Valid" ;
VAL_ 1261 VCU_TowMode 3 "Reserved" 2 " Tow mode active" 1 " Tow mode active process" 0 " Tow mode inactive" ;
VAL_ 1261 VCU_TowRmd 7 "Reserved" 6 "Tow exit" 5 "Tow enter successful" 4 "Tow enter failed" 3 " Apply Brake" 2 " Lock P" 1 " KL15 ON" 0 "No Remind" ;
VAL_ 1261 VCU_EnergyFlowDis 7 "Reserved" 6 "Reserved" 5 "Reserved" 4 "Regenerate" 3 "Discharge +Regenerate" 2 "Charge" 1 " Discharge" 0 " None" ;
VAL_ 1261 V2L_FunctionSts 1 " ON" 0 " OFF " ;
VAL_ 1261 VCU_InvldCdnToDrvr 7 " Keep N position for 2s" 6 " Epark Can Not Release" 5 " Epark Can Not Lock" 4 " Not In PTReady" 3 " Charge Gun Connect" 2 " Brake pedal applied" 1 " Over Speed" 0 " No Command" ;
VAL_ 1261 VCU_EgyRegenLevel 3 "Reserved" 2 "High" 1 "Medium" 0 "Low" ;
VAL_ 1261 VCU_PowerLimit 1 " LmpON" 0 " LmpOFF" ;
VAL_ 1261 VCU_LowSOCCLMLimitSts 1 " LmpON" 0 " LmpOFF" ;
VAL_ 1261 VCU_VehicleSystemFailure 1 " Fail present" 0 " Fail not present" ;
VAL_ 1261 VCU_PTReady 1 " LmpON" 0 " LmpOFF" ;
VAL_ 1261 VCU_HVReady 1 " LmpON" 0 " LmpOFF" ;
VAL_ 1261 VCU_PRNDGearAct 7 " Reserved" 6 " Reserved" 5 " Reserved" 4 " D" 3 " N" 2 " R" 1 " P" 0 " Init" ;
VAL_ 769 TCU_G_CluSelfLrng 1 "ClutchSelfLearnEnb" 0 "No Request" ;
VAL_ 769 STAT_LeverModeDisp 7 " Invalid" 6 " Failure value" 5 " Display M" 4 " Display D" 3 " Display N" 2 " Display R" 1 " Display P" 0 " No Display" ;
VAL_ 769 TCU_SpeParkSts 1 " ON" 0 " OFF" ;
VAL_ 769 GBPositoionDisplay 30 "Display M9-" 29 " Display M8-" 28 "Display M8+" 27 " Display M9" 26 " Display M8" 25 " Display M7-" 24 " Display M6-" 23 "Display M5-" 22 "Display M4-" 21 " Display M3-" 20 " Display M2-" 19 " Display M7+" 18 " Display M6+" 17 " Display M5+" 16 "Display M4+" 15 " Display M3+" 14 "Display M2+" 13 "Display M1+" 12 "Low" 11 "Display M7" 10 "Display M6" 9 "Display M5" 8 "Display M4" 7 "Display M3" 6 "Display M2" 5 "Display M1" 4 " Display D" 3 "Display N" 2 " Display R" 1 " Display P" 0 "NO Display" ;
VAL_ 769 GBFaultstatus 3 "Clutch over temperature" 2 "High oil over temperature" 1 "GB failure" 0 "No failure" ;
VAL_ 769 TCU_G_GBWarmUpReq 1 " Warm Up Request" 0 " No Request" ;
VAL_ 769 ClutchTemperature 3 " Not used" 2 " Super over" 1 " Over" 0 " Normal" ;
VAL_ 1206 SHU2R_RSeatVentnSts 7 " Reserved" 6 " Reserved" 5 " Reserved" 4 " Reserved" 3 " Seat Ventilation Level3" 2 " Seat Ventilation Level2" 1 " Seat Ventilation Level1" 0 " OFF" ;
VAL_ 1206 SHU2R_RSeatHeatSts 7 " Reserved" 6 " Reserved" 5 " Reserved" 4 " Reserved" 3 " Seat heating Level3" 2 " Seat heating Level2" 1 " Seat heating Level1" 0 " OFF" ;
VAL_ 1202 SHU2M_MSeatVentnSts 7 " Reserved" 6 " Reserved" 5 " Reserved" 4 " Reserved" 3 " Seat Ventilation Level3" 2 " Seat Ventilation Level2" 1 " Seat Ventilation Level1" 0 " OFF" ;
VAL_ 1202 SHU2M_MSeatHeatSts 7 " Reserved" 6 " Reserved" 5 " Reserved" 4 " Reserved" 3 " Seat heating Level3" 2 " Seat heating Level2" 1 " Seat heating Level1" 0 " OFF" ;
VAL_ 1194 SHU2L_LSeatVentnSts 7 " Reserved" 6 " Reserved" 5 " Reserved" 4 " Reserved" 3 " Seat Ventilation Level3" 2 " Seat Ventilation Level2" 1 " Seat Ventilation Level1" 0 " OFF" ;
VAL_ 1194 SHU2L_LSeatHeatSts 7 " Reserved" 6 " Reserved" 5 " Reserved" 4 " Reserved" 3 " Seat heating Level3" 2 " Seat heating Level2" 1 " Seat heating Level1" 0 " OFF" ;
VAL_ 1190 SHU1R_RSeatAutVentnSts 3 " Reserved" 2 " Reserved" 1 " ON" 0 " OFF" ;
VAL_ 1190 SHU1R_RSeatAutHeatSts 3 " Reserved" 2 " Reserved" 1 " ON" 0 " OFF" ;
VAL_ 1190 SHU1R_RSeatVentnSts 7 " Reserved" 6 " Reserved" 5 " Reserved" 4 " Reserved" 3 " Seat Ventilation Level3" 2 " Seat Ventilation Level2" 1 " Seat Ventilation Level1" 0 " OFF" ;
VAL_ 1190 SHU1R_RSeatHeatSts 7 " Reserved" 6 " Reserved" 5 " Reserved" 4 " Reserved" 3 " Seat heating Level3" 2 " Seat heating Level2" 1 " Seat heating Level1" 0 " OFF" ;
VAL_ 1186 SHU1L_LSeatAutVentnSts 3 " Reserved" 2 " Reserved" 1 " ON" 0 " OFF" ;
VAL_ 1186 SHU1L_LSeatAutHeatSts 3 " Reserved" 2 " Reserved" 1 " ON" 0 " OFF" ;
VAL_ 1186 SHU1L_LSeatVentnSts 7 " Reserved" 6 " Reserved" 5 " Reserved" 4 " Reserved" 3 " Seat Ventilation Level3" 2 " Seat Ventilation Level2" 1 " Seat Ventilation Level1" 0 " OFF" ;
VAL_ 1186 SHU1L_LSeatHeatSts 7 " Reserved" 6 " Reserved" 5 " Reserved" 4 " Reserved" 3 " Seat heating Level3" 2 " Seat heating Level2" 1 " Seat heating Level1" 0 " OFF" ;
VAL_ 1129 SCUP_2_PsngrSeatMemSts 3 "Not Used" 2 "Failure" 1 "Success " 0 "Not Active" ;
VAL_ 1129 SCUP_2_PsngrSeatMemReq 3 "Not Used" 2 "SeatPos_Request" 1 "SeatFlat_Request " 0 "No Request" ;
VAL_ 1058 SCUP_1_PsngrSeatFlatSts 3 "Not Used" 2 "Active" 1 "Ongoing" 0 "Off" ;
VAL_ 1058 SCUP_1_PsngrSeatFlatWarn 7 "Not Used" 6 "Not Used" 5 "KeySts_Warn" 4 "PsngrSeatBeltFasten_Warn" 3 "VehicleSpeed2_Warn" 2 "VehicleSpeed1_Warn " 1 "LowBattery_ Warn " 0 "no warning" ;
VAL_ 1058 SCUP_1_PsngrSeatBackAgPosnTar 31 "Reserved" 30 "Reserved" 29 "Reserved" 28 "Reserved" 27 "Reserved" 26 "Reserved" 25 "Reserved" 24 "Reserved" 23 "Reserved" 22 "Reserved" 21 "100%" 20 "95%" 19 "90%" 18 "85%" 17 "80%" 16 "75%" 15 "70%" 14 "65%" 13 "60%" 12 "55%" 11 "50%" 10 "45% " 9 "40% " 8 "35% " 7 "30% " 6 "25% " 5 "20% " 4 "15% " 3 "10% " 2 "5% " 1 "0% " 0 "Not active " ;
VAL_ 1058 SCUP_1_PsngrSeatLegSprtCurr 15 "Reserved" 14 "Reserved" 13 "Reserved" 12 "Reserved" 11 "100%" 10 "90% " 9 "80% " 8 "70% " 7 "60% " 6 "50% " 5 "40% " 4 "30% " 3 "20% " 2 "10% " 1 "0% " 0 "Not active " ;
VAL_ 1058 SCUP_1_PsngrSeatLegSprtPosnTar 15 "Reserved" 14 "Reserved" 13 "Reserved" 12 "Reserved" 11 "100%" 10 "90% " 9 "80% " 8 "70% " 7 "60% " 6 "50% " 5 "40% " 4 "30% " 3 "20% " 2 "10% " 1 "0% " 0 "Not active " ;
VAL_ 1058 SCUP_1_PsngrSeatLvlPosnStsTar 15 "Reserved" 14 "Reserved" 13 "Reserved" 12 "Reserved" 11 "100%" 10 "90% " 9 "80% " 8 "70% " 7 "60% " 6 "50% " 5 "40% " 4 "30% " 3 "20% " 2 "10% " 1 "0% " 0 "Not active " ;
VAL_ 1058 SCUP_1_PsngrSeatHeiPosnStsTar 15 "Reserved" 14 "Reserved" 13 "Reserved" 12 "Reserved" 11 "100%" 10 "90% " 9 "80% " 8 "70% " 7 "60% " 6 "50% " 5 "40% " 4 "30% " 3 "20% " 2 "10% " 1 "0% " 0 "Not active " ;
VAL_ 1170 SCU_2_SeatLegSpprtPosnStsTar 15 "Reserved" 14 "Reserved" 13 "Reserved" 12 "Reserved" 11 "100%" 10 "90% " 9 "80% " 8 "70% " 7 "60% " 6 "50% " 5 "40% " 4 "30% " 3 "20% " 2 "10% " 1 "0% " 0 "Not active " ;
VAL_ 1170 SCU_2_SeatLvlPosnStsTar 15 "Reserved" 14 "Reserved" 13 "Reserved" 12 "Reserved" 11 "100%" 10 "90% " 9 "80% " 8 "70% " 7 "60% " 6 "50% " 5 "40% " 4 "30% " 3 "20% " 2 "10% " 1 "0% " 0 "Not active " ;
VAL_ 1170 SCU_2_SeatHdrestHeiAdjmt 15 "Reserved" 14 "Reserved" 13 "Reserved" 12 "Reserved" 11 "100%" 10 "90% " 9 "80% " 8 "70% " 7 "60% " 6 "50% " 5 "40% " 4 "30% " 3 "20% " 2 "10% " 1 "0% " 0 "Not active " ;
VAL_ 1170 SCU_2_BackrAgPosnStsTar 31 "Reserved" 30 "Reserved" 29 "Reserved" 28 "Reserved" 27 "Reserved" 26 "Reserved" 25 "Reserved" 24 "Reserved" 23 "Reserved" 22 "Reserved" 21 "100%" 20 "95%" 19 "90%" 18 "85%" 17 "80%" 16 "75%" 15 "70%" 14 "65%" 13 "60%" 12 "55%" 11 "50%" 10 "45% " 9 "40% " 8 "35% " 7 "30% " 6 "25% " 5 "20% " 4 "15% " 3 "10% " 2 "5% " 1 "0% " 0 "Not active " ;
VAL_ 1170 SCU_2_SeatCushPosnSts 15 "Reserved" 14 "Reserved" 13 "Reserved" 12 "Reserved" 11 "100%" 10 "90% " 9 "80% " 8 "70% " 7 "60% " 6 "50% " 5 "40% " 4 "30% " 3 "20% " 2 "10% " 1 "0% " 0 "Not active " ;
VAL_ 1170 SCU_2_SeatHeiPosnStsTar 15 "Reserved" 14 "Reserved" 13 "Reserved" 12 "Reserved" 11 "100%" 10 "90% " 9 "80% " 8 "70% " 7 "60% " 6 "50% " 5 "40% " 4 "30% " 3 "20% " 2 "10% " 1 "0% " 0 "Not active " ;
VAL_ 924 SteeringAngleSpeedValidData 1 " Not Valid" 0 " Valid" ;
VAL_ 924 SteeringAngleValidData 1 " Not Valid" 0 " Valid" ;
VAL_ 924 SASCalibrated 1 " Calibrated" 0 " Not calibrated" ;
VAL_ 924 AngleFailure 1 " Failure" 0 " No Failure" ;
VAL_ 1203 BSD_text 7 " Reserved" 6 " Reserved" 5 " no?display" 4 " Closing Vehicle Warning" 3 " Blind spot monitor system failure(Right)" 2 " Blind spot monitor system failure(Left)" 1 "Blind spot monitor sensor block(Right)" 0 " Blind spot monitor sensor block(Left)" ;
VAL_ 1203 RCTA_WarningRH 3 "Reserved" 2 "Reserved" 1 "ON" 0 "OFF" ;
VAL_ 1203 TimeOut_BSDR 1 "Reserved" 0 "Reserved" ;
VAL_ 1203 RRCR_1_ObjTyp 3 " Not Used" 2 " Two wheels vehicle " 1 " Four wheels vehicle " 0 "  Invalid" ;
VAL_ 1203 RRCR_1_BlkSts 1 " Blockage" 0 " Not Blockage" ;
VAL_ 1203 RRCR_1_DOWWarn 3 " Not Used" 2 " Level2 Warning " 1 " Level1 Warning " 0 " No Warning" ;
VAL_ 1203 RRCR_1_RCTAWarn 1 " Warning" 0 " No Warning" ;
VAL_ 1203 RRCR_1_BSDWarn 3 " Not Used" 2 " Critical Warning" 1 " Standard Warning" 0 " No Warning" ;
VAL_ 1203 RRCR_1_SysSt 3 " System Error" 2 " Temporary Error" 1 " On" 0 " Off" ;
VAL_ 1075 RLCR_2_RCTBONOFFSts 3 " Reserved" 2 " OFF" 1 " ON" 0 " Not active" ;
VAL_ 1075 RLCR_2_RAEBONOFFSts 3 " Reserved" 2 " OFF" 1 " ON" 0 " Not active" ;
VAL_ 1201 STAT_RCTBEnable 3 "Reserved" 2 "Reserved " 1 "Enable " 0 "Disable" ;
VAL_ 1201 DOW_Status 7 "Reserved" 6 "Reserved" 5 "Blockage" 4 "Faulty" 3 "Active" 2 "Standby" 1 "Initialization" 0 "OFF" ;
VAL_ 1201 RCW_Status 7 "Reserved" 6 "RCW Reversing Active" 5 "Blockage" 4 "Faulty" 3 "Active" 2 "Standby" 1 "Initialization" 0 "OFF" ;
VAL_ 1201 STAT_DOWWarningMode 3 "Invalid" 2 "LED with chime" 1 "LED only" 0 "No Warning" ;
VAL_ 1201 STAT_CVWWarningMode 3 "Invalid" 2 "LED with chime" 1 "LED only" 0 "No Warning" ;
VAL_ 1201 RCTA_WarningLH 3 "Reserved" 2 "Reserved" 1 "ON" 0 "OFF" ;
VAL_ 1201 CVW_Warning 3 "Reserved" 2 "Reserved" 1 "ON" 0 "OFF" ;
VAL_ 1201 CVW_Status 7 "Reserved" 6 "Reserved" 5 "Blockage" 4 "Faulty" 3 "CVW Active" 2 "Standby" 1 "Initialization" 0 "OFF" ;
VAL_ 1201 BSD_Status 7 "Reserved" 6 "Reserved" 5 "Blockage" 4 "Faulty" 3 "Active" 2 "Standby" 1 "Initialization" 0 "Disable" ;
VAL_ 1201 RCTA_Status 7 "Reserved" 6 "Reserved" 5 "Blockage" 4 "Faulty" 3 "Active" 2 "Standby" 1 "Initialization" 0 "Disable" ;
VAL_ 1201 STAT_RCWWarningMode 3 "Reserved" 2 "LED with chime" 1 "LED only" 0 "No Warning" ;
VAL_ 1201 STAT_BSDWarningMode 3 "Invalid" 2 "LED with chime" 1 "LED only" 0 "No Warning" ;
VAL_ 1201 RLCR_1_ObjTyp 3 " Not Used" 2 " Two wheels vehicle " 1 " Four wheels vehicle " 0 "  Invalid" ;
VAL_ 1201 RLCR_1_RCWWarn 3 " Not Used" 2 " Level2 Warning " 1 " Level1 Warning " 0 " No Warning" ;
VAL_ 1201 RLCR_1_DOWWarn 3 " Not Used" 2 " Level2 Warning " 1 " Level1 Warning " 0 " No Warning" ;
VAL_ 1201 RLCR_1_RCWONOFFSts 3 " Reserved" 2 " OFF" 1 " ON" 0 " Not active" ;
VAL_ 1201 RLCR_1_DOWONOFFSts 3 " Reserved" 2 " OFF" 1 " ON" 0 " Not active" ;
VAL_ 1201 RLCR_1_BSDLCARCTAONOFFSts 3 " Reserved" 2 " OFF" 1 " ON" 0 " Not active" ;
VAL_ 1201 RLCR_1_RCTAWarn 1 " Warning" 0 " No Warning" ;
VAL_ 1201 RLCR_1_BlkSts 1 " Blockage" 0 " Not Blockage" ;
VAL_ 1201 RLCR_1_RAEBWarn 1 " Warning" 0 " No Warning" ;
VAL_ 1201 RLCR_1_RCTBWarn 1 " Warning" 0 " No Warning" ;
VAL_ 1201 RLCR_1_BSDWarn 3 " Not Used" 2 " Critical Warning" 1 " Standard Warning" 0 " No Warning" ;
VAL_ 1201 RLCR_1_SysSt 3 " System Error" 2 " Temporary Error" 1 " On" 0 " Off" ;
VAL_ 1032 RCCP_1_InhbSts 1 " On" 0 " OFF" ;
VAL_ 1208 PPMISt 3 " External error" 2 " PPMI internal error" 1 " PPMI initialization" 0 " PPMI no error" ;
VAL_ 1208 PPMICounter 1 " Count is full" 0 " Count not full" ;
VAL_ 1208 PPMI_1_BSRBPASts 3 " Reserved" 2 " OFF" 1 " ON" 0 " Not active" ;
VAL_ 1208 PPMI_1_HWSts 3 " Reserved" 2 " OFF" 1 " ON" 0 " Not active" ;
VAL_ 1042 PEPS_BLTKey_PESts 1 " ON" 0 " OFF                    " ;
VAL_ 1042 WelcomLightPollingSts 1 " Open" 0 " Close                       " ;
VAL_ 1042 PEPS_IntelligentOpenSts 1 " Open" 0 " Close                          " ;
VAL_ 1042 PEPSPollingSts 1 " Open" 0 " Close                           " ;
VAL_ 998 RemoteStartSts 2 " Remote start mode" 1 " Normal start mode" 0 " No start" ;
VAL_ 998 Start_StopRequest 6 " Reserved" 5 " Reserved" 4 " Remote stop request" 3 " Remote start request" 2 " Normal stop request" 1 " Normar start request" 0 " Not request" ;
VAL_ 998 IDInformation 7 " Transmitter BLT3" 6 " Transmitter BLT2" 5 " Transmitter BLT1" 4 " Transmitter 4" 3 " Transmitter 3" 2 " Transmitter 2" 1 " Transmitter 1" ;
VAL_ 998 PEPS_1_IDInformation_2 7 " Transmitter BLT3                                                                       0x8: Transmitter NFC1                                                                               0x9: Transmitter NFC2                                               " 6 " Transmitter BLT2" 5 " Transmitter BLT1" 4 " Transmitter 4" 3 " Transmitter 3" 2 " Transmitter 2" 0 " Not Used                                                                                    0x1: Transmitter 1" ;
VAL_ 1125 OBC_ChgSts_PHEV 7 "Reserved" 6 "Reserved" 5 "Discharge finished" 4 "Discharging" 3 "Charge stop" 2 "Chargefinished" 1 "Charging" 0 "No charge" ;
VAL_ 1125 OBC_ChgSts 7 "Discharge finished" 6 "Discharging" 5 "Heat finished" 4 "Heating" 3 "Charge_Dis_Heat stop" 2 "Chargefinished" 1 "Charging" 0 "No charge" ;
VAL_ 1125 OBC_ElectronicLockSts 1 "Lock" 0 "Unlock" ;
VAL_ 1125 OBC_3_Dchasts 1 "ON" 0 "OFF" ;
VAL_ 1125 OBC_CC_ConnectSts 4 " Partial Connected" 3 " Error" 2 " V2L" 1 " Charge Connected" 0 " Not Connected" ;
VAL_ 1124 NFC_1_DispCardPosn 1 " active" 0 " not active" ;
VAL_ 1124 NFC_1_IDList 7 " NFC1&NFC2&NFC3" 6 " NFC2&NFC3    " 5 " NFC1&NFC3    " 4 " NFC1&NFC2    " 3 " NFC3" 2 " NFC2" 1 " NFC1" 0 "Not active" ;
VAL_ 1124 NFC_1_ID 3 "Transmitter NFC3 " 2 " Transmitter NFC2" 1 " Transmitter NFC1" 0 " No NFC" ;
VAL_ 850 HCU_13_EngSelfMaiTin 1 " Active" 0 " NoActive" ;
VAL_ 1195 HCU_6_G_PwrdwnDisReq 1 " Request" 0 " No Request" ;
VAL_ 1195 HCU_6_G_VehStrtWarn 1 " Request warning" 0 " No request" ;
VAL_ 1142 HCU_BrkPsd 1 " Request" 0 " No request" ;
VAL_ 1142 CruiseControlStsForDisplay 3 " Cancel" 2 " Pre cruise (flash)" 1 " Inserted" 0 " Not inserted" ;
VAL_ 1142 HCU_4_G_ForcedPrkgChrg 1 " Active" 0 " Not Active" ;
VAL_ 1142 HCU_4_G_EDrvOnly 1 " Active" 0 " Not Active" ;
VAL_ 1142 FuelTankLidSts 1 " Open" 0 " Close" ;
VAL_ 1046 HCU_EgyReGenIndcrB 1 " On" 0 " Off" ;
VAL_ 1046 HCU_HvSysFltStopReq 1 " Request" 0 " No Request" ;
VAL_ 1046 HCU_PowerLimit 1 " On" 0 " Off" ;
VAL_ 1046 HCU_OTAHvReqSts 3 " Reserved" 2 " Fail" 1 " Success" 0 " No Command" ;
VAL_ 1046 HCU_OTAModSts 3 " Reserved" 2 " Reserved" 1 " Active" 0 " InActive" ;
VAL_ 1046 HCU_ShowRoomRunngreason 15 " Reserved" 14 " Reserved" 13 " Reserved" 12 " Reserved" 11 " Reserved" 10 " Reserved" 9 " Reserved" 8 " Reserved" 7 " Reserved" 6 " Reserved" 5 " Reserved" 4 " Reserved" 3 " Reserved" 2 " Reserved" 1 " Reserved" 0 " Reserved" ;
VAL_ 1046 HCU_ShowRoomRunngSts 3 " Reserved" 2 " Reserved" 1 " Positive" 0 " Negative" ;
VAL_ 1044 HCU_2_G_DchaFail 1 "not discharge conditions" 0 "Discharge conditions" ;
VAL_ 1044 HCU_2_G_ChrgnFctMemSt 3 " Reserved" 2 " No Remember" 1 " Remember " 0 " Not Active" ;
VAL_ 1044 HCU_2_G_LowBatteryLowFuelInfo 1 "Request" 0 " No Request" ;
VAL_ 1044 HCU_2_G_LowBatteryInfo 1 "Request" 0 " No Request" ;
VAL_ 1044 HCU_2_G_HighTempLimit 1 "limit" 0 "No limit" ;
VAL_ 1044 HCU_2_G_DchaFault 1 " Fault" 0 " No Fault" ;
VAL_ 1044 HCU_GearReturnWarn 1 " Warning" 0 " No Warning" ;
VAL_ 1044 HCU_ChargeFault 1 " Fault" 0 " No Fault" ;
VAL_ 1044 PRNDGearAct 7 "Reserved" 6 "Reserved" 5 "Reserved" 0 " Init" ;
VAL_ 1044 HCU_SetSOCFed 7 " Reserved" 6 " Reserved" 5 " 72%" 4 " 64%" 3 " 56%" 2 " 48%" 1 " 40% " 0 " 30%" ;
VAL_ 1044 HCU_SocManageFed 7 " Reserved" 6 " Reserved" 5 " Reserved" 4 " Reserved" 3 " Charge" 2 " Auto" 1 " SAVE " 0 " Default" ;
VAL_ 1044 HCU_RegenerateLevel 3 " Reserved" 2 " low level" 1 " middle level " 0 " high level" ;
VAL_ 1044 HCU_EnergyFlow 31 "Reserved" 30 "Reserved" 29 "Reserved" 28 "Reserved" 27 "Reserved" 26 "Reserved" 25 "Reserved" 24 "Reserved" 23 "Reserved" 22 "Reserved" 21 "Reserved" 20 "Reserved" 19 "Reserved" 18 "Reserved" 17 "Reserved" 16 "Reserved" 15 "Charge" 14 "4WD_ReGenerateBrake" 13 "2WD_ReGenerateBrake" 12 "Parking_Generate" 11 "Running_Generate" 10 "Engine" 9 "4WD_Parallel" 8 "2WD_Parallel" 7 "4WD_ExtendRangeCharge" 6 "4WD_ExtendRangeDisCharge" 5 "2WD_ExtendRangeCharge" 4 "2WD_ExtendRangeDisCharge" 3 "4WD_EV" 2 "2WD_EV" 1 "Ready" 0 "OFF" ;
VAL_ 1034 HCU_HighTempLimit 1 "limit" 0 "No limit" ;
VAL_ 1034 HCU_PowerModeChangeFail 1 " FAIL" 0 " NOT FAIL" ;
VAL_ 1034 HCU_PowertrainFault 1 " Fault" 0 " No Fault" ;
VAL_ 1034 HCU_PowerModeFed 3 " EV+" 2 " HEV                                     " 1 " EV " 0 " Not Active                                   " ;
VAL_ 1034 HCU_PTReady 1 " LmpON" 0 " LmpOFF" ;
VAL_ 1034 HCU_HVReady 1 " LmpON" 0 " LmpOFF" ;
VAL_ 1218 LHM_1_DBL_FaultSts 1 " Fault" 0 " Not Fault" ;
VAL_ 1218 LHM_1_DRLFaildSts 1 " Failure" 0 " Normal" ;
VAL_ 1218 LHM_1_LHTurnLiFaildSts 1 " Failure" 0 " Normal" ;
VAL_ 1218 LHM_1_ParkLiFaildSts 1 " Failure" 0 " Normal" ;
VAL_ 1218 LHM_1_LoBeamFaildSts 1 " Failure" 0 " Normal" ;
VAL_ 1218 LHM_1_HiBeamFaildSts 1 " Failure" 0 " Normal" ;
VAL_ 1218 LHM_1_ADBenable_Feedback 1 " enable" 0 " disenable" ;
VAL_ 1218 LHM_1_ADBSts 3 " Fault" 2 " Active" 1 " Standby" 0 " ADB Off" ;
VAL_ 1175 BrakesystemFailSts 1 "  Fail present" 0 "  Fail not present" ;
VAL_ 1175 TwofeetBrakeSts 1 "  Twofeet Brake Occur" 0 "  Normal" ;
VAL_ 1175 BrakeFluidSts 3 "  Not used" 2 "  Electric_error" 1 "  Empty" 0 "  Normal" ;
VAL_ 1175 FWAWarningSts 3 "  Not used" 2 "  BrakeSys High Temperature Leve2" 1 "  BrakeSys High Temperature Leve1" 0 "  No failure" ;
VAL_ 1175 CST_SensitivitySts 3 " Reserved" 2 " Comfort Level 2" 1 " Comfort Level 1 " 0 " Not Active" ;
VAL_ 1175 BrakepedalFeelSts 3 " Reserved" 2 " Reserved" 1 " Sport" 0 " Comfort" ;
VAL_ 1175 CST_Status 3 " CST is Failure" 2 " CST is Active" 1 " CST is Standby" 0 " CST is disabled" ;
VAL_ 1175 IPB_AssociWithDriverModeSts 1 "  ON" 0 "  OFF" ;
VAL_ 906 IDCU_12_RmninfoTrig 3 "Reserved" 2 "Reset" 1 "Set" 0 " Not active" ;
VAL_ 906 IDCU_12FCTAWarnRi 1 " Warning" 0 " No Warning" ;
VAL_ 906 IDCU_12FCTAWarnLe 1 " Warning" 0 " No Warning" ;
VAL_ 906 IDCU_12CPMod 15 " Reserved" 13 " Reserved" 12 " Reserved" 11 " Reserved" 10 " Failure mode" 9 " safe stop mode" 8 " NOC lateral override mode" 7 " CP lateral override mode" 6 " NOC Active-Control mode" 5 " NOC Reday mode" 4 " NOC cancel mode" 3 " CP Active-Control mode" 2 " CP Reday mode" 1 " CP cancel mode" 0 " No display mode" ;
VAL_ 906 IDCU_12Rmninfo 79 " Reserved" 78 " Reserved" 77 " Reserved" 76 " Reserved" 75 " Reserved" 74 " Reserved" 73 " Reserved" 72 " Reserved" 71 " Reserved" 70 " Reserved" 69 " Reserved" 68 " Reserved" 67 " Reserved" 66 " Reserved" 65 " Reserved" 64 " Reserved" 63 " Reserved" 62 " Reserved" 61 " Reserved" 60 " Reserved" 59 " Reserved" 58 " Reserved" 57 " Reserved" 56 " Reserved" 55 "Reserved" 54 " Reserved" 53 " Reserved" 52 "Reserved" 51 "Reserved" 50 "Reserved" 49 "Reserved" 48 "Reserved" 47 "DCLC is right condition not meeted to left" 46 "CP is active" 45 "ACC is active" 44 " Confirm to change to turn to right lane" 43 " Confirm to change to turn to left lane" 42 " Longitudinal override info" 41 " ELK is in error mode" 40 " LDP is in error mode" 39 " CP is in error mode" 38 " FCW is switched on" 37 " FCW is switched off " 36 " lateral override info" 35 " NOC is changing to turn to right lane" 34 " NOC is changing to turn to left lane" 33 " NOC is going to change to turn to Right lane" 32 " NOC is going to change to turn to left lane" 31 " NOC is going to entrance ramp" 30 " FCW is in error mode" 29 " ACC is in error mode" 28 " AEB is in error mode " 27 " AEB is switched on" 26 " AEB is switched off" 25 " LDW is in error mode" 24 " BSD is in error mode" 23 " Not take over after long time" 22 " Take over info Level3" 21 " Take over info Level1" 20 " Take over info Level1" 19 " NOC is going to exit soon" 18 " DCLC condition not meeted" 17 " Unable to change lane as vehicle speed limit" 16 " unable to active CP" 15 " CP is cancelled" 14 " Radar Error ADAS not available" 13 " Camera Error ADAS not available" 12 " ACC is stand-wait" 11 " Drive Away Info Active" 10 " FCW is active" 9 " Unable to active FCW" 8 " Radar is in error mode" 7 " Camera is in error mode" 6 " Camera is covered" 5 " Radar is covered" 4 "AEB is active" 3 " unable to active AEB" 2 " unable to active ACC" 1 "ACC is cancelled" 0 "No display" ;
VAL_ 1248 IDCU_11_ALCDrvStysts 3 " Reserved" 2 " Jacobinical" 1 " Moderate" 0 " Gentle" ;
VAL_ 1248 IDCU_11_ALCDrvrCfmONOFFsts 3 " reserved" 2 " Confirm Not Necessary" 1 " Confirm Necessary" 0 " Not active" ;
VAL_ 1248 IDCU_11_CPONOFFsts 3 " reserved" 2 " switch on" 1 " switch off" 0 " Not active" ;
VAL_ 1248 IDCU_11_NOCONOFFsts 3 " reserved" 2 " switch on" 1 " switch off" 0 " Not active" ;
VAL_ 1248 IDCU_11_HPAONOFFsts 3 "reserved" 2 "switch on" 1 "switch off" 0 "Not active" ;
VAL_ 1248 IDCU_11_ParkingchimeVoice 7 "Reserved" 6 "Reserved" 5 "ParkingchimeVoice5" 4 "ParkingchimeVoice4" 3 "ParkingchimeVoice3" 2 "ParkingchimeVoice2" 1 "ParkingchimeVoice1" 0 "Not Request" ;
VAL_ 1248 IDCU_11_FCTBONOFFsts 3 " reserved" 2 " switch on" 1 " switch off" 0 " Not active" ;
VAL_ 1248 IDCU_11_SpeedLmtNmberE 63 " reserved" 62 " reserved" 61 " reserved" 60 " reserved" 59 " reserved" 58 " reserved" 41 "20%" 40 "19%" 39 "18%" 38 "17%" 37 "16%" 36 "15%" 35 "14%" 34 "13%" 33 "12%" 32 "11%" 31 "10%" 30 "9%" 29 "8%" 28 "7%" 27 "6%" 26 "5%" 25 "4%" 24 "3%" 23 "2%" 22 "1%" 21 "0%" 20 "-1%" 19 "-2%" 18 "-3%" 17 "-4%" 16 "-5%" 15 "-6%" 14 "-7%" 13 "-8%" 12 "-9%" 11 "-10% " 10 "-11%" 9 "-12%" 8 "-13%" 7 "-14%" 6 "-15%" 5 "-16%" 4 "-17%" 3 "-18%" 2 "-19%" 1 "-20%" 0 "No display" ;
VAL_ 1248 IDCU_11_SpeedLmtNmberAb 63 "reserved" 62 "reserved" 61 "reserved" 60 "reserved" 59 "reserved" 58 "reserved" 57 "reserved" 56 "reserved" 55 "reserved" 54 "reserved" 53 "reserved" 52 "reserved" 51 "reserved" 50 "reserved" 49 "reserved" 48 "reserved" 47 "reserved" 46 "reserved" 45 "reserved" 44 "reserved" 43 "reserved" 42 "reserved" 41 "reserved" 40 "reserved" 39 "reserved" 38 "reserved" 37 "reserved" 36 "reserved" 35 "reserved" 34 "reserved" 33 "reserved" 32 "reserved" 31 "reserved" 30 "reserved" 29 "reserved" 28 "reserved" 27 "reserved" 26 "reserved" 25 "reserved" 24 "reserved" 23 "reserved" 22 "reserved" 21 "10" 10 "-1" 9 "-2" 8 "-3" 7 "-4" 6 "-5" 5 "-6" 4 "-7" 3 "-8" 2 "-9" 1 "-10" 0 "No display" ;
VAL_ 1248 IDCU_11_VoiceRem 3 "Reserved" 2 "Brief" 1 "Standard" 0 "Not active" ;
VAL_ 1248 IDCU_11_DrvAssiStylests 3 " self-defined" 2 " Old Driver" 1 " New Driver" 0 " Not active" ;
VAL_ 1248 IDCU_11_DCLCONOFFsts 3 " reserved" 2 " switch on" 1 " switch off" 0 " Not active" ;
VAL_ 903 FCM_FRM_6_AEBMode 3 " Failure mode" 2 " Active mode" 1 " On mode" 0 " OFF mode" ;
VAL_ 903 FCM_FRM_6_FCWMode 3 " Failure mode" 2 " Active mode" 1 " On mode" 0 " OFF mode" ;
VAL_ 903 FCM_FRM_6_HMI_Indicator 3 " Active" 2 " Failure" 1 " OFF" 0 " No response" ;
VAL_ 903 FCM_FRM_6_TakeOverReq 1 " Requst" 0 " No Requst" ;
VAL_ 903 FCM_FRM_6_FCW_preWarning 1 " Warning" 0 " No warning" ;
VAL_ 903 FCM_FRM_6_DistanceWarning 1 " Warning" 0 " No warning" ;
VAL_ 903 FCM_FRM_6_TimeGapSetICM 7 " Reserved" 6 " Reserved" 5 " TauGap_5" 4 " TauGap_4" 3 " TauGap_3" 2 " TauGap_2" 1 " TauGap_1" 0 " No Display" ;
VAL_ 903 FCM_FRM_6_DrvrCfmSCFDispFb 1 " confirmed" 0 " not confirmed" ;
VAL_ 903 FCM_FRM_6_SCF_SpdLimUnit 3 " Reserved" 2 " Reserved" 1 " MPH" 0 " KMH" ;
VAL_ 903 FCM_FRM_6_SCF_SpdLimSts 7 " Reserved" 6 " Reserved" 5 " Reserved" 4 " IREVERSIBLE_FAILURE" 3 " REVERSIBLE_FAILURE" 2 " ACTIVE" 1 " STANDBY" 0 " OFF" ;
VAL_ 903 FCM_FRM_6_SCF_PopoverReq 1 " Driver confirm Request" 0 " No Request" ;
VAL_ 903 FCM_FRM_6_ACCMode 15 " Reserved" 14 " Reserved" 13 " Reserved" 12 " Reserved" 11 " Reserved" 10 " Reserved" 9 " Failure mode" 8 " Reserved/OFF mode" 7 " Override" 6 " Stand-wait" 5 " Stand-active" 4 "Brake-Only mode" 3 " Active-Control mode" 2 " Ready mode" 1 " Passive mode" 0 " Initial Mode" ;
VAL_ 903 FCM_FRM_6_Textinfo_Info 15 " Reserved" 14 " Reserved" 13 " Reserved" 12 " FCW is active" 11 " Unable to active FCW" 10 " FCW is switched on" 9 " FCW is switched off " 8 " AEB is active" 7 " Unable to switched on AEB" 6 " AEB is switched on" 5 " AEB is switched off" 4 " Drive Away Information Active" 3 " ACC is stand-wait" 2 " Unable to active ACC" 1 " ACC is cancelled" 0 " No Display" ;
VAL_ 903 FCM_FRM_6_TextinfoWarn 15 " Reserved" 14 " Reserved" 13 " Reserved" 12 " Reserved" 11 " Reserved" 10 " Reserved" 9 " Reserved" 8 " Reserved" 7 " Reserved" 6 " Radar is in error mode" 5 " FCW is in error mode" 4 " Radar is covered" 3 " AEB is in error mode " 2 " ACC is in error mode" 1 " Driver take over" 0 " No Display" ;
VAL_ 1251 TextinfoWarn 15 " hands off warning2" 14 " hands off warning1" 13 " FCTB system defect" 12 " RCTB system defect" 11 " MEB system defect" 10 " AEB temporary unavailable" 9 " ELK and RDP deactive" 8 " The car in front has pulled away" 7 " RCTB Active,Please Take Over Steering Wheel" 6 " Rear Emergency Braking System Activated" 5 " FCTB Active,Please Take Over Steering Wheel" 4 " Please Take Over The Vehicle Driving With Caution" 3 "Camera temporary failure" 2 "  camera temporarily blindness" 1 " camera blocked" 0 " No Display" ;
VAL_ 1251 Textinfo_Info 2 " AEB error" 1 " AEB temporary unavailable" 0 " No Display" ;
VAL_ 1251 FCM_FRM_5_DAIONOFFSts 3 " Reserved" 2 " OFF" 1 " ON" 0 " Not active" ;
VAL_ 1251 FCM_FRM_5_SCFONOFFSts 3 " Reserved" 2 " OFF" 1 " ON" 0 " Not active" ;
VAL_ 1251 FCM_FRM_5_FCWONOFFSts 3 " Reserved" 2 " OFF" 1 " ON" 0 " Not active" ;
VAL_ 1251 FCM_FRM_5_FCWSnvtySts 3 " far" 2 " near" 1 " standard" 0 " Not active" ;
VAL_ 1251 FCM_FRM_5_AEBONOFFSts 3 " Reserved" 2 " OFF" 1 " ON" 0 " Not active" ;
VAL_ 1020 FCM_10_ELKIntvMod 7 " Reserved" 6 " Reserved" 5 " Reserved" 4 " Reserved" 3 " ELK Overtaking" 2 " ELK Oncoming" 1 " ELK Road Edge or Solid Line" 0 " Not active" ;
VAL_ 1020 FCM_10_WarnModSts 3 " voice and shock" 2 " only shock " 1 " only voice" 0 " Not active" ;
VAL_ 1020 FCM_10_SLAONOFFSts 3 " Reserved" 2 " OFF" 1 " ON" 0 " Not active" ;
VAL_ 1020 FCM_10_TJAICAExitTextInfoSts 3 " Reserved" 2 " OFF" 1 " ON" 0 " Not active" ;
VAL_ 1020 FCM_10_LDPTJAELKTakeoverReq 3 " Suppressed" 2 " Take Over Safty" 1 " Take Over Warning" 0 " Not Active" ;
VAL_ 1020 FCM_10_TSINoParkWarn 1 " Active" 0 " Not Active" ;
VAL_ 1020 FCM_10_ELKSysSts 7 " Reserved" 6 " Reserved" 5 " Reserved" 4 " Fault" 3 " Active_startup " 2 " Active_standby" 1 " Suppressed" 0 " OFF" ;
VAL_ 1020 FCM_10_TJAICAEnaRcmend 1 " Demand" 0 " No demand" ;
VAL_ 1020 FCM_10_TJAICATextinfo 7 " Reserved" 6 " TJA/ICA is exit reminder" 5 " TJA/ICA is in error mode" 4 " TJA/ICA is active" 3 " Unable to active TJA/ICA" 2 " TJA/ICA is switched on" 1 " TJA/ICA is switched off" 0 " No display" ;
VAL_ 1020 FCM_10_LDWSysSts 7 " Reserved" 6 " Reserved" 5 " Reserved" 4 " Fault" 3 " Active_startup " 2 " Active_standby" 1 " Suppressed" 0 " OFF" ;
VAL_ 1020 FCM_10_LDPSysSts 7 " Reserved" 6 " Reserved" 5 " Reserved" 4 " Fault" 3 " Active_startup " 2 " Active_standby" 1 " Suppressed" 0 " OFF" ;
VAL_ 1020 FCM_10_TLITrfcLi 3 " Red" 2 " Yellow" 1 " Green" 0 " No Display" ;
VAL_ 1020 FCM_10_TSISgnLongStayDisp 15 " Reserved" 14 " Reserved" 13 " Reserved" 12 " Reserved" 11 " Reserved" 10 " Reserved" 9 " Reserved" 8 " Malaysia no overtaking" 7 " Australian No parking" 6 " Australian prohibiting standing and parking" 5 " Australian no overtaking" 4 " Prohibiting Standing And Parking" 3 " No Parking" 2 " End Of No Overtaking" 1 " No Overtaking" 0 " No Display" ;
VAL_ 1020 FCM_10_TLISysSts 3 " Fault" 2 " Active" 1 " Standby" 0 " OFF" ;
VAL_ 1020 FCM_10_TSISysSts 3 " Reserved" 2 " Fault" 1 " On" 0 " OFF" ;
VAL_ 1020 FCM_10_TSISgnForb 15 " ENCAP_NOentry" 14 " ENCAP_Vehicle Categories" 13 " ENCAP_Arrows" 12 " ENCAP_Distance for/in" 11 " ENCAP_Time/Season" 10 " ENCAP_Snow/Icy" 9 " ENCAP_Rain/Wetness" 8 " Australian prohibiting U-turning" 7 " Australian prohibiting turning right" 6 " Australian prohibiting turning left" 5 " No entry" 4 " Prohibiting Motor Vehicle Entering" 3 " Prohibiting U-turning" 2 " Prohibiting turning right" 1 " Prohibiting turning left" 0 " No Display" ;
VAL_ 1020 FCM_10_TSISgnGiWay 15 " Reserved" 14 " ENCAP_Yield Signs" 13 " ENCAP_Stop Signs" 12 " ENCAP_Traffic_Lights" 11 " Malaysia stop sign" 10 " Australian stop sign" 9 " Australian yield sign2" 8 " Australian yield sign1" 7 " Australian watch for pedestrians" 6 " Yield Sign" 5 " Stop Sign" 4 " Warn Merger" 3 " Warn Road Work" 2 " Warn Kids" 1 " Watch For Pedestrians " 0 " No Display" ;
VAL_ 1245 FCM_5_SLAmodeSWSet 3 " Reserved" 2 " Relative" 1 " Absolute" 0 " Not active" ;
VAL_ 1245 FCM_5_SpeedLmtNmberE 63 " reserved" 62 " reserved" 61 " reserved" 60 " reserved" 59 " reserved" 58 " reserved" 41 "20%" 40 "19%" 39 "18%" 38 "17%" 37 "16%" 36 "15%" 35 "14%" 34 "13%" 33 "12%" 32 "11%" 31 "10%" 30 "9%" 29 "8%" 28 "7%" 27 "6%" 26 "5%" 25 "4%" 24 "3%" 23 "2%" 22 "1%" 21 "0%" 20 "-1%" 19 "-2%" 18 "-3%" 17 "-4%" 16 "-5%" 15 "-6%" 14 "-7%" 13 "-8%" 12 "-9%" 11 "-10% " 10 "-11%" 9 "-12%" 8 "-13%" 7 "-14%" 6 "-15%" 5 "-16%" 4 "-17%" 3 "-18%" 2 "-19%" 1 "-20%" 0 "No display" ;
VAL_ 1245 FCM_5_SpeedLmtNmberAb 63 "reserved" 62 "reserved" 61 "reserved" 60 "reserved" 59 "reserved" 58 "reserved" 57 "reserved" 56 "reserved" 55 "reserved" 54 "reserved" 53 "reserved" 52 "reserved" 51 "reserved" 50 "reserved" 49 "reserved" 48 "reserved" 47 "reserved" 46 "reserved" 45 "reserved" 44 "reserved" 43 "reserved" 42 "reserved" 41 "reserved" 40 "reserved" 39 "reserved" 38 "reserved" 37 "reserved" 36 "reserved" 35 "reserved" 34 "reserved" 33 "reserved" 32 "reserved" 31 "reserved" 30 "reserved" 29 "reserved" 28 "reserved" 27 "reserved" 26 "reserved" 25 "reserved" 24 "reserved" 23 "reserved" 22 "reserved" 21 "10" 10 "-1" 9 "-2" 8 "-3" 7 "-4" 6 "-5" 5 "-6" 4 "-7" 3 "-8" 2 "-9" 1 "-10" 0 "No display" ;
VAL_ 1245 SLASpdlimitWarningAudSWSts 3 " Reserved" 2 " OFF" 1 " ON" 0 " Not active" ;
VAL_ 1245 SLASpdLimChgAudSwSts 3 " Reserved" 2 " OFF" 1 " ON" 0 " Not active" ;
VAL_ 1245 SLWFONOFFSts 3 " Reserved" 2 " OFF" 1 " ON" 0 " Not active" ;
VAL_ 1245 FCM_5_ELKONOFFSts 3 " Reserved" 2 " OFF" 1 " ON" 0 " Not active" ;
VAL_ 1245 FCM_5_LDWLDPSnvtySts 3 " Reserved" 2 " HighSensitivity" 1 " LowSensitivity" 0 " Not active" ;
VAL_ 1245 FCM_5_LDPONOFFSts 3 " Reserved" 2 " OFF" 1 " ON" 0 " Not active" ;
VAL_ 1245 FCM_5_WarnModSts 3 " voice and shock" 2 " only shock " 1 " only voice" 0 " Not active" ;
VAL_ 1245 FCM_5_LDWONOFFSts 3 " Reserved" 2 " OFF" 1 " ON" 0 " Not active" ;
VAL_ 1245 FCM_5_TLIONOFFSts 3 " Reserved" 2 " OFF" 1 " ON" 0 " Not active" ;
VAL_ 1245 FCM_5_TSIONOFFSts 3 " Reserved" 2 " OFF" 1 " ON" 0 " Not active" ;
VAL_ 1245 FCM_5_HMAONOFFSts 3 " Reserved" 2 " OFF" 1 " ON" 0 " Not active" ;
VAL_ 1245 FCM_5_IESONOFFSts 3 " Reserved" 2 " OFF" 1 " ON" 0 " Not active" ;
VAL_ 1245 FCM_5_SLAONOFFSts 3 " Reserved" 2 " OFF" 1 " ON" 0 " Not active" ;
VAL_ 1245 FCM_5_TJAICAExitTextInfoSts 3 " Reserved" 2 " OFF" 1 " ON" 0 " Not active" ;
VAL_ 775 SLASpdlimitWarningAud 1 " Active" 0 " Not Active" ;
VAL_ 775 SLASpdlimitWarningVis 1 " Active" 0 " Not Active" ;
VAL_ 775 SLASpdlimitUnknownWarning 3 " Reserved" 2 " Reserved" 1 " Active" 0 " Not Active" ;
VAL_ 775 FCM_2_SLASpdlimitUnits 3 " Reserved" 2 " MPH" 1 " KMH" 0 " Unknown" ;
VAL_ 775 TJA_ICA_ON_OFF_sts 1 "On" 0 "Off" ;
VAL_ 775 TJA_ICA_mode 7 " Reserved" 6 " Reserved" 5 " Reserved" 4 " Reserved" 3 " Failure mode" 2 " Active mode" 1 " Standby mode" 0 " OFF mode" ;
VAL_ 775 Camera_textinfo 3 " Reserved" 2 " Camera blocked" 1 " Camera failure" 0 " Camera normal" ;
VAL_ 775 FCM_2_SpdLimtyp 3 " Reserved" 2 " National SpeedLimit" 1 " Conditional Unconfirmed" 0 " No Conditional" ;
VAL_ 775 SLASpdlimit 255 " SPL_Unconfirmed" 254 " Reserved" 253 " Reserved" 252 " Reserved" 251 " Reserved" 250 " Reserved" 249 " Reserved" 248 " Reserved" 247 " Reserved" 246 " Reserved" 245 " Reserved" 244 " Reserved" 243 " Reserved" 242 " Reserved" 241 " Reserved" 240 " Reserved" 239 " Reserved" 238 " Reserved" 237 " Reserved" 236 " Reserved" 235 " Reserved" 234 " Reserved" 233 " Reserved" 232 " Reserved" 231 " Reserved" 230 " Reserved" 229 " Reserved" 228 " Reserved" 227 " Reserved" 226 " Reserved" 225 " Reserved" 224 " Reserved" 223 " Reserved" 222 " Reserved" 221 " Reserved" 220 " Reserved" 219 " Reserved" 218 " Reserved" 217 " Reserved" 216 " Reserved" 215 " Reserved" 214 " Reserved" 213 " Reserved" 212 " Reserved" 211 " Reserved" 210 " Reserved" 209 " Reserved" 208 " Reserved" 207 " Reserved" 206 " Reserved" 205 " Reserved" 204 " Reserved" 203 " Reserved" 202 " Reserved" 201 " Reserved" 200 " Reserved" 199 " Reserved" 198 " Reserved" 197 " Reserved" 196 " Reserved" 195 " Reserved" 194 " Reserved" 193 " Reserved" 192 " Reserved" 191 " Reserved" 190 " Reserved" 189 " Reserved" 188 " Reserved" 187 " Reserved" 186 " Reserved" 185 " Reserved" 184 " Reserved" 183 " Reserved" 182 " Reserved" 181 " Reserved" 180 " Reserved" 179 " Reserved" 178 " Reserved" 177 " Reserved" 176 " Reserved" 175 " Reserved" 174 " Reserved" 173 " Reserved" 172 " Reserved" 171 " Reserved" 170 " Reserved" 169 " Reserved" 168 " Reserved" 167 " Reserved" 166 " Reserved" 165 " Reserved" 164 " Reserved" 163 " Reserved" 162 " Reserved" 161 " Reserved" 160 " Reserved" 159 " Reserved" 158 " Reserved" 157 " Reserved" 156 " Reserved" 155 " Reserved" 154 " Reserved" 153 " Reserved" 152 " Reserved" 151 " Reserved" 150 " Reserved" 149 " Reserved" 148 " Reserved" 147 " Reserved" 146 " Reserved" 145 " Reserved" 144 " Reserved" 143 " Reserved" 142 " Reserved" 141 " Reserved" 140 " Reserved" 139 " Reserved" 138 " Reserved" 137 " Reserved" 136 " Reserved" 135 " Reserved" 134 " Reserved" 133 " Reserved" 132 " Reserved" 131 " Reserved" 130 " Reserved" 129 " Reserved" 128 " Reserved" 127 " Reserved" 126 " Reserved" 125 " Reserved" 124 " Reserved" 123 " Reserved" 122 " Reserved" 121 " Reserved" 120 " Reserved" 119 " Reserved" 118 " Reserved" 117 " Reserved" 116 " Reserved" 115 " Reserved" 114 " Reserved" 113 " Reserved" 112 " Reserved" 111 " Reserved" 110 " Reserved" 109 " Reserved" 108 " Reserved" 107 " Reserved" 106 " Reserved" 105 " Reserved" 104 " Reserved" 103 " Reserved" 102 " Reserved" 101 " Reserved" 100 " Reserved" 99 " Reserved" 98 " Reserved" 97 " Reserved" 96 " Reserved" 95 " Reserved" 94 " Reserved" 93 " Reserved" 92 " Reserved" 91 " Reserved" 90 " Reserved" 89 " Reserved" 88 " Reserved" 87 " Reserved" 86 " Reserved" 85 " Reserved" 84 " Reserved" 83 " Reserved" 82 " Reserved" 81 " Reserved" 80 " Reserved" 79 " Reserved" 78 " Reserved" 77 " Reserved" 76 " Reserved" 75 " Reserved" 74 " Reserved" 73 " Reserved" 72 " Reserved" 71 " Reserved" 70 " Reserved" 69 " Reserved" 68 " Reserved" 67 " Reserved" 66 " Reserved" 65 " Reserved" 64 " Reserved" 63 " Reserved" 62 " Reserved" 61 " Reserved" 60 " Reserved" 59 " Reserved" 58 " Reserved" 57 " Reserved" 56 " Reserved" 55 " Reserved" 54 " Reserved" 53 " Reserved" 52 " Reserved" 51 " Reserved" 50 " Reserved" 49 " Reserved" 48 " Reserved" 47 " Reserved" 46 " Reserved" 45 " Reserved" 44 " Reserved" 43 " Reserved" 42 " Reserved" 41 " Reserved" 40 " Reserved" 39 " Reserved" 38 " Reserved" 37 " SPL 180" 36 " SPL 175" 35 " SPL 170" 34 " SPL 165" 33 " SPL 160" 32 " SPL 155" 31 " SPL 150" 30 " SPL 145" 29 " SPL 140" 28 " SPL 135" 27 " SPL 130" 26 " SPL 125" 25 " SPL 120" 24 " SPL 115" 23 " SPL 110" 22 " SPL 105" 21 " SPL 100" 20 " SPL 95" 19 " SPL 90" 18 " SPL 85" 17 " SPL 80" 16 " SPL 75" 15 " SPL 70" 14 " SPL 65" 13 " SPL 60" 12 " SPL 55" 11 " SPL 50" 10 " SPL 45" 9 " SPL 40" 8 " SPL 35" 7 " SPL 30" 6 " SPL 25" 5 " SPL 20" 4 " SPL 15" 3 " SPL10" 2 " SPL 5" 1 " SPL Cancelled" 0 " No Display" ;
VAL_ 775 FCM_2_SLAmodeSWSet 3 " Reserved" 2 " Relative" 1 " Absolute" 0 " Not active" ;
VAL_ 775 SLASpdlimitWarning 1 " Active" 0 " Not Active" ;
VAL_ 775 FCM_2_SCFSpdlimWarn 1 " Active" 0 " Not Active" ;
VAL_ 775 SLAState 7 " Reserved" 6 " Reserved" 5 " Reserved" 4 " Defect" 3 " Navigation only mode" 2 " Vision mode" 1 " Fusion mode" 0 " Off" ;
VAL_ 775 LDW_ELK_TJA_LDPRightVisuali 3 " Warning" 2 " Intervention" 1 " Line tracking" 0 " No display" ;
VAL_ 775 FCM_2_ISAState 7 " Reserved" 6 " Reserved" 5 " Reserved" 4 " Reserved" 3 " SLWF Aud Off" 2 " SLWF Off" 1 " ISA Off " 0 " No display" ;
VAL_ 775 LDW_ELK_TJA_LDPLeftVisuali 3 " Warning" 2 " Intervention" 1 " Line tracking" 0 " No display" ;
VAL_ 775 HMA_HighbeamReq 1 " High beam request" 0 " No request" ;
VAL_ 775 HMA_Status 7 " Reserved" 6 " Reserved" 5 " Reserved" 4 " Reserved" 3 " Fault" 2 " Active" 1 " Standby" 0 " Off" ;
VAL_ 1270 Yellowwarning 3 " Not used" 2 " Lamp on" 1 " Lamp flash" 0 " Lamp off" ;
VAL_ 1270 Redwarning 3 " Not used" 2 " Lamp on" 1 " Lamp flash" 0 " Lamp off" ;
VAL_ 1270 RWUActive 1 " Active" 0 " Not Active" ;
VAL_ 1270 EPBWarningMessage 7 " Not Used" 6 " Not Used" 5 " Not Used" 4 " Not Used" 3 " Large slope parking" 2 " Close the LHF door" 1 " Press the brake pedal first,then release the EPB button" 0 " Off" ;
VAL_ 1270 EPBStatus 7 " Not Used" 6 " Not Used" 5 " Error" 4 " Unknown / Initial" 3 " Applying" 2 " Releasing" 1 " Applied" 0 " Released" ;
VAL_ 896 EPS_EOTLearning_Sts 1 " Not Learnt" 0 " Learnt" ;
VAL_ 896 EPSSteeringAngleCalibrationSts 1 " No calibration or no initialization" 0 " Calibration is fine" ;
VAL_ 896 EPSFailSts 1 " Fail present" 0 " Not present" ;
VAL_ 896 EPS_AssociWithDriverModeSts 1 "ON" 0 "OFF" ;
VAL_ 896 EPS_AssistanceStyle_Sts 3 " Reserved" 2 " Reserved" 1 " Light" 0 " Heavy" ;
VAL_ 1057 BrakePedalSts 0 " Not applied" 1 " Applied" ;
VAL_ 1057 BrakePedalStsValidData 0 " Valid" 1 " Not Valid" ;
VAL_ 1057 GasPedalPositionInvalidData 1 " Invalid" 0 " Valid" ;
VAL_ 1057 LimitSpeedSts 5 " Kickdown" 4 " Cancel" 3 " Limit" 2 " Overspeed" 1 " Standby" 0 " Off" ;
VAL_ 640 OilPressureWarningLamp 1 " On" 0 " Off" ;
VAL_ 640 EMS_EngineSts_Actual 1 " Run" 0 " Not Run" ;
VAL_ 640 GearReduceIndication 0 " Not active" 1 " Active" ;
VAL_ 640 GearRaiseIndication 0 " Not active" 1 " Active" ;
VAL_ 640 TargetGearPosition 7 " Invalid" 6 " 6th gear" 5 " 5th gear" 4 " 4th gear" 3 " 3rd gear" 2 " 2nd gear" 1 " 1st gear" ;
VAL_ 640 EPCSts 0 " Off" 1 " Active" ;
VAL_ 640 EngineSpeedValidData 1 " Not valid" 0 " Valid" ;
VAL_ 640 FuelRollingCounterValidData 1 " Not valid" 0 " Valid" ;
VAL_ 640 ISS_Sts_GS 30 " Reserved" 29 " Reserved" 28 " Reserved" 27 " Reserved" 26 " Reserved" 25 " Reserved" 24 " Reserved" 23 " Reserved" 22 " Reserved" 21 " Reserved" 20 " Reserved" 19 " MHEV_AlarmFault " 18 " ISS_TurnOn" 17 " ISS_TurnOff " 16 " ISS_AlarmFault " 15 " ISS_AlarmStartByHand              " 14 " ISS_AlarmNeutral" 13 " ISS_ExitInfo2" 12 " ISS_ExitInfo" 11 " ISS_OnSeatCheck " 10 " ISS_NoStartBelt" 9 " ISS_AutoStart" 8 " ISS_NoStopBrake" 7 " ISS_NoStopHood " 6 " ISS_NoStopDoor" 5 " ISS_NoStopAC " 4 " ISS_NoStopBelt " 3 " ISS_AutoStop " 2 " ISS_StopEnable " 1 " ISS_EOL" 0 " ISS_DefaultOn                              " ;
VAL_ 640 CruiseControlStsForDisplay 3 " Cancel" 2 " Pre cruise (flash)" 1 " Inserted" 0 " Not inserted" ;
VAL_ 640 ECSControlSts 1 " Heating£¨lamp flash" 0 " No heating£¨lamp off" ;
VAL_ 640 EngineCoolantTempertureFailSts 1 " Fail Present" 0 " Fail Not Present" ;
VAL_ 640 MILSts 3 " Not used" 2 " Active" 1 " Not used" 0 " Off" ;
VAL_ 640 IEMSts 0 " Lamp Off" 1 " Lamp On" ;
VAL_ 640 GPFWarning 3 " Reserved" 2 " GPF Overlimited" 1 " GPF Full" 0 " No GPF warning" ;
VAL_ 640 EngineSts 0 " Not Run" 1 " Run" ;
VAL_ 640 SSMStatus 6 " Auto Stopping" 5 " Operation" 4 " Engine Restart" 3 " Starter Restart" 2 " Stopped" 1 " Standby" 0 " Reset/Not Implemented" ;
VAL_ 1291 Pos3_FragranceSts_sec 3 "Shortage" 2 "Unfilled" 1 "Used up" 0 "Normal" ;
VAL_ 1291 Pos2_FragranceSts_sec 3 "Shortage" 2 "Unfilled" 1 "Used up" 0 "Normal" ;
VAL_ 1291 Pos1_FragranceSts_sec 3 "Shortage" 2 "Unfilled" 1 "Used up" 0 "Normal" ;
VAL_ 1277 CLM_10_SteerWhlHeatgSwt 1 " Active" 0 " Not active" ;
VAL_ 1277 CLM_WindowCmd 31 " Not used" 30 " Not used" 29 " Not used" 28 " Not used" 27 " Not used" 26 " Not used" 25 " Not used" 24 " Not used" 23 " Not used" 22 " Not used" 21 " Not used" 20 " Not used" 19 " Not used" 18 " Not used" 17 " Not used" 16 " Not used" 15 " All  Windows comfort" 14 " All  Windows close" 13 " All Windows open" 12 " Rear Windows close" 11 " Rear Windows open" 10 " Front Windows close" 9 " Front Windows open" 8 " RRWindow close" 7 " RRWindow open" 6 " RLWindow close" 5 " RLWindow open" 4 " FRWindow close" 3 " FRWindow open" 2 " FLWindow close" 1 " FLWindow open" 0 " Not active" ;
VAL_ 1277 AUTODefrostlevelSts 3 "high" 2 "middle" 1 "low" 0 "Off" ;
VAL_ 1277 CLM_10_FRSeatVentilationCmd 7 " Reserved" 6 " Reserved" 5 " Reserved" 4 " Seat Ventilation Level3" 3 " Seat Ventilation Level2" 2 " Seat Ventilation Level1" 1 " OFF" 0 " Not Active" ;
VAL_ 1277 CLM_10_FLSeatVentilationCmd 7 " Reserved" 6 " Reserved" 5 " Reserved" 4 " Seat Ventilation Level3" 3 " Seat Ventilation Level2" 2 " Seat Ventilation Level1" 1 " OFF" 0 " Not Active" ;
VAL_ 1277 CLM_10_FRSeatHeatLevelCmd 7 " Reserved" 6 " Reserved" 5 " Reserved" 4 " Seat heating Level3" 3 " Seat heating Level2" 2 " Seat heating Level1" 1 " OFF" 0 " Not Active" ;
VAL_ 1277 CLM_10_FLSeatHeatLevelCmd 7 " Reserved" 6 " Reserved" 5 " Reserved" 4 " Seat heating Level3" 3 " Seat heating Level2" 2 " Seat heating Level1" 1 " OFF" 0 " Not Active" ;
VAL_ 1277 CLM_10_CLMIntlgDeodnSts 1 " ON" 0 " OFF" ;
VAL_ 1277 CLM_10_CLMSupHeatgSts 1 " ON" 0 " OFF" ;
VAL_ 1277 CLM_10_CLMSupCoolgSts 1 " ON" 0 " OFF" ;
VAL_ 1277 CLM_10_SeRowDispSts 1 " Active" 0 " Not active" ;
VAL_ 1277 CLM_10_RfgtLkDispSts 1 " Active" 0 " Not active" ;
VAL_ 1277 CLM_10_ReRowDispSts 1 " Active" 0 " Not active" ;
VAL_ 1277 CLM_10_ReRowBlowSpdLvlSts 7 " Level  7" 6 " Level  6" 5 " Level  5" 4 " Level  4" 3 " Level  3" 2 " Level  2" 1 " Level  1" 0 " Not Active" ;
VAL_ 1277 CLM_10_ReRowWorkSts 1 " Active" 0 " Not active" ;
VAL_ 1277 CLM_10_RmnDispSts 7 " Reserved" 6 " Reserved" 5 " Reserved" 4 " Reserved" 3 " Note3" 2 " Note2" 1 " Note1 " 0 " Not Active" ;
VAL_ 1277 CLM_10_AQSDispSts 1 " Active" 0 " Not active" ;
VAL_ 1277 SelfTestResult2 39 "Right temperature sensor fault" 38 "UV sterilization error (Reserved )" 37 "Fragrance communication error " 36 "Fragrance fan fault " 35 "Fragrance motor error" 34 "Right anion  error " 33 "Left anion  error " 32 "PTC  fault(Reserved)" 25 "Rear Booster error" 24 "External PM2.5  error " 23 "Incar PM2.5  error " 22 "Right mixture motor error" 15 "Left mixture motor error" 14 "Rear Booster Mode motor  error" 13 "Mode motor 1 error" 12 "Circulation motor error" 11 "Blower error" 10 "Left temperature sensor fault  " 9 "Frag motor error" 8 "Evaporator temperature sensor errorevaporator" 7 "AQS sensor error" 6 "Humidity sensor error" 5 "Right solar error" 4 "Left solar error" 3 "Frag Lost Communication With CLM" 2 "Left internal temperature error" 1 "External temperature error" 0 "No error,the system operates well" ;
VAL_ 1277 IntelligentCustomSts 1 " ON" 0 " Off" ;
VAL_ 1277 CLM_10_SeRowWorkSts 1 " Active" 0 " Not Active" ;
VAL_ 1277 CLM_10_SeRowBlowSpdLvlDispSts 7 " Level  7" 6 " Level  6" 5 " Level  5" 4 " Level  4" 3 " Level  3" 2 " Level  2" 1 " Level  1" 0 " Not Active" ;
VAL_ 1277 PtcHeatgSts 1 " ON" 0 " OFF" ;
VAL_ 1171 CLM_6_CbnAntiOverHeatSts 0 "Not Active                                                                                                              0x1:Close                                                                                                                        0x2:No " ;
VAL_ 1171 CLM_6_warn_sts 1 "off" 0 "on" ;
VAL_ 1171 AQSAutoRunSts 1 "on" 0 "off" ;
VAL_ 1334 FragranCeconsistenceLevelSts 7 " Not used" 6 " Not used" 5 " Level5" 4 " Level4" 3 " Level3" 2 " Level2" 1 " Level1" 0 " Not used" ;
VAL_ 1334 Pos3_FragranceTypesSts 7 " Reserved" 6 " Unfilled" 5 " Reserved" 4 " Used up                    " 3 " Type3" 2 " Type2                              " 1 " Type1  " 0 " Not active   " ;
VAL_ 1334 Pos2_FragranceTypesSts 7 " Reserved" 6 " Unfilled                           " 5 " Reserved" 4 " Used up                            " 3 " Type3" 2 " Type2                              " 1 " Type1  " 0 " Not active   " ;
VAL_ 1334 PM2_5AutoRunSetSts 1 " Off" 0 " On " ;
VAL_ 1334 PM2_5_Incar_Level 7 " Reserved" 6 " Reserved" 5 " Serious pollution" 4 " High levels of pollution" 3 " Moderate pollution" 2 " Light pollution" 1 " Favorable pollution" 0 " Good" ;
VAL_ 1334 PM2_5_Outcar_Level 7 " Reserved" 6 " Reserved" 5 " Serious pollution" 4 " High levels of pollution" 3 " Moderate pollution" 2 " Light pollution" 1 " Favorable pollution" 0 " Good" ;
VAL_ 1334 FragranceDisplaysts 1 " Active" 0 " Not active" ;
VAL_ 1334 FragrancePositionSwt 3 " Position three  active" 2 " Position two  active" 1 " Position one active" 0 " Not active   " ;
VAL_ 1334 ACModeCustomSts 3 " Strong" 2 " Comfortable                                      " 1 " Save" 0 " Not active  " ;
VAL_ 1334 FragranceWelcomeModeSts 1 " Off" 0 " On " ;
VAL_ 1334 RefreshFunctionSts 1 " Off" 0 " On " ;
VAL_ 1334 Pos1_FragranceTypesSts 7 " Reserved" 6 " Unfilled" 5 " Reserved" 4 " Used up" 3 " Type3" 2 " Type2" 1 " Type1" 0 " Not active" ;
VAL_ 1334 PM2_5AutoRunSts 1 " Off" 0 " On " ;
VAL_ 1334 FragranceSWSts 2 " Custom User-Defined" 1 " Off                                                                                                    " 0 " Auto/On" ;
VAL_ 1334 AutoBltCalllowBlowSpeedSts 1 " Off" 0 " On " ;
VAL_ 1334 AutoParkInnerCirculationSts 1 " Off" 0 " On " ;
VAL_ 1334 PM2_5_IncarSts 1 " failure" 0 " Normal" ;
VAL_ 1334 PM2_5_ExtSts 1 " failure" 0 " Normal" ;
VAL_ 1334 FragranceShortageWarning 7 " Position one and two and three shortage" 6 " Position two and three shortage " 5 " Position one and three shortage " 4 " Position three shortage " 3 " Position one and two shortage                             " 2 " Position two shortage" 1 " Position one shortage" 0 " No Warning" ;
VAL_ 1334 ION_Function_Sts 3 " Not used" 2 " Close " 1 " Open" 0 " No display" ;
VAL_ 1333 AUTODefrostDisplaySts 1 " Active" 0 " Not active" ;
VAL_ 1333 TempKnobRollingCounter 31 " 31(Reserved)" 30 " 30(Reserved)" 29 " 29(Reserved)" 28 " 28(Reserved)" 27 " 27(Reserved)" 26 " 26(Reserved)" 25 " 25(Reserved)" 24 " 24(Reserved)" 23 " 23(Reserved)" 22 " 22(Reserved)" 21 " 21(Reserved)" 20 " 20(Reserved)" 19 " 19(Reserved)" 18 " 18(Reserved)" 17 " 17(Reserved)" 16 " 16" 15 " 15" 14 " 14" 13 " 13" 12 " 12" 11 " 11" 10 " 10" 9 " 9" 8 " 8" 7 " 7" 6 " 6" 5 " 5" 4 " 4" 3 " 3" 2 " 2" 1 " 1" 0 " Not Active" ;
VAL_ 1333 BlowSpeedLevelDisplaySts 15 " Level  15" 14 " Level  14" 13 " Level  13" 12 " Level  12" 11 " Level  11" 10 " Level  10" 9 " Level  9" 8 " Level  8" 7 " Level  7" 6 " Level  6" 5 " Level  5" 4 " Level  4" 3 " Level  3" 2 " Level  2" 1 " Level  1" 0 " Not Active" ;
VAL_ 1333 AUTODefrostForceOpenSts 1 " Active" 0 " Not active" ;
VAL_ 1333 AQSAutoRunSetSts 1 " On" 0 " Off" ;
VAL_ 1333 AQSSts 1 " On" 0 " Off" ;
VAL_ 1333 PM2_5Displaysts 1 " Active" 0 " Not active" ;
VAL_ 1333 PM2_5overproofDisplaySts 1 " Active" 0 " Not active" ;
VAL_ 1333 FiltertchangeDisplaySts 1 " Active" 0 " Not active" ;
VAL_ 1333 REARInhibitSts 1 " Inhibitt" 0 " permit" ;
VAL_ 1333 AUTODefrostOnSts 1 " On" 0 " Off" ;
VAL_ 1104 OBDDiagnosisReqInd 1 " Request" 0 " Not Request" ;
VAL_ 1183 BMSH_InsulationSts 3 "Level 3 or  Insulation Error" 2 "Level 2 or Minor leakage repair reques" 1 "Level 1 or Insulation Warning" 0 "Level 0 or Insulation OK (default)" ;
VAL_ 1183 BMSH_PackChargingThermalSt 7 " cooling(Reserved)" 6 " Balance temperature(Reserved)" 5 " ThermalError " 4 " ChargeFinish" 3 " Charging" 2 " CoolingAndCharging" 1 " Heating" 0 " None" ;
VAL_ 1103 BMS_8_PackDCChargingSt 15 "Reserved" 14 "Reserved" 13 "Reserved" 12 "Reserved" 11 "Reserved" 10 "Reserved" 9 "Fault" 8 "CoolingAndCharging" 7 " Cooling" 6 " Balance temperature" 5 " ThermalError " 4 " ChargeFinish" 3 " Charging" 2 " HeatingAndCharging" 1 " Heating" 0 " None" ;
VAL_ 1103 BMS_8_CC2Sts 1 "Connected" 0 "No Connect" ;
VAL_ 1103 BMSH_LeftChargeTime 1 "charging maintain" ;
VAL_ 1083 BMSH_BattFaultLampSts 1 "Lamp ON" 0 "Lamp OFF" ;
VAL_ 1083 BMSH_PackThermalRunawayLight 1 "Lamp ON" 0 "Lamp OFF" ;
VAL_ 1228 BMSH_CC2_ConnectSts 3 "Invalid" 2 "Partial connected" 1 "Connected" 0 "Not connected" ;
VAL_ 1228 BMSH_CC_ConnectDischarSts 3 "Invalid" 2 "Partial connected" 1 "Connected" 0 "Not connected" ;
VAL_ 1228 BMSH_CC_ConnectSts 3 "Invalid" 2 "Partial connected" 1 "Connected" 0 "Not connected" ;
VAL_ 1228 BMSH_KeepwarmSts 3 "KeepWarm finished" 2 "KeepWarming Abort" 1 "KeepWarming" 0 "None" ;
VAL_ 1228 BMSH_KeepwarmFunctSts 1 "ON" 0 "OFF" ;
VAL_ 1228 BMSH_ElectronicLockSts 4 "Elock error" 3 "Unlock error" 2 "Lock error" 1 "Lock" 0 "Unlock" ;
VAL_ 1228 BMSH_PreWarmDis 2 "keepwarm state" 1 "preheat state" 0 "none" ;
VAL_ 1228 BMSH_PackchgSTS 5 "Stop Charge" 4 "ThermalCharging" 3 "ChargeAbort" 2 "ChargeComplete" 1 "PakingCharging" 0 "No Charging" ;
VAL_ 1287 BDM_LightMainSwitchSts 4 "LowBeamSwitch Position" 3 "PositionLampSwitch Position" 2 "Auto Position " 1 "Off Position" 0 "Not active" ;
VAL_ 1287 BDM_RearMirrorFoldSts 1 "Fold" 0 "UnFold" ;
VAL_ 1287 DriverSeatMsgStr_LvlSts 3 "High" 2 "Middle" 1 "Low" 0 "OFF/Intial" ;
VAL_ 1287 DriverSeatMsg_ModeSts 5 "Jump Mode" 4 "Relieve Mode" 3 "Cross Mode" 2 "Cat Paw Mode" 1 "Wave Mode" 0 "Initial" ;
VAL_ 1287 BCM_22_WelcomelampSts 3 " Not Used" 2 " mode2" 1 " mode1" 0 " OFF" ;
VAL_ 1287 BCM_22_WiprSnvtySetFb 7 " Reserved" 6 " Reserved" 5 " Reserved" 4 " Level4" 3 " Level3" 2 " Level2" 1 " Level1" 0 " Not Active" ;
VAL_ 1287 BCM_22_Rool_OperateSts 7 " Half open" 6 " Open" 5 " Closing" 4 " Stop" 3 " Opening" 2 " Close" 1 " Reserved" 0 " StartUp" ;
VAL_ 1287 PassSeatMsgStr_LvlSts 3 "High" 2 "Middle" 1 "Low" 0 "OFF" ;
VAL_ 1287 PassSeatMsg_ModeSts 5 "Jump Mode" 4 "Relieve Mode" 3 "Cross Mode" 2 "Cat Paw Mode" 1 "Wave Mode" 0 "Initial" ;
VAL_ 936 IBS_STAT_SOC 3 " Invalid" 2 " Deviation lower 10%" 1 " Deviation lower 15%" 0 " Deviation higher 15%" ;
VAL_ 934 IBS_CurrentRange 3 " Invalid" 2 " -1500,1500A" 1 " -200,200A" 0 " -1,1A" ;
SIG_GROUP_ 1175 IPB_ESP_15_Signal_Group 1 : IPB_ESP_15_CRC IPB_ESP_15_MessageCounter Reserved_Fill7 BrakesystemFailSts TwofeetBrakeSts BrakeFluidSts FWAWarningSts Reserved_Fill2 CST_SensitivitySts BrakepedalFeelSts CST_Status Reserved_Fill6 Reserved_Fill5 Reserved_Fill4 Reserved_Fill3 IPB_AssociWithDriverModeSts Reserved_Fill1;
